VERSION ""

NS_ :

BS_:

BU_: VMCU TECU OBDScanT2 IC3 EMS ECUspare2 ECUspare1 DACU CIOM BBM

BO_ 2147484474 VMCU_BB2_20P: 8 VMCU
 SG_ StartupProhibitStatus_ISig_4 : 8|2@1+ (1,0) [0|0] ""  BBM,IC3
 SG_ RampLevelStatus_ISig_4 : 32|4@1+ (1,0) [0|0] ""  IC3,CIOM
 SG_ KneelingInformation_ISig_4 : 42|4@1+ (1,0) [0|0] ""  BBM,IC3,CIOM
 SG_ FrontAxleInBumperRange_ISig_4 : 40|2@1+ (1,0) [0|0] ""  TECU
 SG_ FerryFunctionStatus_ISig_4 : 2|3@1+ (1,0) [0|0] ""  IC3,CIOM
 SG_ EngPtoConsumesTorque : 10|2@1+ (1,0) [0|0] ""  TECU
 SG_ LiftingControlModeRearAxle_ISig_ : 36|2@1+ (1,0) [0|0] ""  BBM
 SG_ KneelingStatusHMI_ISig_4 : 53|2@1+ (1,0) [0|0] ""  BBM,CIOM
 SG_ SWEngineStop_rqst_ISig_4 : 12|3@1+ (1,0) [0|0] ""  BBM
 SG_ FrontEndPositionStatus_ISig_4 : 18|3@1+ (1,0) [0|0] ""  CIOM
 SG_ LiftingControlModeFrontAxle_ISig : 30|2@1+ (1,0) [0|0] ""  BBM
 SG_ FrontAxleInBumperRange_UB_ISig_4 : 46|1@1+ (1,0) [0|0] ""  TECU,IC3
 SG_ UnevenLoadWarning_ISig_4 : 16|2@1+ (1,0) [0|0] ""  IC3
 SG_ RampHeightOutsideTargetRange_ISi : 27|3@1+ (1,0) [0|0] ""  IC3,CIOM
 SG_ DriveLevelPosUserInteraction_ISi : 48|3@1+ (1,0) [0|0] ""  IC3
 SG_ RearEndPositionStatus_ISig_4 : 24|3@1+ (1,0) [0|0] ""  TECU,CIOM
 SG_ ProhibitControlStatus_ISig_4 : 6|2@1+ (1,0) [0|0] ""  IC3,BBM
 SG_ ChangeKneelACK_ISig_4 : 51|2@1+ (1,0) [0|0] ""  CIOM
 SG_ ParkBrakeApplicationMode2 : 60|4@1+ (1,0) [0|0] ""  IC3
 SG_ RollEndPositionStatus_ISig_4 : 21|3@1+ (1,0) [0|0] ""  CIOM
 SG_ RearAxleInBumperRange_UB_ISig_4 : 47|1@1+ (1,0) [0|0] ""  TECU,IC3
 SG_ ParkBrakeReleaseMode2_ISig_4 : 56|4@1+ (1,0) [0|0] ""  IC3
 SG_ ECSStandbyAllowed_ISig_4 : 0|2@1+ (1,0) [0|0] ""  CIOM
 SG_ RearAxleInBumperRange_ISig_4 : 38|2@1+ (1,0) [0|0] ""  TECU

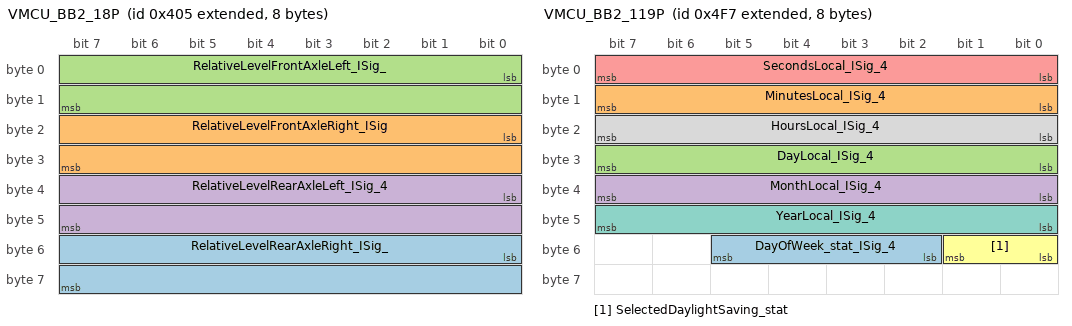
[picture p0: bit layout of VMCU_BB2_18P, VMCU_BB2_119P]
BO_ 2147484677 VMCU_BB2_18P: 8 VMCU
 SG_ RelativeLevelRearAxleRight_ISig_ : 48|16@1+ (0.1,-3200) [-3200|3353.5] "mm"  BBM
 SG_ RelativeLevelFrontAxleRight_ISig : 16|16@1+ (0.1,-3200) [-3200|3353.5] "mm"  BBM
 SG_ RelativeLevelFrontAxleLeft_ISig_ : 0|16@1+ (0.1,-3200) [-3200|3353.5] "mm"  BBM
 SG_ RelativeLevelRearAxleLeft_ISig_4 : 32|16@1+ (0.1,-3200) [-3200|3353.5] "mm"  BBM

BO_ 2147485245 VMCU_BB2_140P_FCM: 8 IC3
 SG_ VMCU_BB2_140P_FCS : 0|64@1+ (1,0) [0|0] ""  VMCU

BO_ 2147485244 VMCU_BB2_140P: 21 VMCU
 SG_ SavedUnit20_TrailerName : 0|160@1+ (1,0) [0|0] ""  IC3
 SG_ SavedUnit20_TrailerPosition : 160|3@1+ (1,0) [0|0] ""  IC3

BO_ 2147485243 VMCU_BB2_139P_FCM: 8 IC3
 SG_ VMCU_BB2_139P_FCS : 0|64@1+ (1,0) [0|0] ""  VMCU

BO_ 2147485242 VMCU_BB2_139P: 21 VMCU
 SG_ SavedUnit19_TrailerName : 0|160@1+ (1,0) [0|0] ""  IC3
 SG_ SavedUnit19_TrailerPosition : 160|3@1+ (1,0) [0|0] ""  IC3

BO_ 2147485241 VMCU_BB2_138P_FCM: 8 IC3
 SG_ VMCU_BB2_138P_FCS : 0|64@1+ (1,0) [0|0] ""  VMCU

BO_ 2147485240 VMCU_BB2_138P: 21 VMCU
 SG_ SavedUnit18_TrailerPosition : 160|3@1+ (1,0) [0|0] ""  IC3
 SG_ SavedUnit18_TrailerName : 0|160@1+ (1,0) [0|0] ""  IC3

BO_ 2147485239 VMCU_BB2_137P_FCM: 8 IC3
 SG_ VMCU_BB2_137P_FCS : 0|64@1+ (1,0) [0|0] ""  VMCU

BO_ 2147485238 VMCU_BB2_137P: 21 VMCU
 SG_ SavedUnit17_TrailerPosition : 160|3@1+ (1,0) [0|0] ""  IC3
 SG_ SavedUnit17_TrailerName : 0|160@1+ (1,0) [0|0] ""  IC3

BO_ 2147485237 VMCU_BB2_136P_FCM: 8 IC3
 SG_ VMCU_BB2_136P_FCS : 0|64@1+ (1,0) [0|0] ""  VMCU

BO_ 2147485236 VMCU_BB2_136P: 21 VMCU
 SG_ SavedUnit16_TrailerName : 0|160@1+ (1,0) [0|0] ""  IC3
 SG_ SavedUnit16_TrailerPosition : 160|3@1+ (1,0) [0|0] ""  IC3

BO_ 2147485235 VMCU_BB2_135P_FCM: 8 IC3
 SG_ VMCU_BB2_135P_FCS : 0|64@1+ (1,0) [0|0] ""  VMCU

BO_ 2147485234 VMCU_BB2_135P: 21 VMCU
 SG_ SavedUnit15_TrailerName : 0|160@1+ (1,0) [0|0] ""  IC3
 SG_ SavedUnit15_TrailerPosition : 160|3@1+ (1,0) [0|0] ""  IC3

BO_ 2147485233 VMCU_BB2_134P_FCM: 8 IC3
 SG_ VMCU_BB2_134P_FCS : 0|64@1+ (1,0) [0|0] ""  VMCU

BO_ 2147485232 VMCU_BB2_134P: 21 VMCU
 SG_ SavedUnit14_TrailerPosition : 160|3@1+ (1,0) [0|0] ""  IC3
 SG_ SavedUnit14_TrailerName : 0|160@1+ (1,0) [0|0] ""  IC3

BO_ 2147485225 VMCU_BB2_133P_FCM: 8 IC3
 SG_ VMCU_BB2_133P_FCS : 0|64@1+ (1,0) [0|0] ""  VMCU

BO_ 2147485224 VMCU_BB2_133P: 21 VMCU
 SG_ SavedUnit13_TrailerPosition : 160|3@1+ (1,0) [0|0] ""  IC3
 SG_ SavedUnit13_TrailerName : 0|160@1+ (1,0) [0|0] ""  IC3

BO_ 2147485223 VMCU_BB2_132P_FCM: 8 IC3
 SG_ VMCU_BB2_132P_FCS : 0|64@1+ (1,0) [0|0] ""  VMCU

BO_ 2147485222 VMCU_BB2_132P: 21 VMCU
 SG_ SavedUnit12_TrailerName : 0|160@1+ (1,0) [0|0] ""  IC3
 SG_ SavedUnit12_TrailerPosition : 160|3@1+ (1,0) [0|0] ""  IC3

BO_ 2147485221 VMCU_BB2_131P_FCM: 8 IC3
 SG_ VMCU_BB2_131P_FCS : 0|64@1+ (1,0) [0|0] ""  VMCU

BO_ 2147485220 VMCU_BB2_131P: 21 VMCU
 SG_ SavedUnit11_TrailerPosition : 160|3@1+ (1,0) [0|0] ""  IC3
 SG_ SavedUnit11_TrailerName : 0|160@1+ (1,0) [0|0] ""  IC3

BO_ 2147485219 VMCU_BB2_130P_FCM: 8 IC3
 SG_ VMCU_BB2_130P_FCS : 0|64@1+ (1,0) [0|0] ""  VMCU

BO_ 2147485218 VMCU_BB2_130P: 21 VMCU
 SG_ SavedUnit10_TrailerName : 0|160@1+ (1,0) [0|0] ""  IC3
 SG_ SavedUnit10_TrailerPosition : 160|3@1+ (1,0) [0|0] ""  IC3

BO_ 2147485217 VMCU_BB2_129P_FCM: 8 IC3
 SG_ VMCU_BB2_129P_FCS : 0|64@1+ (1,0) [0|0] ""  VMCU

BO_ 2147485216 VMCU_BB2_129P: 21 VMCU
 SG_ SavedUnit9_TrailerName : 0|160@1+ (1,0) [0|0] ""  IC3
 SG_ SavedUnit9_TrailerPosition : 160|3@1+ (1,0) [0|0] ""  IC3

BO_ 2147485215 VMCU_BB2_128P_FCM: 8 IC3
 SG_ VMCU_BB2_128P_FCS : 0|64@1+ (1,0) [0|0] ""  VMCU

BO_ 2147485214 VMCU_BB2_128P: 21 VMCU
 SG_ SavedUnit8_TrailerName : 0|160@1+ (1,0) [0|0] ""  IC3
 SG_ SavedUnit8_TrailerPosition : 160|3@1+ (1,0) [0|0] ""  IC3

BO_ 2147485213 VMCU_BB2_127P_FCM: 8 IC3
 SG_ VMCU_BB2_127P_FCS : 0|64@1+ (1,0) [0|0] ""  VMCU

BO_ 2147485212 VMCU_BB2_127P: 21 VMCU
 SG_ SavedUnit7_TrailerPosition : 160|3@1+ (1,0) [0|0] ""  IC3
 SG_ SavedUnit7_TrailerName : 0|160@1+ (1,0) [0|0] ""  IC3

BO_ 2147485211 VMCU_BB2_126P_FCM: 8 IC3
 SG_ VMCU_BB2_126P_FCS : 0|64@1+ (1,0) [0|0] ""  VMCU

BO_ 2147485210 VMCU_BB2_126P: 21 VMCU
 SG_ SavedUnit6_TrailerPosition : 160|3@1+ (1,0) [0|0] ""  IC3
 SG_ SavedUnit6_TrailerName : 0|160@1+ (1,0) [0|0] ""  IC3

BO_ 2147485209 VMCU_BB2_125P_FCM: 8 IC3
 SG_ VMCU_BB2_125P_FCS : 0|64@1+ (1,0) [0|0] ""  VMCU

BO_ 2147485208 VMCU_BB2_125P: 21 VMCU
 SG_ SavedUnit5_TrailerName : 0|160@1+ (1,0) [0|0] ""  IC3
 SG_ SavedUnit5_TrailerPosition : 160|3@1+ (1,0) [0|0] ""  IC3

BO_ 2147485207 VMCU_BB2_124P_FCM: 8 IC3
 SG_ VMCU_BB2_124P_FCS : 0|64@1+ (1,0) [0|0] ""  VMCU

BO_ 2147485206 VMCU_BB2_124P: 21 VMCU
 SG_ SavedUnit4_TrailerPosition : 160|3@1+ (1,0) [0|0] ""  IC3
 SG_ SavedUnit4_TrailerName : 0|160@1+ (1,0) [0|0] ""  IC3

BO_ 2147485205 VMCU_BB2_123P_FCM: 8 IC3
 SG_ VMCU_BB2_123P_FCS : 0|64@1+ (1,0) [0|0] ""  VMCU

BO_ 2147485204 VMCU_BB2_123P: 21 VMCU
 SG_ SavedUnit3_TrailerPosition : 160|3@1+ (1,0) [0|0] ""  IC3
 SG_ SavedUnit3_TrailerName : 0|160@1+ (1,0) [0|0] ""  IC3

BO_ 2147485203 VMCU_BB2_122P_FCM: 8 IC3
 SG_ VMCU_BB2_122P_FCS : 0|64@1+ (1,0) [0|0] ""  VMCU

BO_ 2147485202 VMCU_BB2_122P: 21 VMCU
 SG_ SavedUnit2_TrailerName : 0|160@1+ (1,0) [0|0] ""  IC3
 SG_ SavedUnit2_TrailerPosition : 160|3@1+ (1,0) [0|0] ""  IC3

BO_ 2147485201 VMCU_BB2_121P_FCM: 8 IC3
 SG_ VMCU_BB2_121P_FCS : 0|64@1+ (1,0) [0|0] ""  VMCU

BO_ 2147485200 VMCU_BB2_121P: 21 VMCU
 SG_ SavedUnit1_TrailerPosition : 160|3@1+ (1,0) [0|0] ""  IC3
 SG_ SavedUnit1_TrailerName : 0|160@1+ (1,0) [0|0] ""  IC3

BO_ 2147485090 VMCU_BB2_120S_FCM: 8 IC3
 SG_ VMCU_BB2_120S_FCS : 0|64@1+ (1,0) [0|0] ""  VMCU

BO_ 2147485089 VMCU_BB2_120S: 18 VMCU
 SG_ RenameTrailerAutoRqst_TrailerVIN : 0|136@1+ (1,0) [0|0] ""  IC3
 SG_ RenameTrailerAutoRqst_Request : 139|2@1+ (1,0) [0|0] ""  IC3
 SG_ RenameTrailerAutoRqst_sg_UB : 141|1@1+ (1,0) [0|0] ""  IC3
 SG_ RenameTrailerAutoRqst_Position : 136|3@1+ (1,0) [0|0] ""  IC3

BO_ 2147484941 VMCU_BB2_11P: 8 VMCU
 SG_ RSLAssistStatus : 24|3@1+ (1,0) [0|0] ""  TECU

BO_ 2147484919 VMCU_BB2_119P: 8 VMCU
 SG_ DayOfWeek_stat_ISig_4 : 50|4@1+ (1,0) [0|0] ""  IC3,CIOM
 SG_ MinutesLocal_ISig_4 : 8|8@1+ (1,0) [0|255] "min"  IC3,CIOM
 SG_ DayLocal_ISig_4 : 24|8@1+ (0.25,0) [0|63.75] "Days"  IC3,CIOM
 SG_ MonthLocal_ISig_4 : 32|8@1+ (1,0) [0|255] "Months"  IC3,CIOM
 SG_ SecondsLocal_ISig_4 : 0|8@1+ (0.25,0) [0|63.75] "s"  IC3,CIOM
 SG_ SelectedDaylightSaving_stat : 48|2@1+ (1,0) [0|0] ""  IC3
 SG_ YearLocal_ISig_4 : 40|8@1+ (1,1985) [1985|2240] "Years"  CIOM,IC3
 SG_ HoursLocal_ISig_4 : 16|8@1+ (1,0) [0|255] "h"  IC3,CIOM

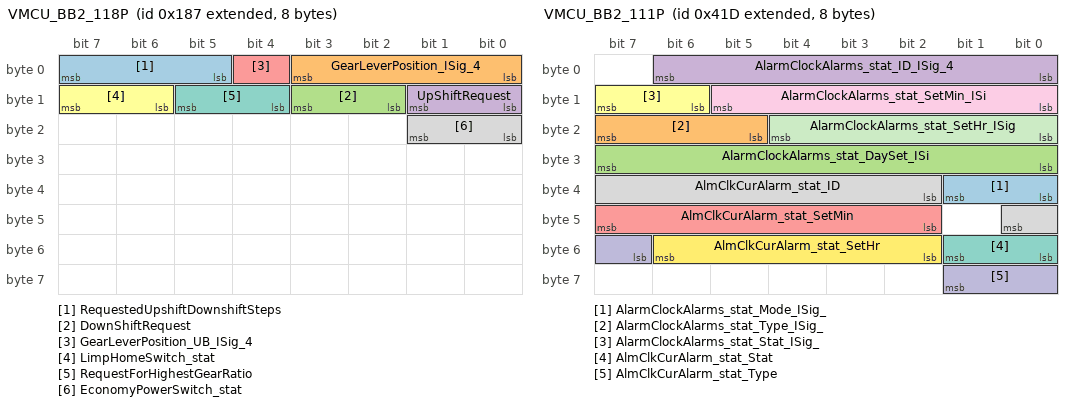
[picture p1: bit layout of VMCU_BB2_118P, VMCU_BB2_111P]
BO_ 2147484039 VMCU_BB2_118P: 8 VMCU
 SG_ RequestedUpshiftDownshiftSteps : 5|3@1+ (1,0) [0|0] ""  TECU
 SG_ GearLeverPosition_ISig_4 : 0|4@1+ (1,0) [0|0] ""  TECU,BBM,IC3
 SG_ DownShiftRequest : 10|2@1+ (1,0) [0|0] ""  TECU
 SG_ UpShiftRequest : 8|2@1+ (1,0) [0|0] ""  TECU
 SG_ GearLeverPosition_UB_ISig_4 : 4|1@1+ (1,0) [0|0] ""  BBM,IC3,TECU
 SG_ LimpHomeSwitch_stat : 14|2@1+ (1,0) [0|0] ""  TECU
 SG_ RequestForHighestGearRatio : 12|2@1+ (1,0) [0|0] ""  TECU
 SG_ EconomyPowerSwitch_stat : 16|2@1+ (1,0) [0|0] ""  TECU

BO_ 2147484975 VMCU_BB2_117P: 8 VMCU
 SG_ FuelLostInWrongGear : 0|32@1+ (0.01,0) [0|42949672.95] "l"  IC3
 SG_ FuelSavedInCoasting : 32|32@1+ (0.01,0) [0|42949672.95] "l"  IC3

BO_ 2147484974 VMCU_BB2_116S_FCM: 8 IC3
 SG_ VMCU_BB2_116S_FCS : 0|64@1+ (1,0) [0|0] ""  VMCU

BO_ 2147484969 VMCU_BB2_116S: 12 VMCU
 SG_ CalDataLoadP5_ScaleLoad : 63|16@1+ (0.5,0) [0|32767.5] "kg"  IC3
 SG_ CalDataLoadP5_UncalLoad : 47|16@1+ (0.5,0) [0|32767.5] "kg"  IC3
 SG_ CalDataLoadP5_sg_UB : 95|1@1+ (1,0) [0|0] ""  IC3
 SG_ CalDataLoadP5_YearUTC : 23|8@1+ (1,1985) [1985|2240] "Years"  IC3
 SG_ CalDataLoadP5_VehicleID : 4|3@1+ (1,0) [0|0] ""  IC3
 SG_ CalDataLoadP5_AxleID : 0|4@1+ (1,0) [0|0] ""  IC3
 SG_ CalDataLoadP5_DayUTC : 15|8@1+ (0.25,0) [0|63.75] "Days"  IC3
 SG_ CalDataLoadP5_HoursUTC : 31|8@1+ (1,0) [0|255] "h"  IC3
 SG_ CalDataLoadP5_MinutesUTC : 39|8@1+ (1,0) [0|255] "min"  IC3
 SG_ CalDataLoadP5_QF : 79|16@1+ (1,0) [0|0] ""  IC3
 SG_ CalDataLoadP5_MonthUTC : 7|8@1+ (1,0) [0|255] "Months"  IC3

BO_ 2147484973 VMCU_BB2_115S_FCM: 8 IC3
 SG_ VMCU_BB2_115S_FCS : 0|64@1+ (1,0) [0|0] ""  VMCU

BO_ 2147484968 VMCU_BB2_115S: 12 VMCU
 SG_ CalDataLoadP4_DayUTC : 7|8@1+ (0.25,0) [0|63.75] "Days"  IC3
 SG_ CalDataLoadP4_ScaleLoad : 47|16@1+ (0.5,0) [0|32767.5] "kg"  IC3
 SG_ CalDataLoadP4_sg_UB : 95|1@1+ (1,0) [0|0] ""  IC3
 SG_ CalDataLoadP4_YearUTC : 23|8@1+ (1,1985) [1985|2240] "Years"  IC3
 SG_ CalDataLoadP4_AxleID : 0|4@1+ (1,0) [0|0] ""  IC3
 SG_ CalDataLoadP4_UncalLoad : 63|16@1+ (0.5,0) [0|32767.5] "kg"  IC3
 SG_ CalDataLoadP4_VehicleID : 4|3@1+ (1,0) [0|0] ""  IC3
 SG_ CalDataLoadP4_MinutesUTC : 39|8@1+ (1,0) [0|255] "min"  IC3
 SG_ CalDataLoadP4_HoursUTC : 15|8@1+ (1,0) [0|255] "h"  IC3
 SG_ CalDataLoadP4_MonthUTC : 31|8@1+ (1,0) [0|255] "Months"  IC3
 SG_ CalDataLoadP4_QF : 79|16@1+ (1,0) [0|0] ""  IC3

BO_ 2147484972 VMCU_BB2_114S_FCM: 8 IC3
 SG_ VMCU_BB2_114S_FCS : 0|64@1+ (1,0) [0|0] ""  VMCU

BO_ 2147484967 VMCU_BB2_114S: 12 VMCU
 SG_ CalDataLoadP3_HoursUTC : 15|8@1+ (1,0) [0|255] "h"  IC3
 SG_ CalDataLoadP3_YearUTC : 7|8@1+ (1,1985) [1985|2240] "Years"  IC3
 SG_ CalDataLoadP3_MonthUTC : 39|8@1+ (1,0) [0|255] "Months"  IC3
 SG_ CalDataLoadP3_DayUTC : 23|8@1+ (0.25,0) [0|63.75] "Days"  IC3
 SG_ CalDataLoadP3_sg_UB : 95|1@1+ (1,0) [0|0] ""  IC3
 SG_ CalDataLoadP3_MinutesUTC : 31|8@1+ (1,0) [0|255] "min"  IC3
 SG_ CalDataLoadP3_QF : 79|16@1+ (1,0) [0|0] ""  IC3
 SG_ CalDataLoadP3_VehicleID : 4|3@1+ (1,0) [0|0] ""  IC3
 SG_ CalDataLoadP3_UncalLoad : 63|16@1+ (0.5,0) [0|32767.5] "kg"  IC3
 SG_ CalDataLoadP3_AxleID : 0|4@1+ (1,0) [0|0] ""  IC3
 SG_ CalDataLoadP3_ScaleLoad : 47|16@1+ (0.5,0) [0|32767.5] "kg"  IC3

BO_ 2147484971 VMCU_BB2_113S_FCM: 8 IC3
 SG_ VMCU_BB2_113S_FCS : 0|64@1+ (1,0) [0|0] ""  VMCU

BO_ 2147484966 VMCU_BB2_113S: 12 VMCU
 SG_ CalDataLoadP2_MinutesUTC : 39|8@1+ (1,0) [0|255] "min"  IC3
 SG_ CalDataLoadP2_AxleID : 0|4@1+ (1,0) [0|0] ""  IC3
 SG_ CalDataLoadP2_YearUTC : 15|8@1+ (1,1985) [1985|2240] "Years"  IC3
 SG_ CalDataLoadP2_UncalLoad : 63|16@1+ (0.5,0) [0|32767.5] "kg"  IC3
 SG_ CalDataLoadP2_DayUTC : 23|8@1+ (0.25,0) [0|63.75] "Days"  IC3
 SG_ CalDataLoadP2_MonthUTC : 7|8@1+ (1,0) [0|255] "Months"  IC3
 SG_ CalDataLoadP2_VehicleID : 4|3@1+ (1,0) [0|0] ""  IC3
 SG_ CalDataLoadP2_QF : 79|16@1+ (1,0) [0|0] ""  IC3
 SG_ CalDataLoadP2_HoursUTC : 31|8@1+ (1,0) [0|255] "h"  IC3
 SG_ CalDataLoadP2_sg_UB : 95|1@1+ (1,0) [0|0] ""  IC3
 SG_ CalDataLoadP2_ScaleLoad : 47|16@1+ (0.5,0) [0|32767.5] "kg"  IC3

BO_ 2147484970 VMCU_BB2_112S_FCM: 8 IC3
 SG_ VMCU_BB2_112S_FCS : 0|64@1+ (1,0) [0|0] ""  VMCU

BO_ 2147484965 VMCU_BB2_112S: 12 VMCU
 SG_ CalDataLoadP1_ScaleLoad : 47|16@1+ (0.5,0) [0|32767.5] "kg"  IC3
 SG_ CalDataLoadP1_YearUTC : 31|8@1+ (1,1985) [1985|2240] "Years"  IC3
 SG_ CalDataLoadP1_AxleID : 0|4@1+ (1,0) [0|0] ""  IC3
 SG_ CalDataLoadP1_MonthUTC : 39|8@1+ (1,0) [0|255] "Months"  IC3
 SG_ CalDataLoadP1_HoursUTC : 7|8@1+ (1,0) [0|255] "h"  IC3
 SG_ CalDataLoadP1_VehicleID : 4|3@1+ (1,0) [0|0] ""  IC3
 SG_ CalDataLoadP1_UncalLoad : 63|16@1+ (0.5,0) [0|32767.5] "kg"  IC3
 SG_ CalDataLoadP1_QF : 79|16@1+ (1,0) [0|0] ""  IC3
 SG_ CalDataLoadP1_DayUTC : 23|8@1+ (0.25,0) [0|63.75] "Days"  IC3
 SG_ CalDataLoadP1_sg_UB : 95|1@1+ (1,0) [0|0] ""  IC3
 SG_ CalDataLoadP1_MinutesUTC : 15|8@1+ (1,0) [0|255] "min"  IC3

BO_ 2147484701 VMCU_BB2_111P: 8 VMCU
 SG_ AlarmClockAlarms_stat_Mode_ISig_ : 32|2@1+ (1,0) [0|0] ""  CIOM,IC3
 SG_ AlarmClockAlarms_stat_Type_ISig_ : 21|3@1+ (1,0) [0|0] ""  IC3,CIOM
 SG_ AlarmClockAlarms_stat_DaySet_ISi : 24|8@1+ (1,0) [0|255] ""  IC3,CIOM
 SG_ AlarmClockAlarms_stat_ID_ISig_4 : 0|7@1+ (1,0) [0|0] ""  IC3,CIOM
 SG_ AlmClkCurAlarm_stat_SetMin : 42|6@1+ (1,0) [0|63] "min"  IC3,CIOM
 SG_ AlarmClockAlarms_stat_Stat_ISig_ : 14|2@1+ (1,0) [0|0] ""  IC3,CIOM
 SG_ AlmClkCurAlarm_stat_Stat : 48|2@1+ (1,0) [0|0] ""  CIOM,IC3
 SG_ AlmClkCurAlarm_stat_ID : 34|7@1+ (1,0) [0|0] ""  IC3,CIOM
 SG_ AlarmClockAlarms_stat_SetMin_ISi : 8|6@1+ (1,0) [0|63] "min"  IC3,CIOM
 SG_ AlmClkCurAlarm_stat_Type : 55|3@1+ (1,0) [0|0] ""  IC3,CIOM
 SG_ AlarmClockAlarms_stat_SetHr_ISig : 16|5@1+ (1,0) [0|31] "h"  CIOM,IC3
 SG_ AlmClkCurAlarm_stat_SetHr : 50|5@1+ (1,0) [0|31] "h"  IC3,CIOM

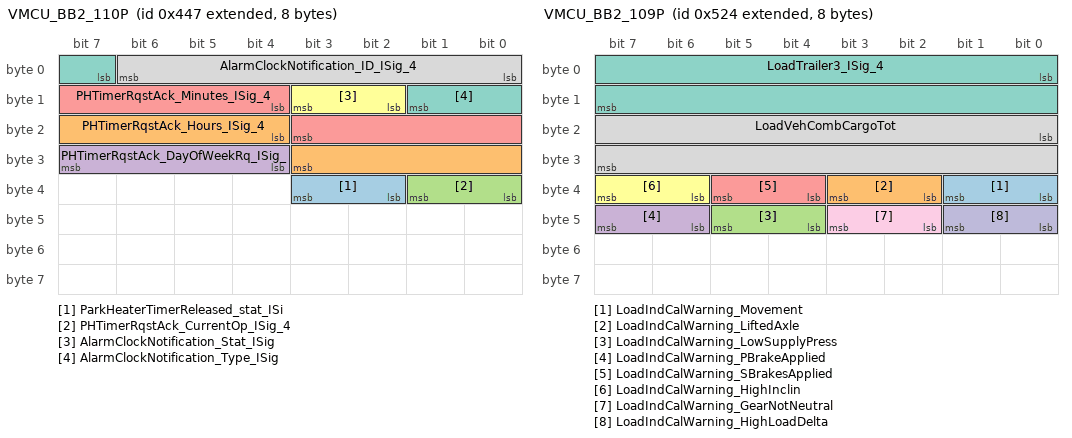
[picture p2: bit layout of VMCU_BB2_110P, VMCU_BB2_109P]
BO_ 2147484743 VMCU_BB2_110P: 8 VMCU
 SG_ ParkHeaterTimerReleased_stat_ISi : 34|2@1+ (1,0) [0|0] ""  CIOM
 SG_ PHTimerRqstAck_Hours_ISig_4 : 20|8@1+ (1,0) [0|255] "h"  CIOM
 SG_ PHTimerRqstAck_CurrentOp_ISig_4 : 32|2@1+ (1,0) [0|0] ""  CIOM
 SG_ PHTimerRqstAck_DayOfWeekRq_ISig_ : 28|4@1+ (1,0) [0|0] ""  CIOM
 SG_ PHTimerRqstAck_Minutes_ISig_4 : 12|8@1+ (1,0) [0|255] "min"  CIOM
 SG_ AlarmClockNotification_Stat_ISig : 10|2@1+ (1,0) [0|0] ""  CIOM,IC3
 SG_ AlarmClockNotification_Type_ISig : 7|3@1+ (1,0) [0|0] ""  IC3,CIOM
 SG_ AlarmClockNotification_ID_ISig_4 : 0|7@1+ (1,0) [0|0] ""  IC3,CIOM

BO_ 2147484921 VMCU_BB2_10P: 8 VMCU
 SG_ HighResolutionTripDistance2 : 32|32@1+ (5,0) [0|21474836475] "m"  IC3
 SG_ HighResolutionTripDistance1_ISig : 0|32@1+ (5,0) [0|21474836475] "m"  BBM,IC3

BO_ 2147484964 VMCU_BB2_109P: 8 VMCU
 SG_ LoadIndCalWarning_Movement : 32|2@1+ (1,0) [0|0] ""  IC3
 SG_ LoadIndCalWarning_LiftedAxle : 34|2@1+ (1,0) [0|0] ""  IC3
 SG_ LoadIndCalWarning_LowSupplyPress : 44|2@1+ (1,0) [0|0] ""  IC3
 SG_ LoadIndCalWarning_PBrakeApplied : 46|2@1+ (1,0) [0|0] ""  IC3
 SG_ LoadIndCalWarning_SBrakesApplied : 36|2@1+ (1,0) [0|0] ""  IC3
 SG_ LoadIndCalWarning_HighInclin : 38|2@1+ (1,0) [0|0] ""  IC3
 SG_ LoadTrailer3_ISig_4 : 0|16@1+ (2,0) [0|131070] "kg"  IC3,BBM,CIOM
 SG_ LoadVehCombCargoTot : 16|16@1+ (10,-40155) [-40155|615195] "kg"  BBM
 SG_ LoadIndCalWarning_GearNotNeutral : 42|2@1+ (1,0) [0|0] ""  IC3
 SG_ LoadIndCalWarning_HighLoadDelta : 40|2@1+ (1,0) [0|0] ""  IC3

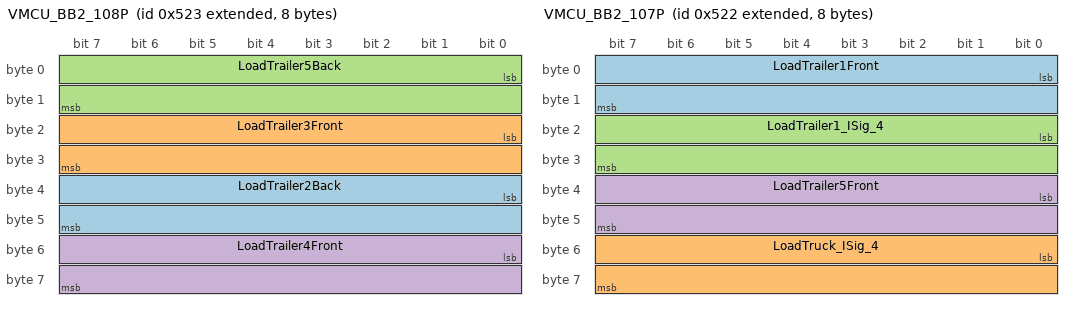
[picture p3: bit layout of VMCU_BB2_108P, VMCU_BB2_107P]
BO_ 2147484963 VMCU_BB2_108P: 8 VMCU
 SG_ LoadTrailer2Back : 32|16@1+ (2,0) [0|131070] "kg"  IC3
 SG_ LoadTrailer3Front : 16|16@1+ (2,0) [0|131070] "kg"  IC3
 SG_ LoadTrailer5Back : 0|16@1+ (2,0) [0|131070] "kg"  IC3
 SG_ LoadTrailer4Front : 48|16@1+ (2,0) [0|131070] "kg"  IC3

BO_ 2147484962 VMCU_BB2_107P: 8 VMCU
 SG_ LoadTrailer1Front : 0|16@1+ (2,0) [0|131070] "kg"  IC3
 SG_ LoadTruck_ISig_4 : 48|16@1+ (2,0) [0|131070] "kg"  IC3,CIOM,DACU,BBM
 SG_ LoadTrailer1_ISig_4 : 16|16@1+ (2,0) [0|131070] "kg"  BBM,IC3,CIOM
 SG_ LoadTrailer5Front : 32|16@1+ (2,0) [0|131070] "kg"  IC3

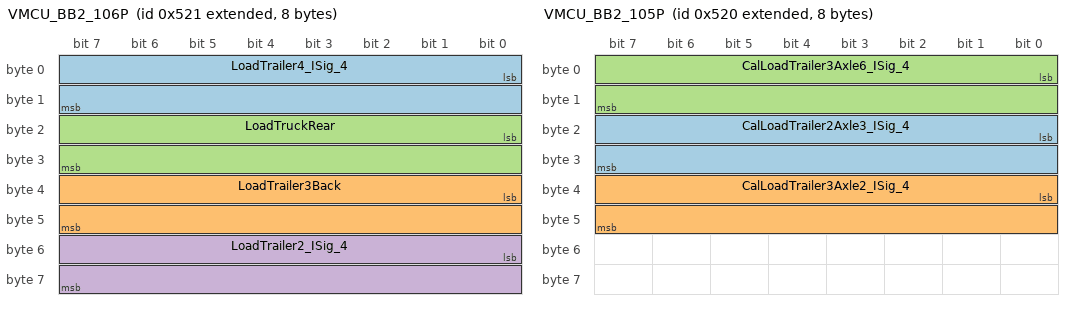
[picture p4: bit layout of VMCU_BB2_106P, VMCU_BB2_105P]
BO_ 2147484961 VMCU_BB2_106P: 8 VMCU
 SG_ LoadTrailer4_ISig_4 : 0|16@1+ (2,0) [0|131070] "kg"  IC3,BBM,CIOM
 SG_ LoadTrailer3Back : 32|16@1+ (2,0) [0|131070] "kg"  IC3
 SG_ LoadTruckRear : 16|16@1+ (2,0) [0|131070] "kg"  IC3
 SG_ LoadTrailer2_ISig_4 : 48|16@1+ (2,0) [0|131070] "kg"  BBM,CIOM,IC3

BO_ 2147484960 VMCU_BB2_105P: 8 VMCU
 SG_ CalLoadTrailer2Axle3_ISig_4 : 16|16@1+ (0.5,0) [0|32767.5] "kg"  IC3,CIOM,BBM
 SG_ CalLoadTrailer3Axle2_ISig_4 : 32|16@1+ (0.5,0) [0|32767.5] "kg"  IC3,CIOM
 SG_ CalLoadTrailer3Axle6_ISig_4 : 0|16@1+ (0.5,0) [0|32767.5] "kg"  IC3,CIOM

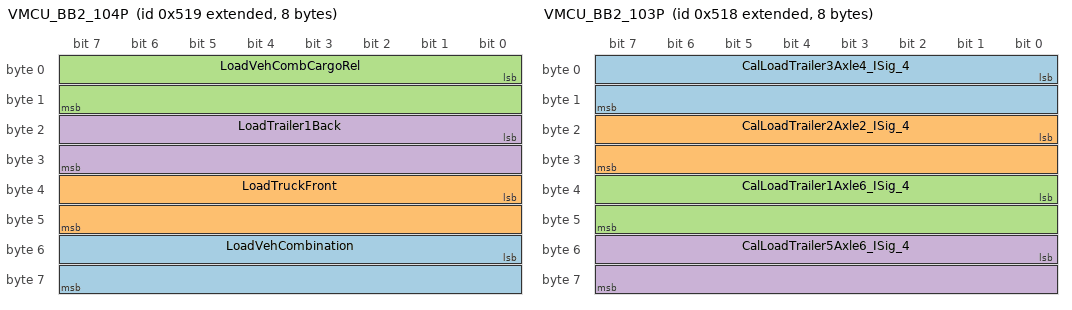
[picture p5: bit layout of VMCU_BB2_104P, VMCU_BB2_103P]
BO_ 2147484953 VMCU_BB2_104P: 8 VMCU
 SG_ LoadVehCombination : 48|16@1+ (10,0) [0|655350] "kg"  BBM,IC3
 SG_ LoadTruckFront : 32|16@1+ (2,0) [0|131070] "kg"  IC3
 SG_ LoadVehCombCargoRel : 0|16@1+ (10,-321270) [-321270|334080] "kg"  IC3
 SG_ LoadTrailer1Back : 16|16@1+ (2,0) [0|131070] "kg"  IC3

BO_ 2147484952 VMCU_BB2_103P: 8 VMCU
 SG_ CalLoadTrailer3Axle4_ISig_4 : 0|16@1+ (0.5,0) [0|32767.5] "kg"  CIOM,IC3
 SG_ CalLoadTrailer2Axle2_ISig_4 : 16|16@1+ (0.5,0) [0|32767.5] "kg"  CIOM,IC3,BBM
 SG_ CalLoadTrailer1Axle6_ISig_4 : 32|16@1+ (0.5,0) [0|32767.5] "kg"  CIOM,IC3
 SG_ CalLoadTrailer5Axle6_ISig_4 : 48|16@1+ (0.5,0) [0|32767.5] "kg"  CIOM,IC3

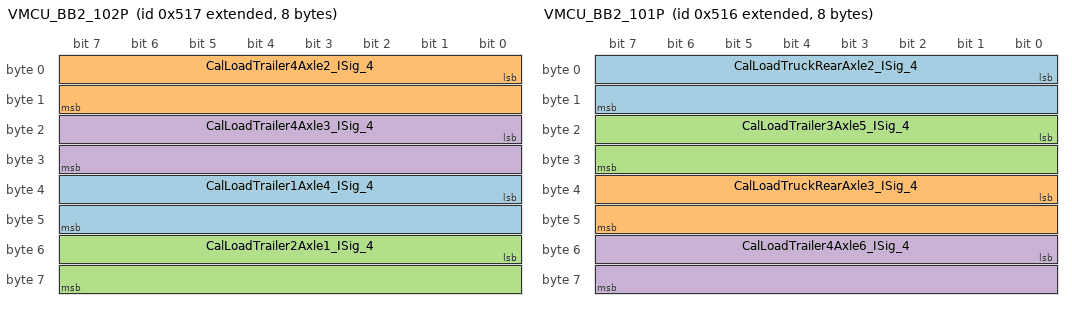
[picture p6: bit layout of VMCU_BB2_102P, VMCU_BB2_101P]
BO_ 2147484951 VMCU_BB2_102P: 8 VMCU
 SG_ CalLoadTrailer1Axle4_ISig_4 : 32|16@1+ (0.5,0) [0|32767.5] "kg"  IC3,CIOM,BBM
 SG_ CalLoadTrailer4Axle2_ISig_4 : 0|16@1+ (0.5,0) [0|32767.5] "kg"  CIOM,IC3
 SG_ CalLoadTrailer2Axle1_ISig_4 : 48|16@1+ (0.5,0) [0|32767.5] "kg"  CIOM,BBM,IC3
 SG_ CalLoadTrailer4Axle3_ISig_4 : 16|16@1+ (0.5,0) [0|32767.5] "kg"  CIOM,IC3

BO_ 2147484950 VMCU_BB2_101P: 8 VMCU
 SG_ CalLoadTruckRearAxle2_ISig_4 : 0|16@1+ (0.5,0) [0|32767.5] "kg"  BBM,IC3,CIOM
 SG_ CalLoadTruckRearAxle3_ISig_4 : 32|16@1+ (0.5,0) [0|32767.5] "kg"  BBM,CIOM,IC3
 SG_ CalLoadTrailer3Axle5_ISig_4 : 16|16@1+ (0.5,0) [0|32767.5] "kg"  IC3,CIOM
 SG_ CalLoadTrailer4Axle6_ISig_4 : 48|16@1+ (0.5,0) [0|32767.5] "kg"  IC3,CIOM

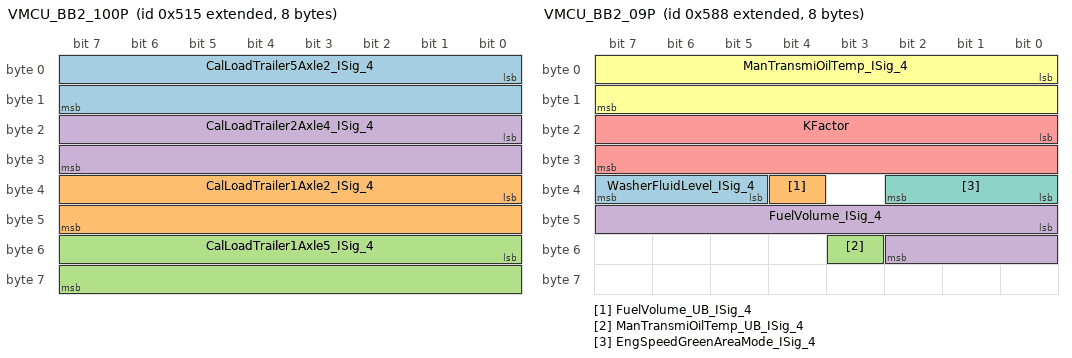
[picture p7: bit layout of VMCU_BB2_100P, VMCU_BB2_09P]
BO_ 2147484949 VMCU_BB2_100P: 8 VMCU
 SG_ CalLoadTrailer5Axle2_ISig_4 : 0|16@1+ (0.5,0) [0|32767.5] "kg"  CIOM,IC3
 SG_ CalLoadTrailer1Axle2_ISig_4 : 32|16@1+ (0.5,0) [0|32767.5] "kg"  IC3,CIOM,BBM
 SG_ CalLoadTrailer1Axle5_ISig_4 : 48|16@1+ (0.5,0) [0|32767.5] "kg"  IC3,CIOM
 SG_ CalLoadTrailer2Axle4_ISig_4 : 16|16@1+ (0.5,0) [0|32767.5] "kg"  CIOM,BBM,IC3

BO_ 2147485064 VMCU_BB2_09P: 8 VMCU
 SG_ WasherFluidLevel_ISig_4 : 37|3@1+ (1,0) [0|0] ""  IC3
 SG_ FuelVolume_UB_ISig_4 : 36|1@1+ (1,0) [0|0] ""  IC3
 SG_ ManTransmiOilTemp_UB_ISig_4 : 51|1@1+ (1,0) [0|0] ""  IC3
 SG_ FuelVolume_ISig_4 : 40|11@1+ (1,0) [0|2047] "l"  IC3
 SG_ KFactor : 16|16@1+ (1,0) [0|65535] "NotApplicable"  EMS,TECU,BBM,DACU
 SG_ ManTransmiOilTemp_ISig_4 : 0|16@1+ (0.03125,-273) [-273|1774.96875] "DegreeC"  IC3
 SG_ EngSpeedGreenAreaMode_ISig_4 : 32|3@1+ (1,0) [0|0] ""  IC3

BO_ 2147484698 VMCU_BB2_08P: 8 VMCU
 SG_ CabRoofSignLightFeedback_stat : 52|2@1+ (1,0) [0|0] ""  CIOM
 SG_ TemporaryRSLStatus : 54|2@1+ (1,0) [0|0] ""  CIOM
 SG_ CabExtraSideWrknLightFdbk_stat_I : 4|2@1+ (1,0) [0|0] ""  CIOM,BBM
 SG_ CabWrknLightChassisFdbk_stat_ISi : 10|2@1+ (1,0) [0|0] ""  BBM,CIOM
 SG_ CabTrailerBodyLgthnFdbk_stat : 8|2@1+ (1,0) [0|0] ""  CIOM
 SG_ DiffLockInterWhlStatusSplitBox_I : 56|2@1+ (1,0) [0|0] ""  BBM
 SG_ BodyOrCabWorkingLightFdbk_stat_I : 0|2@1+ (1,0) [0|0] ""  CIOM,BBM
 SG_ WheelBasedVehicleSpeedLowRes_ISi : 32|8@1+ (1,0) [0|255] "Km_per_h"  CIOM
 SG_ AirDryerCoolingFanSpeed_rqst : 16|16@1+ (1,0) [0|65535] "rpm"  EMS
 SG_ CabFrontSpotFeedback_Status : 6|2@1+ (1,0) [0|0] ""  CIOM
 SG_ CabTiltEnableStatus : 2|2@1+ (1,0) [0|0] ""  CIOM
 SG_ TransmReverseDirectionSw_stat_IS : 58|2@1+ (1,0) [0|0] ""  BBM
 SG_ CabRoofSpotFeedback_Status : 12|2@1+ (1,0) [0|0] ""  CIOM
 SG_ CabBeaconLightFeedback_Status_IS : 50|2@1+ (1,0) [0|0] ""  CIOM,BBM
 SG_ ExtraAxleSteeringFunctionStat_IS : 60|3@1+ (1,0) [0|0] ""  CIOM
 SG_ AirDryerCoolingFanSpeed_rqst_UB : 48|1@1+ (1,0) [0|0] ""  EMS
 SG_ CabTiltLockStatus_ISig_4 : 14|2@1+ (1,0) [0|0] ""  BBM,IC3
 SG_ PositionLightRearLamp_stat_ISig_ : 45|3@1+ (1,0) [0|0] ""  IC3

CM_ SG_ 2147484677 RelativeLevelRearAxleRight_ISig_ "65024 - 65279 Error ; 65280 - 65535 Not available";
CM_ SG_ 2147484677 RelativeLevelFrontAxleRight_ISig "65024 - 65279 Error ; 65280 - 65535 Not available";
CM_ SG_ 2147484677 RelativeLevelFrontAxleLeft_ISig_ "65024 - 65279 Error ; 65280 - 65535 Not available";
CM_ SG_ 2147484677 RelativeLevelRearAxleLeft_ISig_4 "65024 - 65279 Error ; 65280 - 65535 Not available";
CM_ SG_ 2147484919 MinutesLocal_ISig_4 "254 Error ; 255 Not available";
CM_ SG_ 2147484919 DayLocal_ISig_4 "254 Error ; 255 Not available";
CM_ SG_ 2147484919 MonthLocal_ISig_4 "254 Error ; 255 Not available";
CM_ SG_ 2147484919 SecondsLocal_ISig_4 "254 Error ; 255 Not available";
CM_ SG_ 2147484919 YearLocal_ISig_4 "254 Error ; 255 Not available";
CM_ SG_ 2147484919 HoursLocal_ISig_4 "254 Error ; 255 Not available";
CM_ SG_ 2147484701 AlmClkCurAlarm_stat_SetMin "62 Error ; 63 Not Available";
CM_ SG_ 2147484701 AlarmClockAlarms_stat_SetMin_ISi "62 Error ; 63 Not Available";
CM_ SG_ 2147484701 AlarmClockAlarms_stat_SetHr_ISig "30 Error ; 31 Not Available";
CM_ SG_ 2147484701 AlmClkCurAlarm_stat_SetHr "30 Error ; 31 Not Available";
CM_ SG_ 2147484921 HighResolutionTripDistance2 "4261412864 - 4278190079 Error ; 4278190080 - 4294967295 Not available";
CM_ SG_ 2147484921 HighResolutionTripDistance1_ISig "4261412864 - 4278190079 Error ; 4278190080 - 4294967295 Not available";
CM_ SG_ 2147485064 KFactor "65024 - 65279 Error ; 65280 - 65535 Not available";
CM_ SG_ 2147485064 ManTransmiOilTemp_ISig_4 "65024 - 65279 Error ; 65280 - 65535 Not available";
CM_ SG_ 2147484698 WheelBasedVehicleSpeedLowRes_ISi "254 Error ; 255 Not available";
CM_ SG_ 2147484698 AirDryerCoolingFanSpeed_rqst "65024 - 65279 Error ; 65280 - 65535 Not available";
BA_DEF_ BO_  "GenMsgStartDelayTime" INT 0 0;
BA_DEF_ BO_  "GenMsgDelayTime" INT 0 0;
BA_DEF_ BO_  "GenMsgCycleTime" INT 0 0;
BA_DEF_ BO_  "GenMsgSendType" ENUM  "Cyclic","NotUsed","NotUsed","NotUsed","NotUsed","NotUsed","NotUsed","IfActive","NoMsgSendType","NotUsed";
BA_DEF_ SG_  "GenSigStartValue" INT 0 0;
BA_DEF_ SG_  "GenSigCycleTimeActive" INT 0 0;
BA_DEF_ SG_  "GenSigCycleTime" INT 0 0;
BA_DEF_ SG_  "GenSigSendType" ENUM  "Cyclic","OnWrite","OnWriteWithRepetition","OnChange","OnChangeWithRepetition","IfActive","IfActiveWithRepetition","NoSigSendType","NotUsed","NotUsed","NotUsed","NotUsed","NotUsed";
BA_DEF_ BO_  "VFrameFormat" ENUM  "StandardCAN","ExtendedCAN","reserved","J1939PG";
BA_DEF_ SG_  "SigType" ENUM  "Default","Range","RangeSigned","ASCII","Discrete","Control","ReferencePGN","DTC","StringDelimiter","StringLength","StringLengthControl";
BA_DEF_ SG_  "SeToolVersion_SIGNAL" STRING ;
BA_DEF_ SG_  "SeToolUniqueID_SIGNAL" STRING ;
BA_DEF_ SG_  "SeToolOwnerSigGroup_SIGNAL" STRING ;
BA_DEF_ SG_  "SeToolOwnerSigGroupID_SIGNAL" STRING ;
BA_DEF_ SG_  "SeToolName_SIGNAL" STRING ;
BA_DEF_ SG_  "SeToolItemID_SIGNAL" STRING ;
BA_DEF_ SG_  "SeToolAncestorID_SIGNAL" STRING ;
BA_DEF_ SG_  "Platform_VMCU1_Sig" ENUM  "No","Yes";
BA_DEF_ BO_  "NmAsrMessage" ENUM  "No","Yes";
BA_DEF_ SG_  "NeedsUpdateBit" ENUM  "No","Yes";
BA_DEF_ SG_  "MmAnSignal" ENUM  "No","Yes";
BA_DEF_ SG_  "GenSigMaxLatency" INT 0 65535;
BA_DEF_ SG_  "GenSigILSupport" ENUM  "Yes","No";
BA_DEF_ BO_  "GenMsgRequestable" INT 0 1;
BA_DEF_ BO_  "GenMsgILSupport" ENUM  "No","Yes";
BA_DEF_ BO_  "DiagUUDTResponse" ENUM  "No","Yes";
BA_DEF_ BO_  "DiagState" ENUM  "No","Yes";
BA_DEF_ BO_  "DiagResponse" ENUM  "No","Yes";
BA_DEF_ BO_  "DiagRequest" ENUM  "No","Yes";
BA_DEF_ BO_  "DiagConnection" HEX 0 65535;
BA_DEF_ BO_  "CanTpSTmin" INT 0 255;
BA_DEF_ BO_  "CanTpFcFrameId" HEX 0 2147483647;
BA_DEF_ BO_  "CanTpBs" INT 0 255;
BA_DEF_ SG_  "SystemSignalLongSymbol" STRING ;
BA_DEF_REL_ BU_SG_REL_  "GenSigTimeoutTime" INT 0 65535;
BA_DEF_REL_ BU_SG_REL_  "GenSigFirstTimeoutTime" INT 0 65535;
BA_DEF_DEF_  "GenMsgStartDelayTime" 0;
BA_DEF_DEF_  "GenMsgDelayTime" 0;
BA_DEF_DEF_  "GenMsgCycleTime" 0;
BA_DEF_DEF_  "GenMsgSendType" "Cyclic";
BA_DEF_DEF_  "GenSigStartValue" 0;
BA_DEF_DEF_  "GenSigCycleTimeActive" 0;
BA_DEF_DEF_  "GenSigCycleTime" 0;
BA_DEF_DEF_  "GenSigSendType" "Cyclic";
BA_DEF_DEF_  "VFrameFormat" "ExtendedCAN";
BA_DEF_DEF_  "SigType" "Default";
BA_DEF_DEF_  "SeToolVersion_SIGNAL" "";
BA_DEF_DEF_  "SeToolUniqueID_SIGNAL" "";
BA_DEF_DEF_  "SeToolOwnerSigGroup_SIGNAL" "";
BA_DEF_DEF_  "SeToolOwnerSigGroupID_SIGNAL" "";
BA_DEF_DEF_  "SeToolName_SIGNAL" "";
BA_DEF_DEF_  "SeToolItemID_SIGNAL" "";
BA_DEF_DEF_  "SeToolAncestorID_SIGNAL" "";
BA_DEF_DEF_  "Platform_VMCU1_Sig" "No";
BA_DEF_DEF_  "NmAsrMessage" "No";
BA_DEF_DEF_  "NeedsUpdateBit" "No";
BA_DEF_DEF_  "MmAnSignal" "No";
BA_DEF_DEF_  "GenSigMaxLatency" 0;
BA_DEF_DEF_  "GenSigILSupport" "Yes";
BA_DEF_DEF_  "GenMsgRequestable" 1;
BA_DEF_DEF_  "GenMsgILSupport" "Yes";
BA_DEF_DEF_  "DiagUUDTResponse" "No";
BA_DEF_DEF_  "DiagState" "No";
BA_DEF_DEF_  "DiagResponse" "No";
BA_DEF_DEF_  "DiagRequest" "No";
BA_DEF_DEF_  "DiagConnection" 0;
BA_DEF_DEF_  "CanTpSTmin" 0;
BA_DEF_DEF_  "CanTpFcFrameId" 2147483647;
BA_DEF_DEF_  "CanTpBs" 255;
BA_DEF_DEF_REL_ "GenSigTimeoutTime" 0;
BA_DEF_DEF_REL_ "GenSigFirstTimeoutTime" 0;
BA_DEF_DEF_  "SystemSignalLongSymbol" "";
BA_ "GenMsgCycleTime" BO_ 2147484474 50;
BA_ "GenMsgStartDelayTime" BO_ 2147484474 20;
BA_ "GenMsgCycleTime" BO_ 2147484677 100;
BA_ "GenMsgStartDelayTime" BO_ 2147484677 15;
BA_ "GenMsgILSupport" BO_ 2147485245 0;
BA_ "GenMsgSendType" BO_ 2147485245 8;
BA_ "CanTpFcFrameId" BO_ 2147485244 1597;
BA_ "GenMsgCycleTime" BO_ 2147485244 10000;
BA_ "GenMsgStartDelayTime" BO_ 2147485244 2250;
BA_ "GenMsgILSupport" BO_ 2147485243 0;
BA_ "GenMsgSendType" BO_ 2147485243 8;
BA_ "CanTpFcFrameId" BO_ 2147485242 1595;
BA_ "GenMsgCycleTime" BO_ 2147485242 10000;
BA_ "GenMsgStartDelayTime" BO_ 2147485242 2155;
BA_ "GenMsgILSupport" BO_ 2147485241 0;
BA_ "GenMsgSendType" BO_ 2147485241 8;
BA_ "CanTpFcFrameId" BO_ 2147485240 1593;
BA_ "GenMsgCycleTime" BO_ 2147485240 10000;
BA_ "GenMsgStartDelayTime" BO_ 2147485240 2050;
BA_ "GenMsgILSupport" BO_ 2147485239 0;
BA_ "GenMsgSendType" BO_ 2147485239 8;
BA_ "CanTpFcFrameId" BO_ 2147485238 1591;
BA_ "GenMsgCycleTime" BO_ 2147485238 10000;
BA_ "GenMsgStartDelayTime" BO_ 2147485238 1955;
BA_ "GenMsgILSupport" BO_ 2147485237 0;
BA_ "GenMsgSendType" BO_ 2147485237 8;
BA_ "CanTpFcFrameId" BO_ 2147485236 1589;
BA_ "GenMsgCycleTime" BO_ 2147485236 10000;
BA_ "GenMsgStartDelayTime" BO_ 2147485236 1850;
BA_ "GenMsgILSupport" BO_ 2147485235 0;
BA_ "GenMsgSendType" BO_ 2147485235 8;
BA_ "CanTpFcFrameId" BO_ 2147485234 1587;
BA_ "GenMsgCycleTime" BO_ 2147485234 10000;
BA_ "GenMsgStartDelayTime" BO_ 2147485234 1700;
BA_ "GenMsgILSupport" BO_ 2147485233 0;
BA_ "GenMsgSendType" BO_ 2147485233 8;
BA_ "CanTpFcFrameId" BO_ 2147485232 1585;
BA_ "GenMsgCycleTime" BO_ 2147485232 10000;
BA_ "GenMsgStartDelayTime" BO_ 2147485232 1605;
BA_ "GenMsgILSupport" BO_ 2147485225 0;
BA_ "GenMsgSendType" BO_ 2147485225 8;
BA_ "CanTpFcFrameId" BO_ 2147485224 1577;
BA_ "GenMsgCycleTime" BO_ 2147485224 10000;
BA_ "GenMsgStartDelayTime" BO_ 2147485224 1500;
BA_ "GenMsgILSupport" BO_ 2147485223 0;
BA_ "GenMsgSendType" BO_ 2147485223 8;
BA_ "CanTpFcFrameId" BO_ 2147485222 1575;
BA_ "GenMsgCycleTime" BO_ 2147485222 10000;
BA_ "GenMsgStartDelayTime" BO_ 2147485222 1350;
BA_ "GenMsgILSupport" BO_ 2147485221 0;
BA_ "GenMsgSendType" BO_ 2147485221 8;
BA_ "CanTpFcFrameId" BO_ 2147485220 1573;
BA_ "GenMsgCycleTime" BO_ 2147485220 10000;
BA_ "GenMsgStartDelayTime" BO_ 2147485220 1255;
BA_ "GenMsgILSupport" BO_ 2147485219 0;
BA_ "GenMsgSendType" BO_ 2147485219 8;
BA_ "CanTpFcFrameId" BO_ 2147485218 1571;
BA_ "GenMsgCycleTime" BO_ 2147485218 10000;
BA_ "GenMsgStartDelayTime" BO_ 2147485218 1150;
BA_ "GenMsgILSupport" BO_ 2147485217 0;
BA_ "GenMsgSendType" BO_ 2147485217 8;
BA_ "CanTpFcFrameId" BO_ 2147485216 1569;
BA_ "GenMsgCycleTime" BO_ 2147485216 10000;
BA_ "GenMsgStartDelayTime" BO_ 2147485216 1000;
BA_ "GenMsgILSupport" BO_ 2147485215 0;
BA_ "GenMsgSendType" BO_ 2147485215 8;
BA_ "CanTpFcFrameId" BO_ 2147485214 1567;
BA_ "GenMsgCycleTime" BO_ 2147485214 10000;
BA_ "GenMsgStartDelayTime" BO_ 2147485214 905;
BA_ "GenMsgILSupport" BO_ 2147485213 0;
BA_ "GenMsgSendType" BO_ 2147485213 8;
BA_ "CanTpFcFrameId" BO_ 2147485212 1565;
BA_ "GenMsgCycleTime" BO_ 2147485212 10000;
BA_ "GenMsgStartDelayTime" BO_ 2147485212 800;
BA_ "GenMsgILSupport" BO_ 2147485211 0;
BA_ "GenMsgSendType" BO_ 2147485211 8;
BA_ "CanTpFcFrameId" BO_ 2147485210 1563;
BA_ "GenMsgCycleTime" BO_ 2147485210 10000;
BA_ "GenMsgStartDelayTime" BO_ 2147485210 650;
BA_ "GenMsgILSupport" BO_ 2147485209 0;
BA_ "GenMsgSendType" BO_ 2147485209 8;
BA_ "CanTpFcFrameId" BO_ 2147485208 1561;
BA_ "GenMsgCycleTime" BO_ 2147485208 10000;
BA_ "GenMsgStartDelayTime" BO_ 2147485208 555;
BA_ "GenMsgILSupport" BO_ 2147485207 0;
BA_ "GenMsgSendType" BO_ 2147485207 8;
BA_ "CanTpFcFrameId" BO_ 2147485206 1559;
BA_ "GenMsgCycleTime" BO_ 2147485206 10000;
BA_ "GenMsgStartDelayTime" BO_ 2147485206 400;
BA_ "GenMsgILSupport" BO_ 2147485205 0;
BA_ "GenMsgSendType" BO_ 2147485205 8;
BA_ "CanTpFcFrameId" BO_ 2147485204 1557;
BA_ "GenMsgCycleTime" BO_ 2147485204 10000;
BA_ "GenMsgStartDelayTime" BO_ 2147485204 305;
BA_ "GenMsgILSupport" BO_ 2147485203 0;
BA_ "GenMsgSendType" BO_ 2147485203 8;
BA_ "CanTpFcFrameId" BO_ 2147485202 1555;
BA_ "GenMsgCycleTime" BO_ 2147485202 10000;
BA_ "GenMsgStartDelayTime" BO_ 2147485202 200;
BA_ "GenMsgILSupport" BO_ 2147485201 0;
BA_ "GenMsgSendType" BO_ 2147485201 8;
BA_ "CanTpFcFrameId" BO_ 2147485200 1553;
BA_ "GenMsgCycleTime" BO_ 2147485200 10000;
BA_ "GenMsgStartDelayTime" BO_ 2147485200 100;
BA_ "GenMsgILSupport" BO_ 2147485090 0;
BA_ "GenMsgSendType" BO_ 2147485090 8;
BA_ "CanTpFcFrameId" BO_ 2147485089 1442;
BA_ "GenMsgSendType" BO_ 2147485089 8;
BA_ "GenMsgDelayTime" BO_ 2147485089 200;
BA_ "GenMsgCycleTime" BO_ 2147484941 250;
BA_ "GenMsgStartDelayTime" BO_ 2147484941 50;
BA_ "GenMsgCycleTime" BO_ 2147484919 200;
BA_ "GenMsgStartDelayTime" BO_ 2147484919 5;
BA_ "GenMsgCycleTime" BO_ 2147484039 20;
BA_ "GenMsgStartDelayTime" BO_ 2147484039 5;
BA_ "GenMsgCycleTime" BO_ 2147484975 1000;
BA_ "GenMsgILSupport" BO_ 2147484974 0;
BA_ "GenMsgSendType" BO_ 2147484974 8;
BA_ "CanTpFcFrameId" BO_ 2147484969 1326;
BA_ "GenMsgSendType" BO_ 2147484969 8;
BA_ "GenMsgDelayTime" BO_ 2147484969 100;
BA_ "GenMsgILSupport" BO_ 2147484973 0;
BA_ "GenMsgSendType" BO_ 2147484973 8;
BA_ "CanTpFcFrameId" BO_ 2147484968 1325;
BA_ "GenMsgSendType" BO_ 2147484968 8;
BA_ "GenMsgDelayTime" BO_ 2147484968 100;
BA_ "GenMsgILSupport" BO_ 2147484972 0;
BA_ "GenMsgSendType" BO_ 2147484972 8;
BA_ "CanTpFcFrameId" BO_ 2147484967 1324;
BA_ "GenMsgSendType" BO_ 2147484967 8;
BA_ "GenMsgDelayTime" BO_ 2147484967 100;
BA_ "GenMsgILSupport" BO_ 2147484971 0;
BA_ "GenMsgSendType" BO_ 2147484971 8;
BA_ "CanTpFcFrameId" BO_ 2147484966 1323;
BA_ "GenMsgSendType" BO_ 2147484966 8;
BA_ "GenMsgDelayTime" BO_ 2147484966 100;
BA_ "GenMsgILSupport" BO_ 2147484970 0;
BA_ "GenMsgSendType" BO_ 2147484970 8;
BA_ "CanTpFcFrameId" BO_ 2147484965 1322;
BA_ "GenMsgSendType" BO_ 2147484965 8;
BA_ "GenMsgDelayTime" BO_ 2147484965 100;
BA_ "GenMsgCycleTime" BO_ 2147484701 150;
BA_ "GenMsgStartDelayTime" BO_ 2147484701 45;
BA_ "GenMsgCycleTime" BO_ 2147484743 100;
BA_ "GenMsgStartDelayTime" BO_ 2147484743 35;
BA_ "GenMsgCycleTime" BO_ 2147484921 250;
BA_ "GenMsgStartDelayTime" BO_ 2147484921 190;
BA_ "GenMsgCycleTime" BO_ 2147484964 1000;
BA_ "GenMsgStartDelayTime" BO_ 2147484964 210;
BA_ "GenMsgCycleTime" BO_ 2147484963 1000;
BA_ "GenMsgStartDelayTime" BO_ 2147484963 205;
BA_ "GenMsgCycleTime" BO_ 2147484962 1000;
BA_ "GenMsgStartDelayTime" BO_ 2147484962 190;
BA_ "GenMsgCycleTime" BO_ 2147484961 1000;
BA_ "GenMsgStartDelayTime" BO_ 2147484961 180;
BA_ "GenMsgCycleTime" BO_ 2147484960 1000;
BA_ "GenMsgStartDelayTime" BO_ 2147484960 165;
BA_ "GenMsgCycleTime" BO_ 2147484953 1000;
BA_ "GenMsgStartDelayTime" BO_ 2147484953 145;
BA_ "GenMsgCycleTime" BO_ 2147484952 1000;
BA_ "GenMsgStartDelayTime" BO_ 2147484952 130;
BA_ "GenMsgCycleTime" BO_ 2147484951 1000;
BA_ "GenMsgStartDelayTime" BO_ 2147484951 120;
BA_ "GenMsgCycleTime" BO_ 2147484950 1000;
BA_ "GenMsgStartDelayTime" BO_ 2147484950 115;
BA_ "GenMsgCycleTime" BO_ 2147484949 1000;
BA_ "GenMsgStartDelayTime" BO_ 2147484949 105;
BA_ "GenMsgCycleTime" BO_ 2147485064 500;
BA_ "GenMsgStartDelayTime" BO_ 2147485064 125;
BA_ "GenMsgCycleTime" BO_ 2147484698 100;
BA_ "GenMsgStartDelayTime" BO_ 2147484698 65;
BA_ "GenSigCycleTime" SG_ 2147484474 StartupProhibitStatus_ISig_4 100;
BA_ "GenSigCycleTimeActive" SG_ 2147484474 StartupProhibitStatus_ISig_4 100;
BA_ "GenSigStartValue" SG_ 2147484474 StartupProhibitStatus_ISig_4 3;
BA_ "GenSigMaxLatency" SG_ 2147484474 StartupProhibitStatus_ISig_4 117;
BA_ "Platform_VMCU1_Sig" SG_ 2147484474 StartupProhibitStatus_ISig_4 1;
BA_ "GenSigCycleTime" SG_ 2147484474 RampLevelStatus_ISig_4 100;
BA_ "GenSigCycleTimeActive" SG_ 2147484474 RampLevelStatus_ISig_4 100;
BA_ "GenSigStartValue" SG_ 2147484474 RampLevelStatus_ISig_4 15;
BA_ "GenSigMaxLatency" SG_ 2147484474 RampLevelStatus_ISig_4 117;
BA_ "Platform_VMCU1_Sig" SG_ 2147484474 RampLevelStatus_ISig_4 1;
BA_ "GenSigCycleTime" SG_ 2147484474 KneelingInformation_ISig_4 100;
BA_ "GenSigCycleTimeActive" SG_ 2147484474 KneelingInformation_ISig_4 100;
BA_ "GenSigStartValue" SG_ 2147484474 KneelingInformation_ISig_4 15;
BA_ "Platform_VMCU1_Sig" SG_ 2147484474 KneelingInformation_ISig_4 1;
BA_ "GenSigCycleTime" SG_ 2147484474 FrontAxleInBumperRange_ISig_4 100;
BA_ "GenSigCycleTimeActive" SG_ 2147484474 FrontAxleInBumperRange_ISig_4 100;
BA_ "GenSigStartValue" SG_ 2147484474 FrontAxleInBumperRange_ISig_4 3;
BA_ "NeedsUpdateBit" SG_ 2147484474 FrontAxleInBumperRange_ISig_4 1;
BA_ "Platform_VMCU1_Sig" SG_ 2147484474 FrontAxleInBumperRange_ISig_4 1;
BA_ "SeToolAncestorID_SIGNAL" SG_ 2147484474 FrontAxleInBumperRange_ISig_4 "x0000001D04149915";
BA_ "SeToolItemID_SIGNAL" SG_ 2147484474 FrontAxleInBumperRange_ISig_4 "x0000001D04149915";
BA_ "SeToolName_SIGNAL" SG_ 2147484474 FrontAxleInBumperRange_ISig_4 "FrontAxleInBumperRange";
BA_ "SeToolVersion_SIGNAL" SG_ 2147484474 FrontAxleInBumperRange_ISig_4 "1";
BA_ "GenSigCycleTime" SG_ 2147484474 FerryFunctionStatus_ISig_4 100;
BA_ "GenSigCycleTimeActive" SG_ 2147484474 FerryFunctionStatus_ISig_4 100;
BA_ "GenSigStartValue" SG_ 2147484474 FerryFunctionStatus_ISig_4 7;
BA_ "GenSigMaxLatency" SG_ 2147484474 FerryFunctionStatus_ISig_4 117;
BA_ "Platform_VMCU1_Sig" SG_ 2147484474 FerryFunctionStatus_ISig_4 1;
BA_ "GenSigCycleTime" SG_ 2147484474 EngPtoConsumesTorque 100;
BA_ "GenSigCycleTimeActive" SG_ 2147484474 EngPtoConsumesTorque 100;
BA_ "GenSigStartValue" SG_ 2147484474 EngPtoConsumesTorque 3;
BA_ "Platform_VMCU1_Sig" SG_ 2147484474 EngPtoConsumesTorque 1;
BA_ "GenSigCycleTime" SG_ 2147484474 LiftingControlModeRearAxle_ISig_ 100;
BA_ "GenSigCycleTimeActive" SG_ 2147484474 LiftingControlModeRearAxle_ISig_ 100;
BA_ "GenSigStartValue" SG_ 2147484474 LiftingControlModeRearAxle_ISig_ 3;
BA_ "Platform_VMCU1_Sig" SG_ 2147484474 LiftingControlModeRearAxle_ISig_ 1;
BA_ "SeToolAncestorID_SIGNAL" SG_ 2147484474 LiftingControlModeRearAxle_ISig_ "x0000001D04149A4E";
BA_ "SeToolItemID_SIGNAL" SG_ 2147484474 LiftingControlModeRearAxle_ISig_ "x0000001D04149A4E";
BA_ "SeToolName_SIGNAL" SG_ 2147484474 LiftingControlModeRearAxle_ISig_ "LiftingControlModeRearAxle";
BA_ "SeToolVersion_SIGNAL" SG_ 2147484474 LiftingControlModeRearAxle_ISig_ "1";
BA_ "SystemSignalLongSymbol" SG_ 2147484474 LiftingControlModeRearAxle_ISig_ "LiftingControlModeRearAxle_ISig_4";
BA_ "GenSigCycleTime" SG_ 2147484474 KneelingStatusHMI_ISig_4 100;
BA_ "GenSigCycleTimeActive" SG_ 2147484474 KneelingStatusHMI_ISig_4 100;
BA_ "GenSigStartValue" SG_ 2147484474 KneelingStatusHMI_ISig_4 3;
BA_ "Platform_VMCU1_Sig" SG_ 2147484474 KneelingStatusHMI_ISig_4 1;
BA_ "GenSigCycleTime" SG_ 2147484474 SWEngineStop_rqst_ISig_4 100;
BA_ "GenSigCycleTimeActive" SG_ 2147484474 SWEngineStop_rqst_ISig_4 100;
BA_ "GenSigStartValue" SG_ 2147484474 SWEngineStop_rqst_ISig_4 7;
BA_ "Platform_VMCU1_Sig" SG_ 2147484474 SWEngineStop_rqst_ISig_4 1;
BA_ "GenSigCycleTime" SG_ 2147484474 FrontEndPositionStatus_ISig_4 100;
BA_ "GenSigCycleTimeActive" SG_ 2147484474 FrontEndPositionStatus_ISig_4 100;
BA_ "GenSigStartValue" SG_ 2147484474 FrontEndPositionStatus_ISig_4 7;
BA_ "GenSigMaxLatency" SG_ 2147484474 FrontEndPositionStatus_ISig_4 117;
BA_ "Platform_VMCU1_Sig" SG_ 2147484474 FrontEndPositionStatus_ISig_4 1;
BA_ "GenSigCycleTime" SG_ 2147484474 LiftingControlModeFrontAxle_ISig 100;
BA_ "GenSigCycleTimeActive" SG_ 2147484474 LiftingControlModeFrontAxle_ISig 100;
BA_ "GenSigStartValue" SG_ 2147484474 LiftingControlModeFrontAxle_ISig 3;
BA_ "Platform_VMCU1_Sig" SG_ 2147484474 LiftingControlModeFrontAxle_ISig 1;
BA_ "SeToolAncestorID_SIGNAL" SG_ 2147484474 LiftingControlModeFrontAxle_ISig "x0000001D04149903";
BA_ "SeToolItemID_SIGNAL" SG_ 2147484474 LiftingControlModeFrontAxle_ISig "x0000001D04149903";
BA_ "SeToolName_SIGNAL" SG_ 2147484474 LiftingControlModeFrontAxle_ISig "LiftingControlModeFrontAxle";
BA_ "SeToolVersion_SIGNAL" SG_ 2147484474 LiftingControlModeFrontAxle_ISig "1";
BA_ "SystemSignalLongSymbol" SG_ 2147484474 LiftingControlModeFrontAxle_ISig "LiftingControlModeFrontAxle_ISig_4";
BA_ "GenSigSendType" SG_ 2147484474 FrontAxleInBumperRange_UB_ISig_4 7;
BA_ "Platform_VMCU1_Sig" SG_ 2147484474 FrontAxleInBumperRange_UB_ISig_4 1;
BA_ "GenSigCycleTime" SG_ 2147484474 UnevenLoadWarning_ISig_4 100;
BA_ "GenSigCycleTimeActive" SG_ 2147484474 UnevenLoadWarning_ISig_4 100;
BA_ "GenSigStartValue" SG_ 2147484474 UnevenLoadWarning_ISig_4 3;
BA_ "GenSigMaxLatency" SG_ 2147484474 UnevenLoadWarning_ISig_4 117;
BA_ "Platform_VMCU1_Sig" SG_ 2147484474 UnevenLoadWarning_ISig_4 1;
BA_ "GenSigCycleTime" SG_ 2147484474 RampHeightOutsideTargetRange_ISi 100;
BA_ "GenSigCycleTimeActive" SG_ 2147484474 RampHeightOutsideTargetRange_ISi 100;
BA_ "GenSigStartValue" SG_ 2147484474 RampHeightOutsideTargetRange_ISi 7;
BA_ "GenSigMaxLatency" SG_ 2147484474 RampHeightOutsideTargetRange_ISi 117;
BA_ "Platform_VMCU1_Sig" SG_ 2147484474 RampHeightOutsideTargetRange_ISi 1;
BA_ "SystemSignalLongSymbol" SG_ 2147484474 RampHeightOutsideTargetRange_ISi "RampHeightOutsideTargetRange_ISig_4";
BA_ "GenSigCycleTime" SG_ 2147484474 DriveLevelPosUserInteraction_ISi 100;
BA_ "GenSigCycleTimeActive" SG_ 2147484474 DriveLevelPosUserInteraction_ISi 100;
BA_ "GenSigStartValue" SG_ 2147484474 DriveLevelPosUserInteraction_ISi 7;
BA_ "Platform_VMCU1_Sig" SG_ 2147484474 DriveLevelPosUserInteraction_ISi 1;
BA_ "SystemSignalLongSymbol" SG_ 2147484474 DriveLevelPosUserInteraction_ISi "DriveLevelPosUserInteraction_ISig_4";
BA_ "GenSigCycleTime" SG_ 2147484474 RearEndPositionStatus_ISig_4 100;
BA_ "GenSigCycleTimeActive" SG_ 2147484474 RearEndPositionStatus_ISig_4 100;
BA_ "GenSigStartValue" SG_ 2147484474 RearEndPositionStatus_ISig_4 7;
BA_ "GenSigMaxLatency" SG_ 2147484474 RearEndPositionStatus_ISig_4 117;
BA_ "Platform_VMCU1_Sig" SG_ 2147484474 RearEndPositionStatus_ISig_4 1;
BA_ "GenSigCycleTime" SG_ 2147484474 ProhibitControlStatus_ISig_4 100;
BA_ "GenSigCycleTimeActive" SG_ 2147484474 ProhibitControlStatus_ISig_4 100;
BA_ "GenSigStartValue" SG_ 2147484474 ProhibitControlStatus_ISig_4 3;
BA_ "GenSigMaxLatency" SG_ 2147484474 ProhibitControlStatus_ISig_4 117;
BA_ "Platform_VMCU1_Sig" SG_ 2147484474 ProhibitControlStatus_ISig_4 1;
BA_ "GenSigCycleTime" SG_ 2147484474 ChangeKneelACK_ISig_4 100;
BA_ "GenSigCycleTimeActive" SG_ 2147484474 ChangeKneelACK_ISig_4 100;
BA_ "GenSigStartValue" SG_ 2147484474 ChangeKneelACK_ISig_4 3;
BA_ "Platform_VMCU1_Sig" SG_ 2147484474 ChangeKneelACK_ISig_4 1;
BA_ "GenSigCycleTime" SG_ 2147484474 ParkBrakeApplicationMode2 100;
BA_ "GenSigCycleTimeActive" SG_ 2147484474 ParkBrakeApplicationMode2 100;
BA_ "GenSigStartValue" SG_ 2147484474 ParkBrakeApplicationMode2 15;
BA_ "GenSigCycleTime" SG_ 2147484474 RollEndPositionStatus_ISig_4 100;
BA_ "GenSigCycleTimeActive" SG_ 2147484474 RollEndPositionStatus_ISig_4 100;
BA_ "GenSigStartValue" SG_ 2147484474 RollEndPositionStatus_ISig_4 7;
BA_ "GenSigMaxLatency" SG_ 2147484474 RollEndPositionStatus_ISig_4 117;
BA_ "Platform_VMCU1_Sig" SG_ 2147484474 RollEndPositionStatus_ISig_4 1;
BA_ "GenSigSendType" SG_ 2147484474 RearAxleInBumperRange_UB_ISig_4 7;
BA_ "Platform_VMCU1_Sig" SG_ 2147484474 RearAxleInBumperRange_UB_ISig_4 1;
BA_ "GenSigCycleTime" SG_ 2147484474 ParkBrakeReleaseMode2_ISig_4 100;
BA_ "GenSigCycleTimeActive" SG_ 2147484474 ParkBrakeReleaseMode2_ISig_4 100;
BA_ "GenSigStartValue" SG_ 2147484474 ParkBrakeReleaseMode2_ISig_4 15;
BA_ "GenSigCycleTime" SG_ 2147484474 ECSStandbyAllowed_ISig_4 100;
BA_ "GenSigCycleTimeActive" SG_ 2147484474 ECSStandbyAllowed_ISig_4 100;
BA_ "GenSigStartValue" SG_ 2147484474 ECSStandbyAllowed_ISig_4 3;
BA_ "Platform_VMCU1_Sig" SG_ 2147484474 ECSStandbyAllowed_ISig_4 1;
BA_ "GenSigCycleTime" SG_ 2147484474 RearAxleInBumperRange_ISig_4 100;
BA_ "GenSigCycleTimeActive" SG_ 2147484474 RearAxleInBumperRange_ISig_4 100;
BA_ "GenSigStartValue" SG_ 2147484474 RearAxleInBumperRange_ISig_4 3;
BA_ "NeedsUpdateBit" SG_ 2147484474 RearAxleInBumperRange_ISig_4 1;
BA_ "Platform_VMCU1_Sig" SG_ 2147484474 RearAxleInBumperRange_ISig_4 1;
BA_ "SeToolAncestorID_SIGNAL" SG_ 2147484474 RearAxleInBumperRange_ISig_4 "x0000001D04149986";
BA_ "SeToolItemID_SIGNAL" SG_ 2147484474 RearAxleInBumperRange_ISig_4 "x0000001D04149986";
BA_ "SeToolName_SIGNAL" SG_ 2147484474 RearAxleInBumperRange_ISig_4 "RearAxleInBumperRange";
BA_ "SeToolVersion_SIGNAL" SG_ 2147484474 RearAxleInBumperRange_ISig_4 "1";
BA_ "GenSigCycleTime" SG_ 2147484677 RelativeLevelRearAxleRight_ISig_ 100;
BA_ "GenSigCycleTimeActive" SG_ 2147484677 RelativeLevelRearAxleRight_ISig_ 100;
BA_ "GenSigStartValue" SG_ 2147484677 RelativeLevelRearAxleRight_ISig_ 65535;
BA_ "Platform_VMCU1_Sig" SG_ 2147484677 RelativeLevelRearAxleRight_ISig_ 1;
BA_ "SeToolAncestorID_SIGNAL" SG_ 2147484677 RelativeLevelRearAxleRight_ISig_ "x0000001D0412EE40";
BA_ "SeToolItemID_SIGNAL" SG_ 2147484677 RelativeLevelRearAxleRight_ISig_ "x0000001D04384E50";
BA_ "SeToolName_SIGNAL" SG_ 2147484677 RelativeLevelRearAxleRight_ISig_ "RelativeLevelRearAxleRight";
BA_ "SeToolVersion_SIGNAL" SG_ 2147484677 RelativeLevelRearAxleRight_ISig_ "2";
BA_ "SystemSignalLongSymbol" SG_ 2147484677 RelativeLevelRearAxleRight_ISig_ "RelativeLevelRearAxleRight_ISig_4";
BA_ "GenSigCycleTime" SG_ 2147484677 RelativeLevelFrontAxleRight_ISig 100;
BA_ "GenSigCycleTimeActive" SG_ 2147484677 RelativeLevelFrontAxleRight_ISig 100;
BA_ "GenSigStartValue" SG_ 2147484677 RelativeLevelFrontAxleRight_ISig 65535;
BA_ "Platform_VMCU1_Sig" SG_ 2147484677 RelativeLevelFrontAxleRight_ISig 1;
BA_ "SeToolAncestorID_SIGNAL" SG_ 2147484677 RelativeLevelFrontAxleRight_ISig "x0000001D0412EE3C";
BA_ "SeToolItemID_SIGNAL" SG_ 2147484677 RelativeLevelFrontAxleRight_ISig "x0000001D04384E33";
BA_ "SeToolName_SIGNAL" SG_ 2147484677 RelativeLevelFrontAxleRight_ISig "RelativeLevelFrontAxleRight";
BA_ "SeToolVersion_SIGNAL" SG_ 2147484677 RelativeLevelFrontAxleRight_ISig "2";
BA_ "SystemSignalLongSymbol" SG_ 2147484677 RelativeLevelFrontAxleRight_ISig "RelativeLevelFrontAxleRight_ISig_4";
BA_ "GenSigCycleTime" SG_ 2147484677 RelativeLevelFrontAxleLeft_ISig_ 100;
BA_ "GenSigCycleTimeActive" SG_ 2147484677 RelativeLevelFrontAxleLeft_ISig_ 100;
BA_ "GenSigStartValue" SG_ 2147484677 RelativeLevelFrontAxleLeft_ISig_ 65535;
BA_ "Platform_VMCU1_Sig" SG_ 2147484677 RelativeLevelFrontAxleLeft_ISig_ 1;
BA_ "SeToolAncestorID_SIGNAL" SG_ 2147484677 RelativeLevelFrontAxleLeft_ISig_ "x0000001D0412EE39";
BA_ "SeToolItemID_SIGNAL" SG_ 2147484677 RelativeLevelFrontAxleLeft_ISig_ "x0000001D04384DFD";
BA_ "SeToolName_SIGNAL" SG_ 2147484677 RelativeLevelFrontAxleLeft_ISig_ "RelativeLevelFrontAxleLeft";
BA_ "SeToolVersion_SIGNAL" SG_ 2147484677 RelativeLevelFrontAxleLeft_ISig_ "2";
BA_ "SystemSignalLongSymbol" SG_ 2147484677 RelativeLevelFrontAxleLeft_ISig_ "RelativeLevelFrontAxleLeft_ISig_4";
BA_ "GenSigCycleTime" SG_ 2147484677 RelativeLevelRearAxleLeft_ISig_4 100;
BA_ "GenSigCycleTimeActive" SG_ 2147484677 RelativeLevelRearAxleLeft_ISig_4 100;
BA_ "GenSigStartValue" SG_ 2147484677 RelativeLevelRearAxleLeft_ISig_4 65535;
BA_ "Platform_VMCU1_Sig" SG_ 2147484677 RelativeLevelRearAxleLeft_ISig_4 1;
BA_ "SeToolAncestorID_SIGNAL" SG_ 2147484677 RelativeLevelRearAxleLeft_ISig_4 "x0000001D0412EE3E";
BA_ "SeToolItemID_SIGNAL" SG_ 2147484677 RelativeLevelRearAxleLeft_ISig_4 "x0000001D04384E3D";
BA_ "SeToolName_SIGNAL" SG_ 2147484677 RelativeLevelRearAxleLeft_ISig_4 "RelativeLevelRearAxleLeft";
BA_ "SeToolVersion_SIGNAL" SG_ 2147484677 RelativeLevelRearAxleLeft_ISig_4 "2";
BA_ "GenSigSendType" SG_ 2147485245 VMCU_BB2_140P_FCS 7;
BA_ "GenSigCycleTime" SG_ 2147485244 SavedUnit20_TrailerName 100;
BA_ "GenSigCycleTimeActive" SG_ 2147485244 SavedUnit20_TrailerName 100;
BA_ "GenSigMaxLatency" SG_ 2147485244 SavedUnit20_TrailerName 10000;
BA_ "GenSigCycleTime" SG_ 2147485244 SavedUnit20_TrailerPosition 100;
BA_ "GenSigCycleTimeActive" SG_ 2147485244 SavedUnit20_TrailerPosition 100;
BA_ "GenSigStartValue" SG_ 2147485244 SavedUnit20_TrailerPosition 7;
BA_ "GenSigMaxLatency" SG_ 2147485244 SavedUnit20_TrailerPosition 10000;
BA_ "GenSigSendType" SG_ 2147485243 VMCU_BB2_139P_FCS 7;
BA_ "GenSigCycleTime" SG_ 2147485242 SavedUnit19_TrailerName 100;
BA_ "GenSigCycleTimeActive" SG_ 2147485242 SavedUnit19_TrailerName 100;
BA_ "GenSigMaxLatency" SG_ 2147485242 SavedUnit19_TrailerName 10000;
BA_ "GenSigCycleTime" SG_ 2147485242 SavedUnit19_TrailerPosition 100;
BA_ "GenSigCycleTimeActive" SG_ 2147485242 SavedUnit19_TrailerPosition 100;
BA_ "GenSigStartValue" SG_ 2147485242 SavedUnit19_TrailerPosition 7;
BA_ "GenSigMaxLatency" SG_ 2147485242 SavedUnit19_TrailerPosition 10000;
BA_ "GenSigSendType" SG_ 2147485241 VMCU_BB2_138P_FCS 7;
BA_ "GenSigCycleTime" SG_ 2147485240 SavedUnit18_TrailerPosition 100;
BA_ "GenSigCycleTimeActive" SG_ 2147485240 SavedUnit18_TrailerPosition 100;
BA_ "GenSigStartValue" SG_ 2147485240 SavedUnit18_TrailerPosition 7;
BA_ "GenSigMaxLatency" SG_ 2147485240 SavedUnit18_TrailerPosition 10000;
BA_ "GenSigCycleTime" SG_ 2147485240 SavedUnit18_TrailerName 100;
BA_ "GenSigCycleTimeActive" SG_ 2147485240 SavedUnit18_TrailerName 100;
BA_ "GenSigMaxLatency" SG_ 2147485240 SavedUnit18_TrailerName 10000;
BA_ "GenSigSendType" SG_ 2147485239 VMCU_BB2_137P_FCS 7;
BA_ "GenSigCycleTime" SG_ 2147485238 SavedUnit17_TrailerPosition 100;
BA_ "GenSigCycleTimeActive" SG_ 2147485238 SavedUnit17_TrailerPosition 100;
BA_ "GenSigStartValue" SG_ 2147485238 SavedUnit17_TrailerPosition 7;
BA_ "GenSigMaxLatency" SG_ 2147485238 SavedUnit17_TrailerPosition 10000;
BA_ "GenSigCycleTime" SG_ 2147485238 SavedUnit17_TrailerName 100;
BA_ "GenSigCycleTimeActive" SG_ 2147485238 SavedUnit17_TrailerName 100;
BA_ "GenSigMaxLatency" SG_ 2147485238 SavedUnit17_TrailerName 10000;
BA_ "GenSigSendType" SG_ 2147485237 VMCU_BB2_136P_FCS 7;
BA_ "GenSigCycleTime" SG_ 2147485236 SavedUnit16_TrailerName 100;
BA_ "GenSigCycleTimeActive" SG_ 2147485236 SavedUnit16_TrailerName 100;
BA_ "GenSigMaxLatency" SG_ 2147485236 SavedUnit16_TrailerName 10000;
BA_ "GenSigCycleTime" SG_ 2147485236 SavedUnit16_TrailerPosition 100;
BA_ "GenSigCycleTimeActive" SG_ 2147485236 SavedUnit16_TrailerPosition 100;
BA_ "GenSigStartValue" SG_ 2147485236 SavedUnit16_TrailerPosition 7;
BA_ "GenSigMaxLatency" SG_ 2147485236 SavedUnit16_TrailerPosition 10000;
BA_ "GenSigSendType" SG_ 2147485235 VMCU_BB2_135P_FCS 7;
BA_ "GenSigCycleTime" SG_ 2147485234 SavedUnit15_TrailerName 100;
BA_ "GenSigCycleTimeActive" SG_ 2147485234 SavedUnit15_TrailerName 100;
BA_ "GenSigMaxLatency" SG_ 2147485234 SavedUnit15_TrailerName 10000;
BA_ "GenSigCycleTime" SG_ 2147485234 SavedUnit15_TrailerPosition 100;
BA_ "GenSigCycleTimeActive" SG_ 2147485234 SavedUnit15_TrailerPosition 100;
BA_ "GenSigStartValue" SG_ 2147485234 SavedUnit15_TrailerPosition 7;
BA_ "GenSigMaxLatency" SG_ 2147485234 SavedUnit15_TrailerPosition 10000;
BA_ "GenSigSendType" SG_ 2147485233 VMCU_BB2_134P_FCS 7;
BA_ "GenSigCycleTime" SG_ 2147485232 SavedUnit14_TrailerPosition 100;
BA_ "GenSigCycleTimeActive" SG_ 2147485232 SavedUnit14_TrailerPosition 100;
BA_ "GenSigStartValue" SG_ 2147485232 SavedUnit14_TrailerPosition 7;
BA_ "GenSigMaxLatency" SG_ 2147485232 SavedUnit14_TrailerPosition 10000;
BA_ "GenSigCycleTime" SG_ 2147485232 SavedUnit14_TrailerName 100;
BA_ "GenSigCycleTimeActive" SG_ 2147485232 SavedUnit14_TrailerName 100;
BA_ "GenSigMaxLatency" SG_ 2147485232 SavedUnit14_TrailerName 10000;
BA_ "GenSigSendType" SG_ 2147485225 VMCU_BB2_133P_FCS 7;
BA_ "GenSigCycleTime" SG_ 2147485224 SavedUnit13_TrailerPosition 100;
BA_ "GenSigCycleTimeActive" SG_ 2147485224 SavedUnit13_TrailerPosition 100;
BA_ "GenSigStartValue" SG_ 2147485224 SavedUnit13_TrailerPosition 7;
BA_ "GenSigMaxLatency" SG_ 2147485224 SavedUnit13_TrailerPosition 10000;
BA_ "GenSigCycleTime" SG_ 2147485224 SavedUnit13_TrailerName 100;
BA_ "GenSigCycleTimeActive" SG_ 2147485224 SavedUnit13_TrailerName 100;
BA_ "GenSigMaxLatency" SG_ 2147485224 SavedUnit13_TrailerName 10000;
BA_ "GenSigSendType" SG_ 2147485223 VMCU_BB2_132P_FCS 7;
BA_ "GenSigCycleTime" SG_ 2147485222 SavedUnit12_TrailerName 100;
BA_ "GenSigCycleTimeActive" SG_ 2147485222 SavedUnit12_TrailerName 100;
BA_ "GenSigMaxLatency" SG_ 2147485222 SavedUnit12_TrailerName 10000;
BA_ "GenSigCycleTime" SG_ 2147485222 SavedUnit12_TrailerPosition 100;
BA_ "GenSigCycleTimeActive" SG_ 2147485222 SavedUnit12_TrailerPosition 100;
BA_ "GenSigStartValue" SG_ 2147485222 SavedUnit12_TrailerPosition 7;
BA_ "GenSigMaxLatency" SG_ 2147485222 SavedUnit12_TrailerPosition 10000;
BA_ "GenSigSendType" SG_ 2147485221 VMCU_BB2_131P_FCS 7;
BA_ "GenSigCycleTime" SG_ 2147485220 SavedUnit11_TrailerPosition 100;
BA_ "GenSigCycleTimeActive" SG_ 2147485220 SavedUnit11_TrailerPosition 100;
BA_ "GenSigStartValue" SG_ 2147485220 SavedUnit11_TrailerPosition 7;
BA_ "GenSigMaxLatency" SG_ 2147485220 SavedUnit11_TrailerPosition 10000;
BA_ "GenSigCycleTime" SG_ 2147485220 SavedUnit11_TrailerName 100;
BA_ "GenSigCycleTimeActive" SG_ 2147485220 SavedUnit11_TrailerName 100;
BA_ "GenSigMaxLatency" SG_ 2147485220 SavedUnit11_TrailerName 10000;
BA_ "GenSigSendType" SG_ 2147485219 VMCU_BB2_130P_FCS 7;
BA_ "GenSigCycleTime" SG_ 2147485218 SavedUnit10_TrailerName 100;
BA_ "GenSigCycleTimeActive" SG_ 2147485218 SavedUnit10_TrailerName 100;
BA_ "GenSigMaxLatency" SG_ 2147485218 SavedUnit10_TrailerName 10000;
BA_ "GenSigCycleTime" SG_ 2147485218 SavedUnit10_TrailerPosition 100;
BA_ "GenSigCycleTimeActive" SG_ 2147485218 SavedUnit10_TrailerPosition 100;
BA_ "GenSigStartValue" SG_ 2147485218 SavedUnit10_TrailerPosition 7;
BA_ "GenSigMaxLatency" SG_ 2147485218 SavedUnit10_TrailerPosition 10000;
BA_ "GenSigSendType" SG_ 2147485217 VMCU_BB2_129P_FCS 7;
BA_ "GenSigCycleTime" SG_ 2147485216 SavedUnit9_TrailerName 100;
BA_ "GenSigCycleTimeActive" SG_ 2147485216 SavedUnit9_TrailerName 100;
BA_ "GenSigMaxLatency" SG_ 2147485216 SavedUnit9_TrailerName 10000;
BA_ "GenSigCycleTime" SG_ 2147485216 SavedUnit9_TrailerPosition 100;
BA_ "GenSigCycleTimeActive" SG_ 2147485216 SavedUnit9_TrailerPosition 100;
BA_ "GenSigStartValue" SG_ 2147485216 SavedUnit9_TrailerPosition 7;
BA_ "GenSigMaxLatency" SG_ 2147485216 SavedUnit9_TrailerPosition 10000;
BA_ "GenSigSendType" SG_ 2147485215 VMCU_BB2_128P_FCS 7;
BA_ "GenSigCycleTime" SG_ 2147485214 SavedUnit8_TrailerName 100;
BA_ "GenSigCycleTimeActive" SG_ 2147485214 SavedUnit8_TrailerName 100;
BA_ "GenSigMaxLatency" SG_ 2147485214 SavedUnit8_TrailerName 10000;
BA_ "GenSigCycleTime" SG_ 2147485214 SavedUnit8_TrailerPosition 100;
BA_ "GenSigCycleTimeActive" SG_ 2147485214 SavedUnit8_TrailerPosition 100;
BA_ "GenSigStartValue" SG_ 2147485214 SavedUnit8_TrailerPosition 7;
BA_ "GenSigMaxLatency" SG_ 2147485214 SavedUnit8_TrailerPosition 10000;
BA_ "GenSigSendType" SG_ 2147485213 VMCU_BB2_127P_FCS 7;
BA_ "GenSigCycleTime" SG_ 2147485212 SavedUnit7_TrailerPosition 100;
BA_ "GenSigCycleTimeActive" SG_ 2147485212 SavedUnit7_TrailerPosition 100;
BA_ "GenSigStartValue" SG_ 2147485212 SavedUnit7_TrailerPosition 7;
BA_ "GenSigMaxLatency" SG_ 2147485212 SavedUnit7_TrailerPosition 10000;
BA_ "GenSigCycleTime" SG_ 2147485212 SavedUnit7_TrailerName 100;
BA_ "GenSigCycleTimeActive" SG_ 2147485212 SavedUnit7_TrailerName 100;
BA_ "GenSigMaxLatency" SG_ 2147485212 SavedUnit7_TrailerName 10000;
BA_ "GenSigSendType" SG_ 2147485211 VMCU_BB2_126P_FCS 7;
BA_ "GenSigCycleTime" SG_ 2147485210 SavedUnit6_TrailerPosition 100;
BA_ "GenSigCycleTimeActive" SG_ 2147485210 SavedUnit6_TrailerPosition 100;
BA_ "GenSigStartValue" SG_ 2147485210 SavedUnit6_TrailerPosition 7;
BA_ "GenSigMaxLatency" SG_ 2147485210 SavedUnit6_TrailerPosition 10000;
BA_ "GenSigCycleTime" SG_ 2147485210 SavedUnit6_TrailerName 100;
BA_ "GenSigCycleTimeActive" SG_ 2147485210 SavedUnit6_TrailerName 100;
BA_ "GenSigMaxLatency" SG_ 2147485210 SavedUnit6_TrailerName 10000;
BA_ "GenSigSendType" SG_ 2147485209 VMCU_BB2_125P_FCS 7;
BA_ "GenSigCycleTime" SG_ 2147485208 SavedUnit5_TrailerName 100;
BA_ "GenSigCycleTimeActive" SG_ 2147485208 SavedUnit5_TrailerName 100;
BA_ "GenSigMaxLatency" SG_ 2147485208 SavedUnit5_TrailerName 10000;
BA_ "GenSigCycleTime" SG_ 2147485208 SavedUnit5_TrailerPosition 100;
BA_ "GenSigCycleTimeActive" SG_ 2147485208 SavedUnit5_TrailerPosition 100;
BA_ "GenSigStartValue" SG_ 2147485208 SavedUnit5_TrailerPosition 7;
BA_ "GenSigMaxLatency" SG_ 2147485208 SavedUnit5_TrailerPosition 10000;
BA_ "GenSigSendType" SG_ 2147485207 VMCU_BB2_124P_FCS 7;
BA_ "GenSigCycleTime" SG_ 2147485206 SavedUnit4_TrailerPosition 100;
BA_ "GenSigCycleTimeActive" SG_ 2147485206 SavedUnit4_TrailerPosition 100;
BA_ "GenSigStartValue" SG_ 2147485206 SavedUnit4_TrailerPosition 7;
BA_ "GenSigMaxLatency" SG_ 2147485206 SavedUnit4_TrailerPosition 10000;
BA_ "GenSigCycleTime" SG_ 2147485206 SavedUnit4_TrailerName 100;
BA_ "GenSigCycleTimeActive" SG_ 2147485206 SavedUnit4_TrailerName 100;
BA_ "GenSigMaxLatency" SG_ 2147485206 SavedUnit4_TrailerName 10000;
BA_ "GenSigSendType" SG_ 2147485205 VMCU_BB2_123P_FCS 7;
BA_ "GenSigCycleTime" SG_ 2147485204 SavedUnit3_TrailerPosition 100;
BA_ "GenSigCycleTimeActive" SG_ 2147485204 SavedUnit3_TrailerPosition 100;
BA_ "GenSigStartValue" SG_ 2147485204 SavedUnit3_TrailerPosition 7;
BA_ "GenSigMaxLatency" SG_ 2147485204 SavedUnit3_TrailerPosition 10000;
BA_ "GenSigCycleTime" SG_ 2147485204 SavedUnit3_TrailerName 100;
BA_ "GenSigCycleTimeActive" SG_ 2147485204 SavedUnit3_TrailerName 100;
BA_ "GenSigMaxLatency" SG_ 2147485204 SavedUnit3_TrailerName 10000;
BA_ "GenSigSendType" SG_ 2147485203 VMCU_BB2_122P_FCS 7;
BA_ "GenSigCycleTime" SG_ 2147485202 SavedUnit2_TrailerName 100;
BA_ "GenSigCycleTimeActive" SG_ 2147485202 SavedUnit2_TrailerName 100;
BA_ "GenSigMaxLatency" SG_ 2147485202 SavedUnit2_TrailerName 10000;
BA_ "GenSigCycleTime" SG_ 2147485202 SavedUnit2_TrailerPosition 100;
BA_ "GenSigCycleTimeActive" SG_ 2147485202 SavedUnit2_TrailerPosition 100;
BA_ "GenSigStartValue" SG_ 2147485202 SavedUnit2_TrailerPosition 7;
BA_ "GenSigMaxLatency" SG_ 2147485202 SavedUnit2_TrailerPosition 10000;
BA_ "GenSigSendType" SG_ 2147485201 VMCU_BB2_121P_FCS 7;
BA_ "GenSigCycleTime" SG_ 2147485200 SavedUnit1_TrailerPosition 100;
BA_ "GenSigCycleTimeActive" SG_ 2147485200 SavedUnit1_TrailerPosition 100;
BA_ "GenSigStartValue" SG_ 2147485200 SavedUnit1_TrailerPosition 7;
BA_ "GenSigMaxLatency" SG_ 2147485200 SavedUnit1_TrailerPosition 10000;
BA_ "GenSigCycleTime" SG_ 2147485200 SavedUnit1_TrailerName 100;
BA_ "GenSigCycleTimeActive" SG_ 2147485200 SavedUnit1_TrailerName 100;
BA_ "GenSigMaxLatency" SG_ 2147485200 SavedUnit1_TrailerName 10000;
BA_ "GenSigSendType" SG_ 2147485090 VMCU_BB2_120S_FCS 7;
BA_ "GenSigSendType" SG_ 2147485089 RenameTrailerAutoRqst_TrailerVIN 1;
BA_ "GenSigMaxLatency" SG_ 2147485089 RenameTrailerAutoRqst_TrailerVIN 1000;
BA_ "NeedsUpdateBit" SG_ 2147485089 RenameTrailerAutoRqst_TrailerVIN 1;
BA_ "GenSigSendType" SG_ 2147485089 RenameTrailerAutoRqst_Request 1;
BA_ "GenSigStartValue" SG_ 2147485089 RenameTrailerAutoRqst_Request 3;
BA_ "GenSigMaxLatency" SG_ 2147485089 RenameTrailerAutoRqst_Request 1000;
BA_ "NeedsUpdateBit" SG_ 2147485089 RenameTrailerAutoRqst_Request 1;
BA_ "GenSigSendType" SG_ 2147485089 RenameTrailerAutoRqst_sg_UB 7;
BA_ "GenSigSendType" SG_ 2147485089 RenameTrailerAutoRqst_Position 1;
BA_ "GenSigStartValue" SG_ 2147485089 RenameTrailerAutoRqst_Position 7;
BA_ "GenSigMaxLatency" SG_ 2147485089 RenameTrailerAutoRqst_Position 1000;
BA_ "NeedsUpdateBit" SG_ 2147485089 RenameTrailerAutoRqst_Position 1;
BA_ "GenSigCycleTime" SG_ 2147484941 RSLAssistStatus 100;
BA_ "GenSigCycleTimeActive" SG_ 2147484941 RSLAssistStatus 100;
BA_ "GenSigStartValue" SG_ 2147484941 RSLAssistStatus 7;
BA_ "GenSigCycleTime" SG_ 2147484919 DayOfWeek_stat_ISig_4 100;
BA_ "GenSigCycleTimeActive" SG_ 2147484919 DayOfWeek_stat_ISig_4 100;
BA_ "GenSigStartValue" SG_ 2147484919 DayOfWeek_stat_ISig_4 15;
BA_ "GenSigMaxLatency" SG_ 2147484919 DayOfWeek_stat_ISig_4 71;
BA_ "Platform_VMCU1_Sig" SG_ 2147484919 DayOfWeek_stat_ISig_4 1;
BA_ "GenSigCycleTime" SG_ 2147484919 MinutesLocal_ISig_4 100;
BA_ "GenSigCycleTimeActive" SG_ 2147484919 MinutesLocal_ISig_4 100;
BA_ "GenSigStartValue" SG_ 2147484919 MinutesLocal_ISig_4 255;
BA_ "GenSigMaxLatency" SG_ 2147484919 MinutesLocal_ISig_4 121;
BA_ "Platform_VMCU1_Sig" SG_ 2147484919 MinutesLocal_ISig_4 1;
BA_ "GenSigCycleTime" SG_ 2147484919 DayLocal_ISig_4 100;
BA_ "GenSigCycleTimeActive" SG_ 2147484919 DayLocal_ISig_4 100;
BA_ "GenSigStartValue" SG_ 2147484919 DayLocal_ISig_4 255;
BA_ "GenSigMaxLatency" SG_ 2147484919 DayLocal_ISig_4 121;
BA_ "Platform_VMCU1_Sig" SG_ 2147484919 DayLocal_ISig_4 1;
BA_ "GenSigCycleTime" SG_ 2147484919 MonthLocal_ISig_4 100;
BA_ "GenSigCycleTimeActive" SG_ 2147484919 MonthLocal_ISig_4 100;
BA_ "GenSigStartValue" SG_ 2147484919 MonthLocal_ISig_4 255;
BA_ "GenSigMaxLatency" SG_ 2147484919 MonthLocal_ISig_4 121;
BA_ "Platform_VMCU1_Sig" SG_ 2147484919 MonthLocal_ISig_4 1;
BA_ "GenSigCycleTime" SG_ 2147484919 SecondsLocal_ISig_4 100;
BA_ "GenSigCycleTimeActive" SG_ 2147484919 SecondsLocal_ISig_4 100;
BA_ "GenSigStartValue" SG_ 2147484919 SecondsLocal_ISig_4 255;
BA_ "GenSigMaxLatency" SG_ 2147484919 SecondsLocal_ISig_4 121;
BA_ "Platform_VMCU1_Sig" SG_ 2147484919 SecondsLocal_ISig_4 1;
BA_ "GenSigCycleTime" SG_ 2147484919 SelectedDaylightSaving_stat 100;
BA_ "GenSigCycleTimeActive" SG_ 2147484919 SelectedDaylightSaving_stat 100;
BA_ "GenSigStartValue" SG_ 2147484919 SelectedDaylightSaving_stat 3;
BA_ "GenSigCycleTime" SG_ 2147484919 YearLocal_ISig_4 100;
BA_ "GenSigCycleTimeActive" SG_ 2147484919 YearLocal_ISig_4 100;
BA_ "GenSigStartValue" SG_ 2147484919 YearLocal_ISig_4 255;
BA_ "GenSigMaxLatency" SG_ 2147484919 YearLocal_ISig_4 121;
BA_ "Platform_VMCU1_Sig" SG_ 2147484919 YearLocal_ISig_4 1;
BA_ "GenSigCycleTime" SG_ 2147484919 HoursLocal_ISig_4 100;
BA_ "GenSigCycleTimeActive" SG_ 2147484919 HoursLocal_ISig_4 100;
BA_ "GenSigStartValue" SG_ 2147484919 HoursLocal_ISig_4 255;
BA_ "GenSigMaxLatency" SG_ 2147484919 HoursLocal_ISig_4 121;
BA_ "Platform_VMCU1_Sig" SG_ 2147484919 HoursLocal_ISig_4 1;
BA_ "GenSigCycleTime" SG_ 2147484039 RequestedUpshiftDownshiftSteps 100;
BA_ "GenSigCycleTimeActive" SG_ 2147484039 RequestedUpshiftDownshiftSteps 100;
BA_ "GenSigStartValue" SG_ 2147484039 RequestedUpshiftDownshiftSteps 7;
BA_ "GenSigMaxLatency" SG_ 2147484039 RequestedUpshiftDownshiftSteps 26;
BA_ "Platform_VMCU1_Sig" SG_ 2147484039 RequestedUpshiftDownshiftSteps 1;
BA_ "SeToolAncestorID_SIGNAL" SG_ 2147484039 RequestedUpshiftDownshiftSteps "x0000001D041B21AC";
BA_ "SeToolItemID_SIGNAL" SG_ 2147484039 RequestedUpshiftDownshiftSteps "x0000001D041B21AC";
BA_ "SeToolName_SIGNAL" SG_ 2147484039 RequestedUpshiftDownshiftSteps "RequestedUpshiftDownshiftSteps";
BA_ "SeToolVersion_SIGNAL" SG_ 2147484039 RequestedUpshiftDownshiftSteps "1";
BA_ "GenSigCycleTime" SG_ 2147484039 GearLeverPosition_ISig_4 100;
BA_ "GenSigCycleTimeActive" SG_ 2147484039 GearLeverPosition_ISig_4 100;
BA_ "GenSigStartValue" SG_ 2147484039 GearLeverPosition_ISig_4 15;
BA_ "GenSigMaxLatency" SG_ 2147484039 GearLeverPosition_ISig_4 26;
BA_ "NeedsUpdateBit" SG_ 2147484039 GearLeverPosition_ISig_4 1;
BA_ "Platform_VMCU1_Sig" SG_ 2147484039 GearLeverPosition_ISig_4 1;
BA_ "SeToolAncestorID_SIGNAL" SG_ 2147484039 GearLeverPosition_ISig_4 "x0000001D0412B683";
BA_ "SeToolItemID_SIGNAL" SG_ 2147484039 GearLeverPosition_ISig_4 "x0000001D0412B683";
BA_ "SeToolName_SIGNAL" SG_ 2147484039 GearLeverPosition_ISig_4 "GearLeverPosition";
BA_ "SeToolVersion_SIGNAL" SG_ 2147484039 GearLeverPosition_ISig_4 "1";
BA_ "GenSigCycleTime" SG_ 2147484039 DownShiftRequest 100;
BA_ "GenSigCycleTimeActive" SG_ 2147484039 DownShiftRequest 100;
BA_ "GenSigStartValue" SG_ 2147484039 DownShiftRequest 3;
BA_ "GenSigMaxLatency" SG_ 2147484039 DownShiftRequest 26;
BA_ "Platform_VMCU1_Sig" SG_ 2147484039 DownShiftRequest 1;
BA_ "SeToolAncestorID_SIGNAL" SG_ 2147484039 DownShiftRequest "x0000001D0416F343";
BA_ "SeToolItemID_SIGNAL" SG_ 2147484039 DownShiftRequest "x0000001D0428EB01";
BA_ "SeToolName_SIGNAL" SG_ 2147484039 DownShiftRequest "DownShiftRequest";
BA_ "SeToolVersion_SIGNAL" SG_ 2147484039 DownShiftRequest "2";
BA_ "GenSigCycleTime" SG_ 2147484039 UpShiftRequest 100;
BA_ "GenSigCycleTimeActive" SG_ 2147484039 UpShiftRequest 100;
BA_ "GenSigStartValue" SG_ 2147484039 UpShiftRequest 3;
BA_ "GenSigMaxLatency" SG_ 2147484039 UpShiftRequest 26;
BA_ "Platform_VMCU1_Sig" SG_ 2147484039 UpShiftRequest 1;
BA_ "SeToolAncestorID_SIGNAL" SG_ 2147484039 UpShiftRequest "x0000001D0416F32D";
BA_ "SeToolItemID_SIGNAL" SG_ 2147484039 UpShiftRequest "x0000001D0416F32D";
BA_ "SeToolName_SIGNAL" SG_ 2147484039 UpShiftRequest "UpShiftRequest";
BA_ "SeToolVersion_SIGNAL" SG_ 2147484039 UpShiftRequest "1";
BA_ "GenSigSendType" SG_ 2147484039 GearLeverPosition_UB_ISig_4 7;
BA_ "Platform_VMCU1_Sig" SG_ 2147484039 GearLeverPosition_UB_ISig_4 1;
BA_ "GenSigCycleTime" SG_ 2147484039 LimpHomeSwitch_stat 100;
BA_ "GenSigCycleTimeActive" SG_ 2147484039 LimpHomeSwitch_stat 100;
BA_ "GenSigStartValue" SG_ 2147484039 LimpHomeSwitch_stat 3;
BA_ "GenSigMaxLatency" SG_ 2147484039 LimpHomeSwitch_stat 26;
BA_ "Platform_VMCU1_Sig" SG_ 2147484039 LimpHomeSwitch_stat 1;
BA_ "SeToolAncestorID_SIGNAL" SG_ 2147484039 LimpHomeSwitch_stat "x0000001D0423C430";
BA_ "SeToolItemID_SIGNAL" SG_ 2147484039 LimpHomeSwitch_stat "x0000001D0423C430";
BA_ "SeToolName_SIGNAL" SG_ 2147484039 LimpHomeSwitch_stat "LimpHomeSwitch_stat";
BA_ "SeToolVersion_SIGNAL" SG_ 2147484039 LimpHomeSwitch_stat "1";
BA_ "GenSigCycleTime" SG_ 2147484039 RequestForHighestGearRatio 100;
BA_ "GenSigCycleTimeActive" SG_ 2147484039 RequestForHighestGearRatio 100;
BA_ "GenSigStartValue" SG_ 2147484039 RequestForHighestGearRatio 3;
BA_ "GenSigMaxLatency" SG_ 2147484039 RequestForHighestGearRatio 26;
BA_ "Platform_VMCU1_Sig" SG_ 2147484039 RequestForHighestGearRatio 1;
BA_ "SeToolAncestorID_SIGNAL" SG_ 2147484039 RequestForHighestGearRatio "x0000001D0416F366";
BA_ "SeToolItemID_SIGNAL" SG_ 2147484039 RequestForHighestGearRatio "x0000001D0416F366";
BA_ "SeToolName_SIGNAL" SG_ 2147484039 RequestForHighestGearRatio "RequestForHighestGearRatio";
BA_ "SeToolVersion_SIGNAL" SG_ 2147484039 RequestForHighestGearRatio "1";
BA_ "GenSigCycleTime" SG_ 2147484039 EconomyPowerSwitch_stat 100;
BA_ "GenSigCycleTimeActive" SG_ 2147484039 EconomyPowerSwitch_stat 100;
BA_ "GenSigStartValue" SG_ 2147484039 EconomyPowerSwitch_stat 3;
BA_ "GenSigMaxLatency" SG_ 2147484039 EconomyPowerSwitch_stat 26;
BA_ "Platform_VMCU1_Sig" SG_ 2147484039 EconomyPowerSwitch_stat 1;
BA_ "SeToolAncestorID_SIGNAL" SG_ 2147484039 EconomyPowerSwitch_stat "x0000001D0423C42E";
BA_ "SeToolItemID_SIGNAL" SG_ 2147484039 EconomyPowerSwitch_stat "x0000001D0423C42E";
BA_ "SeToolName_SIGNAL" SG_ 2147484039 EconomyPowerSwitch_stat "EconomyPowerSwitch_stat";
BA_ "SeToolVersion_SIGNAL" SG_ 2147484039 EconomyPowerSwitch_stat "1";
BA_ "GenSigCycleTime" SG_ 2147484975 FuelLostInWrongGear 100;
BA_ "GenSigCycleTimeActive" SG_ 2147484975 FuelLostInWrongGear 100;
BA_ "GenSigStartValue" SG_ 2147484975 FuelLostInWrongGear 4294967295;
BA_ "GenSigMaxLatency" SG_ 2147484975 FuelLostInWrongGear 996;
BA_ "GenSigCycleTime" SG_ 2147484975 FuelSavedInCoasting 100;
BA_ "GenSigCycleTimeActive" SG_ 2147484975 FuelSavedInCoasting 100;
BA_ "GenSigStartValue" SG_ 2147484975 FuelSavedInCoasting 4294967295;
BA_ "GenSigMaxLatency" SG_ 2147484975 FuelSavedInCoasting 996;
BA_ "GenSigSendType" SG_ 2147484974 VMCU_BB2_116S_FCS 7;
BA_ "GenSigSendType" SG_ 2147484969 CalDataLoadP5_ScaleLoad 1;
BA_ "GenSigCycleTime" SG_ 2147484969 CalDataLoadP5_ScaleLoad 100;
BA_ "GenSigCycleTimeActive" SG_ 2147484969 CalDataLoadP5_ScaleLoad 100;
BA_ "GenSigStartValue" SG_ 2147484969 CalDataLoadP5_ScaleLoad 65535;
BA_ "GenSigMaxLatency" SG_ 2147484969 CalDataLoadP5_ScaleLoad 1000;
BA_ "NeedsUpdateBit" SG_ 2147484969 CalDataLoadP5_ScaleLoad 1;
BA_ "GenSigSendType" SG_ 2147484969 CalDataLoadP5_UncalLoad 1;
BA_ "GenSigCycleTime" SG_ 2147484969 CalDataLoadP5_UncalLoad 100;
BA_ "GenSigCycleTimeActive" SG_ 2147484969 CalDataLoadP5_UncalLoad 100;
BA_ "GenSigStartValue" SG_ 2147484969 CalDataLoadP5_UncalLoad 65535;
BA_ "GenSigMaxLatency" SG_ 2147484969 CalDataLoadP5_UncalLoad 1000;
BA_ "NeedsUpdateBit" SG_ 2147484969 CalDataLoadP5_UncalLoad 1;
BA_ "GenSigSendType" SG_ 2147484969 CalDataLoadP5_sg_UB 7;
BA_ "GenSigSendType" SG_ 2147484969 CalDataLoadP5_YearUTC 1;
BA_ "GenSigCycleTime" SG_ 2147484969 CalDataLoadP5_YearUTC 100;
BA_ "GenSigCycleTimeActive" SG_ 2147484969 CalDataLoadP5_YearUTC 100;
BA_ "GenSigStartValue" SG_ 2147484969 CalDataLoadP5_YearUTC 255;
BA_ "GenSigMaxLatency" SG_ 2147484969 CalDataLoadP5_YearUTC 1000;
BA_ "NeedsUpdateBit" SG_ 2147484969 CalDataLoadP5_YearUTC 1;
BA_ "GenSigSendType" SG_ 2147484969 CalDataLoadP5_VehicleID 1;
BA_ "GenSigCycleTime" SG_ 2147484969 CalDataLoadP5_VehicleID 100;
BA_ "GenSigCycleTimeActive" SG_ 2147484969 CalDataLoadP5_VehicleID 100;
BA_ "GenSigStartValue" SG_ 2147484969 CalDataLoadP5_VehicleID 7;
BA_ "GenSigMaxLatency" SG_ 2147484969 CalDataLoadP5_VehicleID 1000;
BA_ "NeedsUpdateBit" SG_ 2147484969 CalDataLoadP5_VehicleID 1;
BA_ "GenSigSendType" SG_ 2147484969 CalDataLoadP5_AxleID 1;
BA_ "GenSigCycleTime" SG_ 2147484969 CalDataLoadP5_AxleID 100;
BA_ "GenSigCycleTimeActive" SG_ 2147484969 CalDataLoadP5_AxleID 100;
BA_ "GenSigStartValue" SG_ 2147484969 CalDataLoadP5_AxleID 15;
BA_ "GenSigMaxLatency" SG_ 2147484969 CalDataLoadP5_AxleID 1000;
BA_ "NeedsUpdateBit" SG_ 2147484969 CalDataLoadP5_AxleID 1;
BA_ "GenSigSendType" SG_ 2147484969 CalDataLoadP5_DayUTC 1;
BA_ "GenSigCycleTime" SG_ 2147484969 CalDataLoadP5_DayUTC 100;
BA_ "GenSigCycleTimeActive" SG_ 2147484969 CalDataLoadP5_DayUTC 100;
BA_ "GenSigStartValue" SG_ 2147484969 CalDataLoadP5_DayUTC 255;
BA_ "GenSigMaxLatency" SG_ 2147484969 CalDataLoadP5_DayUTC 1000;
BA_ "NeedsUpdateBit" SG_ 2147484969 CalDataLoadP5_DayUTC 1;
BA_ "GenSigSendType" SG_ 2147484969 CalDataLoadP5_HoursUTC 1;
BA_ "GenSigCycleTime" SG_ 2147484969 CalDataLoadP5_HoursUTC 100;
BA_ "GenSigCycleTimeActive" SG_ 2147484969 CalDataLoadP5_HoursUTC 100;
BA_ "GenSigStartValue" SG_ 2147484969 CalDataLoadP5_HoursUTC 255;
BA_ "GenSigMaxLatency" SG_ 2147484969 CalDataLoadP5_HoursUTC 1000;
BA_ "NeedsUpdateBit" SG_ 2147484969 CalDataLoadP5_HoursUTC 1;
BA_ "GenSigSendType" SG_ 2147484969 CalDataLoadP5_MinutesUTC 1;
BA_ "GenSigCycleTime" SG_ 2147484969 CalDataLoadP5_MinutesUTC 100;
BA_ "GenSigCycleTimeActive" SG_ 2147484969 CalDataLoadP5_MinutesUTC 100;
BA_ "GenSigStartValue" SG_ 2147484969 CalDataLoadP5_MinutesUTC 255;
BA_ "GenSigMaxLatency" SG_ 2147484969 CalDataLoadP5_MinutesUTC 1000;
BA_ "NeedsUpdateBit" SG_ 2147484969 CalDataLoadP5_MinutesUTC 1;
BA_ "GenSigSendType" SG_ 2147484969 CalDataLoadP5_QF 1;
BA_ "GenSigCycleTime" SG_ 2147484969 CalDataLoadP5_QF 100;
BA_ "GenSigCycleTimeActive" SG_ 2147484969 CalDataLoadP5_QF 100;
BA_ "GenSigStartValue" SG_ 2147484969 CalDataLoadP5_QF 65535;
BA_ "GenSigMaxLatency" SG_ 2147484969 CalDataLoadP5_QF 1000;
BA_ "GenSigSendType" SG_ 2147484969 CalDataLoadP5_MonthUTC 1;
BA_ "GenSigCycleTime" SG_ 2147484969 CalDataLoadP5_MonthUTC 100;
BA_ "GenSigCycleTimeActive" SG_ 2147484969 CalDataLoadP5_MonthUTC 100;
BA_ "GenSigStartValue" SG_ 2147484969 CalDataLoadP5_MonthUTC 255;
BA_ "GenSigMaxLatency" SG_ 2147484969 CalDataLoadP5_MonthUTC 1000;
BA_ "NeedsUpdateBit" SG_ 2147484969 CalDataLoadP5_MonthUTC 1;
BA_ "GenSigSendType" SG_ 2147484973 VMCU_BB2_115S_FCS 7;
BA_ "GenSigSendType" SG_ 2147484968 CalDataLoadP4_DayUTC 1;
BA_ "GenSigCycleTime" SG_ 2147484968 CalDataLoadP4_DayUTC 100;
BA_ "GenSigCycleTimeActive" SG_ 2147484968 CalDataLoadP4_DayUTC 100;
BA_ "GenSigStartValue" SG_ 2147484968 CalDataLoadP4_DayUTC 255;
BA_ "GenSigMaxLatency" SG_ 2147484968 CalDataLoadP4_DayUTC 1000;
BA_ "NeedsUpdateBit" SG_ 2147484968 CalDataLoadP4_DayUTC 1;
BA_ "GenSigSendType" SG_ 2147484968 CalDataLoadP4_ScaleLoad 1;
BA_ "GenSigCycleTime" SG_ 2147484968 CalDataLoadP4_ScaleLoad 100;
BA_ "GenSigCycleTimeActive" SG_ 2147484968 CalDataLoadP4_ScaleLoad 100;
BA_ "GenSigStartValue" SG_ 2147484968 CalDataLoadP4_ScaleLoad 65535;
BA_ "GenSigMaxLatency" SG_ 2147484968 CalDataLoadP4_ScaleLoad 1000;
BA_ "NeedsUpdateBit" SG_ 2147484968 CalDataLoadP4_ScaleLoad 1;
BA_ "GenSigSendType" SG_ 2147484968 CalDataLoadP4_sg_UB 7;
BA_ "GenSigSendType" SG_ 2147484968 CalDataLoadP4_YearUTC 1;
BA_ "GenSigCycleTime" SG_ 2147484968 CalDataLoadP4_YearUTC 100;
BA_ "GenSigCycleTimeActive" SG_ 2147484968 CalDataLoadP4_YearUTC 100;
BA_ "GenSigStartValue" SG_ 2147484968 CalDataLoadP4_YearUTC 255;
BA_ "GenSigMaxLatency" SG_ 2147484968 CalDataLoadP4_YearUTC 1000;
BA_ "NeedsUpdateBit" SG_ 2147484968 CalDataLoadP4_YearUTC 1;
BA_ "GenSigSendType" SG_ 2147484968 CalDataLoadP4_AxleID 1;
BA_ "GenSigCycleTime" SG_ 2147484968 CalDataLoadP4_AxleID 100;
BA_ "GenSigCycleTimeActive" SG_ 2147484968 CalDataLoadP4_AxleID 100;
BA_ "GenSigStartValue" SG_ 2147484968 CalDataLoadP4_AxleID 15;
BA_ "GenSigMaxLatency" SG_ 2147484968 CalDataLoadP4_AxleID 1000;
BA_ "NeedsUpdateBit" SG_ 2147484968 CalDataLoadP4_AxleID 1;
BA_ "GenSigSendType" SG_ 2147484968 CalDataLoadP4_UncalLoad 1;
BA_ "GenSigCycleTime" SG_ 2147484968 CalDataLoadP4_UncalLoad 100;
BA_ "GenSigCycleTimeActive" SG_ 2147484968 CalDataLoadP4_UncalLoad 100;
BA_ "GenSigStartValue" SG_ 2147484968 CalDataLoadP4_UncalLoad 65535;
BA_ "GenSigMaxLatency" SG_ 2147484968 CalDataLoadP4_UncalLoad 1000;
BA_ "NeedsUpdateBit" SG_ 2147484968 CalDataLoadP4_UncalLoad 1;
BA_ "GenSigSendType" SG_ 2147484968 CalDataLoadP4_VehicleID 1;
BA_ "GenSigCycleTime" SG_ 2147484968 CalDataLoadP4_VehicleID 100;
BA_ "GenSigCycleTimeActive" SG_ 2147484968 CalDataLoadP4_VehicleID 100;
BA_ "GenSigStartValue" SG_ 2147484968 CalDataLoadP4_VehicleID 7;
BA_ "GenSigMaxLatency" SG_ 2147484968 CalDataLoadP4_VehicleID 1000;
BA_ "NeedsUpdateBit" SG_ 2147484968 CalDataLoadP4_VehicleID 1;
BA_ "GenSigSendType" SG_ 2147484968 CalDataLoadP4_MinutesUTC 1;
BA_ "GenSigCycleTime" SG_ 2147484968 CalDataLoadP4_MinutesUTC 100;
BA_ "GenSigCycleTimeActive" SG_ 2147484968 CalDataLoadP4_MinutesUTC 100;
BA_ "GenSigStartValue" SG_ 2147484968 CalDataLoadP4_MinutesUTC 255;
BA_ "GenSigMaxLatency" SG_ 2147484968 CalDataLoadP4_MinutesUTC 1000;
BA_ "NeedsUpdateBit" SG_ 2147484968 CalDataLoadP4_MinutesUTC 1;
BA_ "GenSigSendType" SG_ 2147484968 CalDataLoadP4_HoursUTC 1;
BA_ "GenSigCycleTime" SG_ 2147484968 CalDataLoadP4_HoursUTC 100;
BA_ "GenSigCycleTimeActive" SG_ 2147484968 CalDataLoadP4_HoursUTC 100;
BA_ "GenSigStartValue" SG_ 2147484968 CalDataLoadP4_HoursUTC 255;
BA_ "GenSigMaxLatency" SG_ 2147484968 CalDataLoadP4_HoursUTC 1000;
BA_ "NeedsUpdateBit" SG_ 2147484968 CalDataLoadP4_HoursUTC 1;
BA_ "GenSigSendType" SG_ 2147484968 CalDataLoadP4_MonthUTC 1;
BA_ "GenSigCycleTime" SG_ 2147484968 CalDataLoadP4_MonthUTC 100;
BA_ "GenSigCycleTimeActive" SG_ 2147484968 CalDataLoadP4_MonthUTC 100;
BA_ "GenSigStartValue" SG_ 2147484968 CalDataLoadP4_MonthUTC 255;
BA_ "GenSigMaxLatency" SG_ 2147484968 CalDataLoadP4_MonthUTC 1000;
BA_ "NeedsUpdateBit" SG_ 2147484968 CalDataLoadP4_MonthUTC 1;
BA_ "GenSigSendType" SG_ 2147484968 CalDataLoadP4_QF 1;
BA_ "GenSigCycleTime" SG_ 2147484968 CalDataLoadP4_QF 100;
BA_ "GenSigCycleTimeActive" SG_ 2147484968 CalDataLoadP4_QF 100;
BA_ "GenSigStartValue" SG_ 2147484968 CalDataLoadP4_QF 65535;
BA_ "GenSigMaxLatency" SG_ 2147484968 CalDataLoadP4_QF 1000;
BA_ "GenSigSendType" SG_ 2147484972 VMCU_BB2_114S_FCS 7;
BA_ "GenSigSendType" SG_ 2147484967 CalDataLoadP3_HoursUTC 1;
BA_ "GenSigCycleTime" SG_ 2147484967 CalDataLoadP3_HoursUTC 100;
BA_ "GenSigCycleTimeActive" SG_ 2147484967 CalDataLoadP3_HoursUTC 100;
BA_ "GenSigStartValue" SG_ 2147484967 CalDataLoadP3_HoursUTC 255;
BA_ "GenSigMaxLatency" SG_ 2147484967 CalDataLoadP3_HoursUTC 1000;
BA_ "NeedsUpdateBit" SG_ 2147484967 CalDataLoadP3_HoursUTC 1;
BA_ "GenSigSendType" SG_ 2147484967 CalDataLoadP3_YearUTC 1;
BA_ "GenSigCycleTime" SG_ 2147484967 CalDataLoadP3_YearUTC 100;
BA_ "GenSigCycleTimeActive" SG_ 2147484967 CalDataLoadP3_YearUTC 100;
BA_ "GenSigStartValue" SG_ 2147484967 CalDataLoadP3_YearUTC 255;
BA_ "GenSigMaxLatency" SG_ 2147484967 CalDataLoadP3_YearUTC 1000;
BA_ "NeedsUpdateBit" SG_ 2147484967 CalDataLoadP3_YearUTC 1;
BA_ "GenSigSendType" SG_ 2147484967 CalDataLoadP3_MonthUTC 1;
BA_ "GenSigCycleTime" SG_ 2147484967 CalDataLoadP3_MonthUTC 100;
BA_ "GenSigCycleTimeActive" SG_ 2147484967 CalDataLoadP3_MonthUTC 100;
BA_ "GenSigStartValue" SG_ 2147484967 CalDataLoadP3_MonthUTC 255;
BA_ "GenSigMaxLatency" SG_ 2147484967 CalDataLoadP3_MonthUTC 1000;
BA_ "NeedsUpdateBit" SG_ 2147484967 CalDataLoadP3_MonthUTC 1;
BA_ "GenSigSendType" SG_ 2147484967 CalDataLoadP3_DayUTC 1;
BA_ "GenSigCycleTime" SG_ 2147484967 CalDataLoadP3_DayUTC 100;
BA_ "GenSigCycleTimeActive" SG_ 2147484967 CalDataLoadP3_DayUTC 100;
BA_ "GenSigStartValue" SG_ 2147484967 CalDataLoadP3_DayUTC 255;
BA_ "GenSigMaxLatency" SG_ 2147484967 CalDataLoadP3_DayUTC 1000;
BA_ "NeedsUpdateBit" SG_ 2147484967 CalDataLoadP3_DayUTC 1;
BA_ "GenSigSendType" SG_ 2147484967 CalDataLoadP3_sg_UB 7;
BA_ "GenSigSendType" SG_ 2147484967 CalDataLoadP3_MinutesUTC 1;
BA_ "GenSigCycleTime" SG_ 2147484967 CalDataLoadP3_MinutesUTC 100;
BA_ "GenSigCycleTimeActive" SG_ 2147484967 CalDataLoadP3_MinutesUTC 100;
BA_ "GenSigStartValue" SG_ 2147484967 CalDataLoadP3_MinutesUTC 255;
BA_ "GenSigMaxLatency" SG_ 2147484967 CalDataLoadP3_MinutesUTC 1000;
BA_ "NeedsUpdateBit" SG_ 2147484967 CalDataLoadP3_MinutesUTC 1;
BA_ "GenSigSendType" SG_ 2147484967 CalDataLoadP3_QF 1;
BA_ "GenSigCycleTime" SG_ 2147484967 CalDataLoadP3_QF 100;
BA_ "GenSigCycleTimeActive" SG_ 2147484967 CalDataLoadP3_QF 100;
BA_ "GenSigStartValue" SG_ 2147484967 CalDataLoadP3_QF 65535;
BA_ "GenSigMaxLatency" SG_ 2147484967 CalDataLoadP3_QF 1000;
BA_ "GenSigSendType" SG_ 2147484967 CalDataLoadP3_VehicleID 1;
BA_ "GenSigCycleTime" SG_ 2147484967 CalDataLoadP3_VehicleID 100;
BA_ "GenSigCycleTimeActive" SG_ 2147484967 CalDataLoadP3_VehicleID 100;
BA_ "GenSigStartValue" SG_ 2147484967 CalDataLoadP3_VehicleID 7;
BA_ "GenSigMaxLatency" SG_ 2147484967 CalDataLoadP3_VehicleID 1000;
BA_ "NeedsUpdateBit" SG_ 2147484967 CalDataLoadP3_VehicleID 1;
BA_ "GenSigSendType" SG_ 2147484967 CalDataLoadP3_UncalLoad 1;
BA_ "GenSigCycleTime" SG_ 2147484967 CalDataLoadP3_UncalLoad 100;
BA_ "GenSigCycleTimeActive" SG_ 2147484967 CalDataLoadP3_UncalLoad 100;
BA_ "GenSigStartValue" SG_ 2147484967 CalDataLoadP3_UncalLoad 65535;
BA_ "GenSigMaxLatency" SG_ 2147484967 CalDataLoadP3_UncalLoad 1000;
BA_ "NeedsUpdateBit" SG_ 2147484967 CalDataLoadP3_UncalLoad 1;
BA_ "GenSigSendType" SG_ 2147484967 CalDataLoadP3_AxleID 1;
BA_ "GenSigCycleTime" SG_ 2147484967 CalDataLoadP3_AxleID 100;
BA_ "GenSigCycleTimeActive" SG_ 2147484967 CalDataLoadP3_AxleID 100;
BA_ "GenSigStartValue" SG_ 2147484967 CalDataLoadP3_AxleID 15;
BA_ "GenSigMaxLatency" SG_ 2147484967 CalDataLoadP3_AxleID 1000;
BA_ "NeedsUpdateBit" SG_ 2147484967 CalDataLoadP3_AxleID 1;
BA_ "GenSigSendType" SG_ 2147484967 CalDataLoadP3_ScaleLoad 1;
BA_ "GenSigCycleTime" SG_ 2147484967 CalDataLoadP3_ScaleLoad 100;
BA_ "GenSigCycleTimeActive" SG_ 2147484967 CalDataLoadP3_ScaleLoad 100;
BA_ "GenSigStartValue" SG_ 2147484967 CalDataLoadP3_ScaleLoad 65535;
BA_ "GenSigMaxLatency" SG_ 2147484967 CalDataLoadP3_ScaleLoad 1000;
BA_ "NeedsUpdateBit" SG_ 2147484967 CalDataLoadP3_ScaleLoad 1;
BA_ "GenSigSendType" SG_ 2147484971 VMCU_BB2_113S_FCS 7;
BA_ "GenSigSendType" SG_ 2147484966 CalDataLoadP2_MinutesUTC 1;
BA_ "GenSigCycleTime" SG_ 2147484966 CalDataLoadP2_MinutesUTC 100;
BA_ "GenSigCycleTimeActive" SG_ 2147484966 CalDataLoadP2_MinutesUTC 100;
BA_ "GenSigStartValue" SG_ 2147484966 CalDataLoadP2_MinutesUTC 255;
BA_ "GenSigMaxLatency" SG_ 2147484966 CalDataLoadP2_MinutesUTC 1000;
BA_ "NeedsUpdateBit" SG_ 2147484966 CalDataLoadP2_MinutesUTC 1;
BA_ "GenSigSendType" SG_ 2147484966 CalDataLoadP2_AxleID 1;
BA_ "GenSigCycleTime" SG_ 2147484966 CalDataLoadP2_AxleID 100;
BA_ "GenSigCycleTimeActive" SG_ 2147484966 CalDataLoadP2_AxleID 100;
BA_ "GenSigStartValue" SG_ 2147484966 CalDataLoadP2_AxleID 15;
BA_ "GenSigMaxLatency" SG_ 2147484966 CalDataLoadP2_AxleID 1000;
BA_ "NeedsUpdateBit" SG_ 2147484966 CalDataLoadP2_AxleID 1;
BA_ "GenSigSendType" SG_ 2147484966 CalDataLoadP2_YearUTC 1;
BA_ "GenSigCycleTime" SG_ 2147484966 CalDataLoadP2_YearUTC 100;
BA_ "GenSigCycleTimeActive" SG_ 2147484966 CalDataLoadP2_YearUTC 100;
BA_ "GenSigStartValue" SG_ 2147484966 CalDataLoadP2_YearUTC 255;
BA_ "GenSigMaxLatency" SG_ 2147484966 CalDataLoadP2_YearUTC 1000;
BA_ "NeedsUpdateBit" SG_ 2147484966 CalDataLoadP2_YearUTC 1;
BA_ "GenSigSendType" SG_ 2147484966 CalDataLoadP2_UncalLoad 1;
BA_ "GenSigCycleTime" SG_ 2147484966 CalDataLoadP2_UncalLoad 100;
BA_ "GenSigCycleTimeActive" SG_ 2147484966 CalDataLoadP2_UncalLoad 100;
BA_ "GenSigStartValue" SG_ 2147484966 CalDataLoadP2_UncalLoad 65535;
BA_ "GenSigMaxLatency" SG_ 2147484966 CalDataLoadP2_UncalLoad 1000;
BA_ "NeedsUpdateBit" SG_ 2147484966 CalDataLoadP2_UncalLoad 1;
BA_ "GenSigSendType" SG_ 2147484966 CalDataLoadP2_DayUTC 1;
BA_ "GenSigCycleTime" SG_ 2147484966 CalDataLoadP2_DayUTC 100;
BA_ "GenSigCycleTimeActive" SG_ 2147484966 CalDataLoadP2_DayUTC 100;
BA_ "GenSigStartValue" SG_ 2147484966 CalDataLoadP2_DayUTC 255;
BA_ "GenSigMaxLatency" SG_ 2147484966 CalDataLoadP2_DayUTC 1000;
BA_ "NeedsUpdateBit" SG_ 2147484966 CalDataLoadP2_DayUTC 1;
BA_ "GenSigSendType" SG_ 2147484966 CalDataLoadP2_MonthUTC 1;
BA_ "GenSigCycleTime" SG_ 2147484966 CalDataLoadP2_MonthUTC 100;
BA_ "GenSigCycleTimeActive" SG_ 2147484966 CalDataLoadP2_MonthUTC 100;
BA_ "GenSigStartValue" SG_ 2147484966 CalDataLoadP2_MonthUTC 255;
BA_ "GenSigMaxLatency" SG_ 2147484966 CalDataLoadP2_MonthUTC 1000;
BA_ "NeedsUpdateBit" SG_ 2147484966 CalDataLoadP2_MonthUTC 1;
BA_ "GenSigSendType" SG_ 2147484966 CalDataLoadP2_VehicleID 1;
BA_ "GenSigCycleTime" SG_ 2147484966 CalDataLoadP2_VehicleID 100;
BA_ "GenSigCycleTimeActive" SG_ 2147484966 CalDataLoadP2_VehicleID 100;
BA_ "GenSigStartValue" SG_ 2147484966 CalDataLoadP2_VehicleID 7;
BA_ "GenSigMaxLatency" SG_ 2147484966 CalDataLoadP2_VehicleID 1000;
BA_ "NeedsUpdateBit" SG_ 2147484966 CalDataLoadP2_VehicleID 1;
BA_ "GenSigSendType" SG_ 2147484966 CalDataLoadP2_QF 1;
BA_ "GenSigCycleTime" SG_ 2147484966 CalDataLoadP2_QF 100;
BA_ "GenSigCycleTimeActive" SG_ 2147484966 CalDataLoadP2_QF 100;
BA_ "GenSigStartValue" SG_ 2147484966 CalDataLoadP2_QF 65535;
BA_ "GenSigMaxLatency" SG_ 2147484966 CalDataLoadP2_QF 1000;
BA_ "GenSigSendType" SG_ 2147484966 CalDataLoadP2_HoursUTC 1;
BA_ "GenSigCycleTime" SG_ 2147484966 CalDataLoadP2_HoursUTC 100;
BA_ "GenSigCycleTimeActive" SG_ 2147484966 CalDataLoadP2_HoursUTC 100;
BA_ "GenSigStartValue" SG_ 2147484966 CalDataLoadP2_HoursUTC 255;
BA_ "GenSigMaxLatency" SG_ 2147484966 CalDataLoadP2_HoursUTC 1000;
BA_ "NeedsUpdateBit" SG_ 2147484966 CalDataLoadP2_HoursUTC 1;
BA_ "GenSigSendType" SG_ 2147484966 CalDataLoadP2_sg_UB 7;
BA_ "GenSigSendType" SG_ 2147484966 CalDataLoadP2_ScaleLoad 1;
BA_ "GenSigCycleTime" SG_ 2147484966 CalDataLoadP2_ScaleLoad 100;
BA_ "GenSigCycleTimeActive" SG_ 2147484966 CalDataLoadP2_ScaleLoad 100;
BA_ "GenSigStartValue" SG_ 2147484966 CalDataLoadP2_ScaleLoad 65535;
BA_ "GenSigMaxLatency" SG_ 2147484966 CalDataLoadP2_ScaleLoad 1000;
BA_ "NeedsUpdateBit" SG_ 2147484966 CalDataLoadP2_ScaleLoad 1;
BA_ "GenSigSendType" SG_ 2147484970 VMCU_BB2_112S_FCS 7;
BA_ "GenSigSendType" SG_ 2147484965 CalDataLoadP1_ScaleLoad 1;
BA_ "GenSigCycleTime" SG_ 2147484965 CalDataLoadP1_ScaleLoad 100;
BA_ "GenSigCycleTimeActive" SG_ 2147484965 CalDataLoadP1_ScaleLoad 100;
BA_ "GenSigStartValue" SG_ 2147484965 CalDataLoadP1_ScaleLoad 65535;
BA_ "GenSigMaxLatency" SG_ 2147484965 CalDataLoadP1_ScaleLoad 1000;
BA_ "NeedsUpdateBit" SG_ 2147484965 CalDataLoadP1_ScaleLoad 1;
BA_ "GenSigSendType" SG_ 2147484965 CalDataLoadP1_YearUTC 1;
BA_ "GenSigCycleTime" SG_ 2147484965 CalDataLoadP1_YearUTC 100;
BA_ "GenSigCycleTimeActive" SG_ 2147484965 CalDataLoadP1_YearUTC 100;
BA_ "GenSigStartValue" SG_ 2147484965 CalDataLoadP1_YearUTC 255;
BA_ "GenSigMaxLatency" SG_ 2147484965 CalDataLoadP1_YearUTC 1000;
BA_ "NeedsUpdateBit" SG_ 2147484965 CalDataLoadP1_YearUTC 1;
BA_ "GenSigSendType" SG_ 2147484965 CalDataLoadP1_AxleID 1;
BA_ "GenSigCycleTime" SG_ 2147484965 CalDataLoadP1_AxleID 100;
BA_ "GenSigCycleTimeActive" SG_ 2147484965 CalDataLoadP1_AxleID 100;
BA_ "GenSigStartValue" SG_ 2147484965 CalDataLoadP1_AxleID 15;
BA_ "GenSigMaxLatency" SG_ 2147484965 CalDataLoadP1_AxleID 1000;
BA_ "NeedsUpdateBit" SG_ 2147484965 CalDataLoadP1_AxleID 1;
BA_ "GenSigSendType" SG_ 2147484965 CalDataLoadP1_MonthUTC 1;
BA_ "GenSigCycleTime" SG_ 2147484965 CalDataLoadP1_MonthUTC 100;
BA_ "GenSigCycleTimeActive" SG_ 2147484965 CalDataLoadP1_MonthUTC 100;
BA_ "GenSigStartValue" SG_ 2147484965 CalDataLoadP1_MonthUTC 255;
BA_ "GenSigMaxLatency" SG_ 2147484965 CalDataLoadP1_MonthUTC 1000;
BA_ "NeedsUpdateBit" SG_ 2147484965 CalDataLoadP1_MonthUTC 1;
BA_ "GenSigSendType" SG_ 2147484965 CalDataLoadP1_HoursUTC 1;
BA_ "GenSigCycleTime" SG_ 2147484965 CalDataLoadP1_HoursUTC 100;
BA_ "GenSigCycleTimeActive" SG_ 2147484965 CalDataLoadP1_HoursUTC 100;
BA_ "GenSigStartValue" SG_ 2147484965 CalDataLoadP1_HoursUTC 255;
BA_ "GenSigMaxLatency" SG_ 2147484965 CalDataLoadP1_HoursUTC 1000;
BA_ "NeedsUpdateBit" SG_ 2147484965 CalDataLoadP1_HoursUTC 1;
BA_ "GenSigSendType" SG_ 2147484965 CalDataLoadP1_VehicleID 1;
BA_ "GenSigCycleTime" SG_ 2147484965 CalDataLoadP1_VehicleID 100;
BA_ "GenSigCycleTimeActive" SG_ 2147484965 CalDataLoadP1_VehicleID 100;
BA_ "GenSigStartValue" SG_ 2147484965 CalDataLoadP1_VehicleID 7;
BA_ "GenSigMaxLatency" SG_ 2147484965 CalDataLoadP1_VehicleID 1000;
BA_ "NeedsUpdateBit" SG_ 2147484965 CalDataLoadP1_VehicleID 1;
BA_ "GenSigSendType" SG_ 2147484965 CalDataLoadP1_UncalLoad 1;
BA_ "GenSigCycleTime" SG_ 2147484965 CalDataLoadP1_UncalLoad 100;
BA_ "GenSigCycleTimeActive" SG_ 2147484965 CalDataLoadP1_UncalLoad 100;
BA_ "GenSigStartValue" SG_ 2147484965 CalDataLoadP1_UncalLoad 65535;
BA_ "GenSigMaxLatency" SG_ 2147484965 CalDataLoadP1_UncalLoad 1000;
BA_ "NeedsUpdateBit" SG_ 2147484965 CalDataLoadP1_UncalLoad 1;
BA_ "GenSigSendType" SG_ 2147484965 CalDataLoadP1_QF 1;
BA_ "GenSigCycleTime" SG_ 2147484965 CalDataLoadP1_QF 100;
BA_ "GenSigCycleTimeActive" SG_ 2147484965 CalDataLoadP1_QF 100;
BA_ "GenSigStartValue" SG_ 2147484965 CalDataLoadP1_QF 65535;
BA_ "GenSigMaxLatency" SG_ 2147484965 CalDataLoadP1_QF 1000;
BA_ "GenSigSendType" SG_ 2147484965 CalDataLoadP1_DayUTC 1;
BA_ "GenSigCycleTime" SG_ 2147484965 CalDataLoadP1_DayUTC 100;
BA_ "GenSigCycleTimeActive" SG_ 2147484965 CalDataLoadP1_DayUTC 100;
BA_ "GenSigStartValue" SG_ 2147484965 CalDataLoadP1_DayUTC 255;
BA_ "GenSigMaxLatency" SG_ 2147484965 CalDataLoadP1_DayUTC 1000;
BA_ "NeedsUpdateBit" SG_ 2147484965 CalDataLoadP1_DayUTC 1;
BA_ "GenSigSendType" SG_ 2147484965 CalDataLoadP1_sg_UB 7;
BA_ "GenSigSendType" SG_ 2147484965 CalDataLoadP1_MinutesUTC 1;
BA_ "GenSigCycleTime" SG_ 2147484965 CalDataLoadP1_MinutesUTC 100;
BA_ "GenSigCycleTimeActive" SG_ 2147484965 CalDataLoadP1_MinutesUTC 100;
BA_ "GenSigStartValue" SG_ 2147484965 CalDataLoadP1_MinutesUTC 255;
BA_ "GenSigMaxLatency" SG_ 2147484965 CalDataLoadP1_MinutesUTC 1000;
BA_ "NeedsUpdateBit" SG_ 2147484965 CalDataLoadP1_MinutesUTC 1;
BA_ "GenSigCycleTime" SG_ 2147484701 AlarmClockAlarms_stat_Mode_ISig_ 100;
BA_ "GenSigCycleTimeActive" SG_ 2147484701 AlarmClockAlarms_stat_Mode_ISig_ 100;
BA_ "GenSigMaxLatency" SG_ 2147484701 AlarmClockAlarms_stat_Mode_ISig_ 169;
BA_ "Platform_VMCU1_Sig" SG_ 2147484701 AlarmClockAlarms_stat_Mode_ISig_ 1;
BA_ "SystemSignalLongSymbol" SG_ 2147484701 AlarmClockAlarms_stat_Mode_ISig_ "AlarmClockAlarms_stat_Mode_ISig_4";
BA_ "GenSigCycleTime" SG_ 2147484701 AlarmClockAlarms_stat_Type_ISig_ 100;
BA_ "GenSigCycleTimeActive" SG_ 2147484701 AlarmClockAlarms_stat_Type_ISig_ 100;
BA_ "GenSigStartValue" SG_ 2147484701 AlarmClockAlarms_stat_Type_ISig_ 7;
BA_ "GenSigMaxLatency" SG_ 2147484701 AlarmClockAlarms_stat_Type_ISig_ 169;
BA_ "Platform_VMCU1_Sig" SG_ 2147484701 AlarmClockAlarms_stat_Type_ISig_ 1;
BA_ "SystemSignalLongSymbol" SG_ 2147484701 AlarmClockAlarms_stat_Type_ISig_ "AlarmClockAlarms_stat_Type_ISig_4";
BA_ "GenSigCycleTime" SG_ 2147484701 AlarmClockAlarms_stat_DaySet_ISi 100;
BA_ "GenSigCycleTimeActive" SG_ 2147484701 AlarmClockAlarms_stat_DaySet_ISi 100;
BA_ "GenSigMaxLatency" SG_ 2147484701 AlarmClockAlarms_stat_DaySet_ISi 169;
BA_ "Platform_VMCU1_Sig" SG_ 2147484701 AlarmClockAlarms_stat_DaySet_ISi 1;
BA_ "SystemSignalLongSymbol" SG_ 2147484701 AlarmClockAlarms_stat_DaySet_ISi "AlarmClockAlarms_stat_DaySet_ISig_4";
BA_ "GenSigCycleTime" SG_ 2147484701 AlarmClockAlarms_stat_ID_ISig_4 100;
BA_ "GenSigCycleTimeActive" SG_ 2147484701 AlarmClockAlarms_stat_ID_ISig_4 100;
BA_ "GenSigStartValue" SG_ 2147484701 AlarmClockAlarms_stat_ID_ISig_4 127;
BA_ "GenSigMaxLatency" SG_ 2147484701 AlarmClockAlarms_stat_ID_ISig_4 169;
BA_ "Platform_VMCU1_Sig" SG_ 2147484701 AlarmClockAlarms_stat_ID_ISig_4 1;
BA_ "GenSigCycleTime" SG_ 2147484701 AlmClkCurAlarm_stat_SetMin 100;
BA_ "GenSigCycleTimeActive" SG_ 2147484701 AlmClkCurAlarm_stat_SetMin 100;
BA_ "GenSigStartValue" SG_ 2147484701 AlmClkCurAlarm_stat_SetMin 63;
BA_ "GenSigMaxLatency" SG_ 2147484701 AlmClkCurAlarm_stat_SetMin 169;
BA_ "Platform_VMCU1_Sig" SG_ 2147484701 AlmClkCurAlarm_stat_SetMin 1;
BA_ "GenSigCycleTime" SG_ 2147484701 AlarmClockAlarms_stat_Stat_ISig_ 100;
BA_ "GenSigCycleTimeActive" SG_ 2147484701 AlarmClockAlarms_stat_Stat_ISig_ 100;
BA_ "GenSigMaxLatency" SG_ 2147484701 AlarmClockAlarms_stat_Stat_ISig_ 169;
BA_ "Platform_VMCU1_Sig" SG_ 2147484701 AlarmClockAlarms_stat_Stat_ISig_ 1;
BA_ "SystemSignalLongSymbol" SG_ 2147484701 AlarmClockAlarms_stat_Stat_ISig_ "AlarmClockAlarms_stat_Stat_ISig_4";
BA_ "GenSigCycleTime" SG_ 2147484701 AlmClkCurAlarm_stat_Stat 100;
BA_ "GenSigCycleTimeActive" SG_ 2147484701 AlmClkCurAlarm_stat_Stat 100;
BA_ "GenSigMaxLatency" SG_ 2147484701 AlmClkCurAlarm_stat_Stat 169;
BA_ "Platform_VMCU1_Sig" SG_ 2147484701 AlmClkCurAlarm_stat_Stat 1;
BA_ "GenSigCycleTime" SG_ 2147484701 AlmClkCurAlarm_stat_ID 100;
BA_ "GenSigCycleTimeActive" SG_ 2147484701 AlmClkCurAlarm_stat_ID 100;
BA_ "GenSigStartValue" SG_ 2147484701 AlmClkCurAlarm_stat_ID 127;
BA_ "GenSigMaxLatency" SG_ 2147484701 AlmClkCurAlarm_stat_ID 169;
BA_ "Platform_VMCU1_Sig" SG_ 2147484701 AlmClkCurAlarm_stat_ID 1;
BA_ "GenSigCycleTime" SG_ 2147484701 AlarmClockAlarms_stat_SetMin_ISi 100;
BA_ "GenSigCycleTimeActive" SG_ 2147484701 AlarmClockAlarms_stat_SetMin_ISi 100;
BA_ "GenSigStartValue" SG_ 2147484701 AlarmClockAlarms_stat_SetMin_ISi 63;
BA_ "GenSigMaxLatency" SG_ 2147484701 AlarmClockAlarms_stat_SetMin_ISi 169;
BA_ "Platform_VMCU1_Sig" SG_ 2147484701 AlarmClockAlarms_stat_SetMin_ISi 1;
BA_ "SystemSignalLongSymbol" SG_ 2147484701 AlarmClockAlarms_stat_SetMin_ISi "AlarmClockAlarms_stat_SetMin_ISig_4";
BA_ "GenSigCycleTime" SG_ 2147484701 AlmClkCurAlarm_stat_Type 100;
BA_ "GenSigCycleTimeActive" SG_ 2147484701 AlmClkCurAlarm_stat_Type 100;
BA_ "GenSigStartValue" SG_ 2147484701 AlmClkCurAlarm_stat_Type 7;
BA_ "GenSigMaxLatency" SG_ 2147484701 AlmClkCurAlarm_stat_Type 169;
BA_ "Platform_VMCU1_Sig" SG_ 2147484701 AlmClkCurAlarm_stat_Type 1;
BA_ "GenSigCycleTime" SG_ 2147484701 AlarmClockAlarms_stat_SetHr_ISig 100;
BA_ "GenSigCycleTimeActive" SG_ 2147484701 AlarmClockAlarms_stat_SetHr_ISig 100;
BA_ "GenSigStartValue" SG_ 2147484701 AlarmClockAlarms_stat_SetHr_ISig 31;
BA_ "GenSigMaxLatency" SG_ 2147484701 AlarmClockAlarms_stat_SetHr_ISig 169;
BA_ "Platform_VMCU1_Sig" SG_ 2147484701 AlarmClockAlarms_stat_SetHr_ISig 1;
BA_ "SystemSignalLongSymbol" SG_ 2147484701 AlarmClockAlarms_stat_SetHr_ISig "AlarmClockAlarms_stat_SetHr_ISig_4";
BA_ "GenSigCycleTime" SG_ 2147484701 AlmClkCurAlarm_stat_SetHr 100;
BA_ "GenSigCycleTimeActive" SG_ 2147484701 AlmClkCurAlarm_stat_SetHr 100;
BA_ "GenSigStartValue" SG_ 2147484701 AlmClkCurAlarm_stat_SetHr 31;
BA_ "GenSigMaxLatency" SG_ 2147484701 AlmClkCurAlarm_stat_SetHr 169;
BA_ "Platform_VMCU1_Sig" SG_ 2147484701 AlmClkCurAlarm_stat_SetHr 1;
BA_ "GenSigCycleTime" SG_ 2147484743 ParkHeaterTimerReleased_stat_ISi 100;
BA_ "GenSigCycleTimeActive" SG_ 2147484743 ParkHeaterTimerReleased_stat_ISi 100;
BA_ "GenSigStartValue" SG_ 2147484743 ParkHeaterTimerReleased_stat_ISi 3;
BA_ "GenSigMaxLatency" SG_ 2147484743 ParkHeaterTimerReleased_stat_ISi 150;
BA_ "Platform_VMCU1_Sig" SG_ 2147484743 ParkHeaterTimerReleased_stat_ISi 1;
BA_ "SystemSignalLongSymbol" SG_ 2147484743 ParkHeaterTimerReleased_stat_ISi "ParkHeaterTimerReleased_stat_ISig_4";
BA_ "GenSigCycleTime" SG_ 2147484743 PHTimerRqstAck_Hours_ISig_4 100;
BA_ "GenSigCycleTimeActive" SG_ 2147484743 PHTimerRqstAck_Hours_ISig_4 100;
BA_ "GenSigStartValue" SG_ 2147484743 PHTimerRqstAck_Hours_ISig_4 255;
BA_ "GenSigMaxLatency" SG_ 2147484743 PHTimerRqstAck_Hours_ISig_4 150;
BA_ "Platform_VMCU1_Sig" SG_ 2147484743 PHTimerRqstAck_Hours_ISig_4 1;
BA_ "GenSigCycleTime" SG_ 2147484743 PHTimerRqstAck_CurrentOp_ISig_4 100;
BA_ "GenSigCycleTimeActive" SG_ 2147484743 PHTimerRqstAck_CurrentOp_ISig_4 100;
BA_ "GenSigStartValue" SG_ 2147484743 PHTimerRqstAck_CurrentOp_ISig_4 3;
BA_ "GenSigMaxLatency" SG_ 2147484743 PHTimerRqstAck_CurrentOp_ISig_4 150;
BA_ "Platform_VMCU1_Sig" SG_ 2147484743 PHTimerRqstAck_CurrentOp_ISig_4 1;
BA_ "GenSigCycleTime" SG_ 2147484743 PHTimerRqstAck_DayOfWeekRq_ISig_ 100;
BA_ "GenSigCycleTimeActive" SG_ 2147484743 PHTimerRqstAck_DayOfWeekRq_ISig_ 100;
BA_ "GenSigStartValue" SG_ 2147484743 PHTimerRqstAck_DayOfWeekRq_ISig_ 15;
BA_ "GenSigMaxLatency" SG_ 2147484743 PHTimerRqstAck_DayOfWeekRq_ISig_ 150;
BA_ "Platform_VMCU1_Sig" SG_ 2147484743 PHTimerRqstAck_DayOfWeekRq_ISig_ 1;
BA_ "SystemSignalLongSymbol" SG_ 2147484743 PHTimerRqstAck_DayOfWeekRq_ISig_ "PHTimerRqstAck_DayOfWeekRq_ISig_4";
BA_ "GenSigCycleTime" SG_ 2147484743 PHTimerRqstAck_Minutes_ISig_4 100;
BA_ "GenSigCycleTimeActive" SG_ 2147484743 PHTimerRqstAck_Minutes_ISig_4 100;
BA_ "GenSigStartValue" SG_ 2147484743 PHTimerRqstAck_Minutes_ISig_4 255;
BA_ "GenSigMaxLatency" SG_ 2147484743 PHTimerRqstAck_Minutes_ISig_4 150;
BA_ "Platform_VMCU1_Sig" SG_ 2147484743 PHTimerRqstAck_Minutes_ISig_4 1;
BA_ "GenSigCycleTime" SG_ 2147484743 AlarmClockNotification_Stat_ISig 100;
BA_ "GenSigCycleTimeActive" SG_ 2147484743 AlarmClockNotification_Stat_ISig 100;
BA_ "GenSigMaxLatency" SG_ 2147484743 AlarmClockNotification_Stat_ISig 150;
BA_ "Platform_VMCU1_Sig" SG_ 2147484743 AlarmClockNotification_Stat_ISig 1;
BA_ "SystemSignalLongSymbol" SG_ 2147484743 AlarmClockNotification_Stat_ISig "AlarmClockNotification_Stat_ISig_4";
BA_ "GenSigCycleTime" SG_ 2147484743 AlarmClockNotification_Type_ISig 100;
BA_ "GenSigCycleTimeActive" SG_ 2147484743 AlarmClockNotification_Type_ISig 100;
BA_ "GenSigStartValue" SG_ 2147484743 AlarmClockNotification_Type_ISig 7;
BA_ "GenSigMaxLatency" SG_ 2147484743 AlarmClockNotification_Type_ISig 150;
BA_ "Platform_VMCU1_Sig" SG_ 2147484743 AlarmClockNotification_Type_ISig 1;
BA_ "SystemSignalLongSymbol" SG_ 2147484743 AlarmClockNotification_Type_ISig "AlarmClockNotification_Type_ISig_4";
BA_ "GenSigCycleTime" SG_ 2147484743 AlarmClockNotification_ID_ISig_4 100;
BA_ "GenSigCycleTimeActive" SG_ 2147484743 AlarmClockNotification_ID_ISig_4 100;
BA_ "GenSigStartValue" SG_ 2147484743 AlarmClockNotification_ID_ISig_4 127;
BA_ "GenSigMaxLatency" SG_ 2147484743 AlarmClockNotification_ID_ISig_4 150;
BA_ "Platform_VMCU1_Sig" SG_ 2147484743 AlarmClockNotification_ID_ISig_4 1;
BA_ "GenSigCycleTime" SG_ 2147484921 HighResolutionTripDistance2 100;
BA_ "GenSigCycleTimeActive" SG_ 2147484921 HighResolutionTripDistance2 100;
BA_ "GenSigStartValue" SG_ 2147484921 HighResolutionTripDistance2 4294967295;
BA_ "GenSigMaxLatency" SG_ 2147484921 HighResolutionTripDistance2 251;
BA_ "Platform_VMCU1_Sig" SG_ 2147484921 HighResolutionTripDistance2 1;
BA_ "SeToolAncestorID_SIGNAL" SG_ 2147484921 HighResolutionTripDistance2 "x0000001D0417BFE5";
BA_ "SeToolItemID_SIGNAL" SG_ 2147484921 HighResolutionTripDistance2 "x0000001D0417BFE5";
BA_ "SeToolName_SIGNAL" SG_ 2147484921 HighResolutionTripDistance2 "HighResolutionTripDistance2";
BA_ "SeToolVersion_SIGNAL" SG_ 2147484921 HighResolutionTripDistance2 "1";
BA_ "GenSigCycleTime" SG_ 2147484921 HighResolutionTripDistance1_ISig 100;
BA_ "GenSigCycleTimeActive" SG_ 2147484921 HighResolutionTripDistance1_ISig 100;
BA_ "GenSigStartValue" SG_ 2147484921 HighResolutionTripDistance1_ISig 4294967295;
BA_ "GenSigMaxLatency" SG_ 2147484921 HighResolutionTripDistance1_ISig 251;
BA_ "Platform_VMCU1_Sig" SG_ 2147484921 HighResolutionTripDistance1_ISig 1;
BA_ "SeToolAncestorID_SIGNAL" SG_ 2147484921 HighResolutionTripDistance1_ISig "x0000001D0417BFE5";
BA_ "SeToolItemID_SIGNAL" SG_ 2147484921 HighResolutionTripDistance1_ISig "x0000001D0417BFE5";
BA_ "SeToolName_SIGNAL" SG_ 2147484921 HighResolutionTripDistance1_ISig "HighResolutionTripDistance1";
BA_ "SeToolVersion_SIGNAL" SG_ 2147484921 HighResolutionTripDistance1_ISig "1";
BA_ "SystemSignalLongSymbol" SG_ 2147484921 HighResolutionTripDistance1_ISig "HighResolutionTripDistance1_ISig_4";
BA_ "GenSigCycleTime" SG_ 2147484964 LoadIndCalWarning_Movement 100;
BA_ "GenSigCycleTimeActive" SG_ 2147484964 LoadIndCalWarning_Movement 100;
BA_ "GenSigCycleTime" SG_ 2147484964 LoadIndCalWarning_LiftedAxle 100;
BA_ "GenSigCycleTimeActive" SG_ 2147484964 LoadIndCalWarning_LiftedAxle 100;
BA_ "GenSigStartValue" SG_ 2147484964 LoadIndCalWarning_LiftedAxle 3;
BA_ "GenSigCycleTime" SG_ 2147484964 LoadIndCalWarning_LowSupplyPress 100;
BA_ "GenSigCycleTimeActive" SG_ 2147484964 LoadIndCalWarning_LowSupplyPress 100;
BA_ "GenSigStartValue" SG_ 2147484964 LoadIndCalWarning_LowSupplyPress 3;
BA_ "GenSigCycleTime" SG_ 2147484964 LoadIndCalWarning_PBrakeApplied 100;
BA_ "GenSigCycleTimeActive" SG_ 2147484964 LoadIndCalWarning_PBrakeApplied 100;
BA_ "GenSigStartValue" SG_ 2147484964 LoadIndCalWarning_PBrakeApplied 3;
BA_ "GenSigCycleTime" SG_ 2147484964 LoadIndCalWarning_SBrakesApplied 100;
BA_ "GenSigCycleTimeActive" SG_ 2147484964 LoadIndCalWarning_SBrakesApplied 100;
BA_ "GenSigStartValue" SG_ 2147484964 LoadIndCalWarning_SBrakesApplied 3;
BA_ "GenSigCycleTime" SG_ 2147484964 LoadIndCalWarning_HighInclin 100;
BA_ "GenSigCycleTimeActive" SG_ 2147484964 LoadIndCalWarning_HighInclin 100;
BA_ "GenSigStartValue" SG_ 2147484964 LoadIndCalWarning_HighInclin 3;
BA_ "GenSigCycleTime" SG_ 2147484964 LoadTrailer3_ISig_4 100;
BA_ "GenSigCycleTimeActive" SG_ 2147484964 LoadTrailer3_ISig_4 100;
BA_ "GenSigStartValue" SG_ 2147484964 LoadTrailer3_ISig_4 65535;
BA_ "GenSigCycleTime" SG_ 2147484964 LoadVehCombCargoTot 100;
BA_ "GenSigCycleTimeActive" SG_ 2147484964 LoadVehCombCargoTot 100;
BA_ "GenSigStartValue" SG_ 2147484964 LoadVehCombCargoTot 65535;
BA_ "GenSigCycleTime" SG_ 2147484964 LoadIndCalWarning_GearNotNeutral 100;
BA_ "GenSigCycleTimeActive" SG_ 2147484964 LoadIndCalWarning_GearNotNeutral 100;
BA_ "GenSigStartValue" SG_ 2147484964 LoadIndCalWarning_GearNotNeutral 3;
BA_ "GenSigCycleTime" SG_ 2147484964 LoadIndCalWarning_HighLoadDelta 100;
BA_ "GenSigCycleTimeActive" SG_ 2147484964 LoadIndCalWarning_HighLoadDelta 100;
BA_ "GenSigStartValue" SG_ 2147484964 LoadIndCalWarning_HighLoadDelta 3;
BA_ "GenSigCycleTime" SG_ 2147484963 LoadTrailer2Back 100;
BA_ "GenSigCycleTimeActive" SG_ 2147484963 LoadTrailer2Back 100;
BA_ "GenSigStartValue" SG_ 2147484963 LoadTrailer2Back 65535;
BA_ "GenSigCycleTime" SG_ 2147484963 LoadTrailer3Front 100;
BA_ "GenSigCycleTimeActive" SG_ 2147484963 LoadTrailer3Front 100;
BA_ "GenSigStartValue" SG_ 2147484963 LoadTrailer3Front 65535;
BA_ "GenSigCycleTime" SG_ 2147484963 LoadTrailer5Back 100;
BA_ "GenSigCycleTimeActive" SG_ 2147484963 LoadTrailer5Back 100;
BA_ "GenSigStartValue" SG_ 2147484963 LoadTrailer5Back 65535;
BA_ "GenSigCycleTime" SG_ 2147484963 LoadTrailer4Front 100;
BA_ "GenSigCycleTimeActive" SG_ 2147484963 LoadTrailer4Front 100;
BA_ "GenSigStartValue" SG_ 2147484963 LoadTrailer4Front 65535;
BA_ "GenSigCycleTime" SG_ 2147484962 LoadTrailer1Front 100;
BA_ "GenSigCycleTimeActive" SG_ 2147484962 LoadTrailer1Front 100;
BA_ "GenSigStartValue" SG_ 2147484962 LoadTrailer1Front 65535;
BA_ "GenSigCycleTime" SG_ 2147484962 LoadTruck_ISig_4 100;
BA_ "GenSigCycleTimeActive" SG_ 2147484962 LoadTruck_ISig_4 100;
BA_ "GenSigStartValue" SG_ 2147484962 LoadTruck_ISig_4 65535;
BA_ "GenSigCycleTime" SG_ 2147484962 LoadTrailer1_ISig_4 100;
BA_ "GenSigCycleTimeActive" SG_ 2147484962 LoadTrailer1_ISig_4 100;
BA_ "GenSigStartValue" SG_ 2147484962 LoadTrailer1_ISig_4 65535;
BA_ "GenSigCycleTime" SG_ 2147484962 LoadTrailer5Front 100;
BA_ "GenSigCycleTimeActive" SG_ 2147484962 LoadTrailer5Front 100;
BA_ "GenSigStartValue" SG_ 2147484962 LoadTrailer5Front 65535;
BA_ "GenSigCycleTime" SG_ 2147484961 LoadTrailer4_ISig_4 100;
BA_ "GenSigCycleTimeActive" SG_ 2147484961 LoadTrailer4_ISig_4 100;
BA_ "GenSigStartValue" SG_ 2147484961 LoadTrailer4_ISig_4 65535;
BA_ "GenSigCycleTime" SG_ 2147484961 LoadTrailer3Back 100;
BA_ "GenSigCycleTimeActive" SG_ 2147484961 LoadTrailer3Back 100;
BA_ "GenSigStartValue" SG_ 2147484961 LoadTrailer3Back 65535;
BA_ "GenSigCycleTime" SG_ 2147484961 LoadTruckRear 100;
BA_ "GenSigCycleTimeActive" SG_ 2147484961 LoadTruckRear 100;
BA_ "GenSigStartValue" SG_ 2147484961 LoadTruckRear 65535;
BA_ "GenSigCycleTime" SG_ 2147484961 LoadTrailer2_ISig_4 100;
BA_ "GenSigCycleTimeActive" SG_ 2147484961 LoadTrailer2_ISig_4 100;
BA_ "GenSigStartValue" SG_ 2147484961 LoadTrailer2_ISig_4 65535;
BA_ "GenSigCycleTime" SG_ 2147484960 CalLoadTrailer2Axle3_ISig_4 100;
BA_ "GenSigCycleTimeActive" SG_ 2147484960 CalLoadTrailer2Axle3_ISig_4 100;
BA_ "GenSigStartValue" SG_ 2147484960 CalLoadTrailer2Axle3_ISig_4 65535;
BA_ "GenSigCycleTime" SG_ 2147484960 CalLoadTrailer3Axle2_ISig_4 100;
BA_ "GenSigCycleTimeActive" SG_ 2147484960 CalLoadTrailer3Axle2_ISig_4 100;
BA_ "GenSigStartValue" SG_ 2147484960 CalLoadTrailer3Axle2_ISig_4 65535;
BA_ "GenSigCycleTime" SG_ 2147484960 CalLoadTrailer3Axle6_ISig_4 100;
BA_ "GenSigCycleTimeActive" SG_ 2147484960 CalLoadTrailer3Axle6_ISig_4 100;
BA_ "GenSigStartValue" SG_ 2147484960 CalLoadTrailer3Axle6_ISig_4 65535;
BA_ "GenSigCycleTime" SG_ 2147484953 LoadVehCombination 100;
BA_ "GenSigCycleTimeActive" SG_ 2147484953 LoadVehCombination 100;
BA_ "GenSigStartValue" SG_ 2147484953 LoadVehCombination 65535;
BA_ "GenSigCycleTime" SG_ 2147484953 LoadTruckFront 100;
BA_ "GenSigCycleTimeActive" SG_ 2147484953 LoadTruckFront 100;
BA_ "GenSigStartValue" SG_ 2147484953 LoadTruckFront 65535;
BA_ "GenSigCycleTime" SG_ 2147484953 LoadVehCombCargoRel 100;
BA_ "GenSigCycleTimeActive" SG_ 2147484953 LoadVehCombCargoRel 100;
BA_ "GenSigStartValue" SG_ 2147484953 LoadVehCombCargoRel 65535;
BA_ "GenSigCycleTime" SG_ 2147484953 LoadTrailer1Back 100;
BA_ "GenSigCycleTimeActive" SG_ 2147484953 LoadTrailer1Back 100;
BA_ "GenSigStartValue" SG_ 2147484953 LoadTrailer1Back 65535;
BA_ "GenSigCycleTime" SG_ 2147484952 CalLoadTrailer3Axle4_ISig_4 100;
BA_ "GenSigCycleTimeActive" SG_ 2147484952 CalLoadTrailer3Axle4_ISig_4 100;
BA_ "GenSigStartValue" SG_ 2147484952 CalLoadTrailer3Axle4_ISig_4 65535;
BA_ "GenSigCycleTime" SG_ 2147484952 CalLoadTrailer2Axle2_ISig_4 100;
BA_ "GenSigCycleTimeActive" SG_ 2147484952 CalLoadTrailer2Axle2_ISig_4 100;
BA_ "GenSigStartValue" SG_ 2147484952 CalLoadTrailer2Axle2_ISig_4 65535;
BA_ "GenSigCycleTime" SG_ 2147484952 CalLoadTrailer1Axle6_ISig_4 100;
BA_ "GenSigCycleTimeActive" SG_ 2147484952 CalLoadTrailer1Axle6_ISig_4 100;
BA_ "GenSigStartValue" SG_ 2147484952 CalLoadTrailer1Axle6_ISig_4 65535;
BA_ "GenSigCycleTime" SG_ 2147484952 CalLoadTrailer5Axle6_ISig_4 100;
BA_ "GenSigCycleTimeActive" SG_ 2147484952 CalLoadTrailer5Axle6_ISig_4 100;
BA_ "GenSigStartValue" SG_ 2147484952 CalLoadTrailer5Axle6_ISig_4 65535;
BA_ "GenSigCycleTime" SG_ 2147484951 CalLoadTrailer1Axle4_ISig_4 100;
BA_ "GenSigCycleTimeActive" SG_ 2147484951 CalLoadTrailer1Axle4_ISig_4 100;
BA_ "GenSigStartValue" SG_ 2147484951 CalLoadTrailer1Axle4_ISig_4 65535;
BA_ "GenSigCycleTime" SG_ 2147484951 CalLoadTrailer4Axle2_ISig_4 100;
BA_ "GenSigCycleTimeActive" SG_ 2147484951 CalLoadTrailer4Axle2_ISig_4 100;
BA_ "GenSigStartValue" SG_ 2147484951 CalLoadTrailer4Axle2_ISig_4 65535;
BA_ "GenSigCycleTime" SG_ 2147484951 CalLoadTrailer2Axle1_ISig_4 100;
BA_ "GenSigCycleTimeActive" SG_ 2147484951 CalLoadTrailer2Axle1_ISig_4 100;
BA_ "GenSigStartValue" SG_ 2147484951 CalLoadTrailer2Axle1_ISig_4 65535;
BA_ "GenSigCycleTime" SG_ 2147484951 CalLoadTrailer4Axle3_ISig_4 100;
BA_ "GenSigCycleTimeActive" SG_ 2147484951 CalLoadTrailer4Axle3_ISig_4 100;
BA_ "GenSigStartValue" SG_ 2147484951 CalLoadTrailer4Axle3_ISig_4 65535;
BA_ "GenSigCycleTime" SG_ 2147484950 CalLoadTruckRearAxle2_ISig_4 100;
BA_ "GenSigCycleTimeActive" SG_ 2147484950 CalLoadTruckRearAxle2_ISig_4 100;
BA_ "GenSigStartValue" SG_ 2147484950 CalLoadTruckRearAxle2_ISig_4 65535;
BA_ "GenSigCycleTime" SG_ 2147484950 CalLoadTruckRearAxle3_ISig_4 100;
BA_ "GenSigCycleTimeActive" SG_ 2147484950 CalLoadTruckRearAxle3_ISig_4 100;
BA_ "GenSigStartValue" SG_ 2147484950 CalLoadTruckRearAxle3_ISig_4 65535;
BA_ "GenSigCycleTime" SG_ 2147484950 CalLoadTrailer3Axle5_ISig_4 100;
BA_ "GenSigCycleTimeActive" SG_ 2147484950 CalLoadTrailer3Axle5_ISig_4 100;
BA_ "GenSigStartValue" SG_ 2147484950 CalLoadTrailer3Axle5_ISig_4 65535;
BA_ "GenSigCycleTime" SG_ 2147484950 CalLoadTrailer4Axle6_ISig_4 100;
BA_ "GenSigCycleTimeActive" SG_ 2147484950 CalLoadTrailer4Axle6_ISig_4 100;
BA_ "GenSigStartValue" SG_ 2147484950 CalLoadTrailer4Axle6_ISig_4 65535;
BA_ "GenSigCycleTime" SG_ 2147484949 CalLoadTrailer5Axle2_ISig_4 100;
BA_ "GenSigCycleTimeActive" SG_ 2147484949 CalLoadTrailer5Axle2_ISig_4 100;
BA_ "GenSigStartValue" SG_ 2147484949 CalLoadTrailer5Axle2_ISig_4 65535;
BA_ "GenSigCycleTime" SG_ 2147484949 CalLoadTrailer1Axle2_ISig_4 100;
BA_ "GenSigCycleTimeActive" SG_ 2147484949 CalLoadTrailer1Axle2_ISig_4 100;
BA_ "GenSigStartValue" SG_ 2147484949 CalLoadTrailer1Axle2_ISig_4 65535;
BA_ "GenSigCycleTime" SG_ 2147484949 CalLoadTrailer1Axle5_ISig_4 100;
BA_ "GenSigCycleTimeActive" SG_ 2147484949 CalLoadTrailer1Axle5_ISig_4 100;
BA_ "GenSigStartValue" SG_ 2147484949 CalLoadTrailer1Axle5_ISig_4 65535;
BA_ "GenSigCycleTime" SG_ 2147484949 CalLoadTrailer2Axle4_ISig_4 100;
BA_ "GenSigCycleTimeActive" SG_ 2147484949 CalLoadTrailer2Axle4_ISig_4 100;
BA_ "GenSigStartValue" SG_ 2147484949 CalLoadTrailer2Axle4_ISig_4 65535;
BA_ "GenSigCycleTime" SG_ 2147485064 WasherFluidLevel_ISig_4 100;
BA_ "GenSigCycleTimeActive" SG_ 2147485064 WasherFluidLevel_ISig_4 100;
BA_ "GenSigStartValue" SG_ 2147485064 WasherFluidLevel_ISig_4 7;
BA_ "GenSigMaxLatency" SG_ 2147485064 WasherFluidLevel_ISig_4 1110;
BA_ "Platform_VMCU1_Sig" SG_ 2147485064 WasherFluidLevel_ISig_4 1;
BA_ "SeToolAncestorID_SIGNAL" SG_ 2147485064 WasherFluidLevel_ISig_4 "x0000001D04104D03";
BA_ "SeToolItemID_SIGNAL" SG_ 2147485064 WasherFluidLevel_ISig_4 "x0000001D0435D527";
BA_ "SeToolName_SIGNAL" SG_ 2147485064 WasherFluidLevel_ISig_4 "WasherFluidLevel";
BA_ "SeToolVersion_SIGNAL" SG_ 2147485064 WasherFluidLevel_ISig_4 "3";
BA_ "GenSigSendType" SG_ 2147485064 FuelVolume_UB_ISig_4 7;
BA_ "Platform_VMCU1_Sig" SG_ 2147485064 FuelVolume_UB_ISig_4 1;
BA_ "GenSigSendType" SG_ 2147485064 ManTransmiOilTemp_UB_ISig_4 7;
BA_ "Platform_VMCU1_Sig" SG_ 2147485064 ManTransmiOilTemp_UB_ISig_4 1;
BA_ "GenSigCycleTime" SG_ 2147485064 FuelVolume_ISig_4 100;
BA_ "GenSigCycleTimeActive" SG_ 2147485064 FuelVolume_ISig_4 100;
BA_ "GenSigStartValue" SG_ 2147485064 FuelVolume_ISig_4 2047;
BA_ "NeedsUpdateBit" SG_ 2147485064 FuelVolume_ISig_4 1;
BA_ "Platform_VMCU1_Sig" SG_ 2147485064 FuelVolume_ISig_4 1;
BA_ "GenSigCycleTime" SG_ 2147485064 KFactor 100;
BA_ "GenSigCycleTimeActive" SG_ 2147485064 KFactor 100;
BA_ "GenSigStartValue" SG_ 2147485064 KFactor 65535;
BA_ "GenSigMaxLatency" SG_ 2147485064 KFactor 511;
BA_ "Platform_VMCU1_Sig" SG_ 2147485064 KFactor 1;
BA_ "SeToolAncestorID_SIGNAL" SG_ 2147485064 KFactor "x0000001D0416ED52";
BA_ "SeToolItemID_SIGNAL" SG_ 2147485064 KFactor "x0000001D041B55DB";
BA_ "SeToolName_SIGNAL" SG_ 2147485064 KFactor "K-Factor";
BA_ "SeToolVersion_SIGNAL" SG_ 2147485064 KFactor "2";
BA_ "GenSigCycleTime" SG_ 2147485064 ManTransmiOilTemp_ISig_4 100;
BA_ "GenSigCycleTimeActive" SG_ 2147485064 ManTransmiOilTemp_ISig_4 100;
BA_ "GenSigStartValue" SG_ 2147485064 ManTransmiOilTemp_ISig_4 65535;
BA_ "NeedsUpdateBit" SG_ 2147485064 ManTransmiOilTemp_ISig_4 1;
BA_ "Platform_VMCU1_Sig" SG_ 2147485064 ManTransmiOilTemp_ISig_4 1;
BA_ "GenSigCycleTime" SG_ 2147485064 EngSpeedGreenAreaMode_ISig_4 100;
BA_ "GenSigCycleTimeActive" SG_ 2147485064 EngSpeedGreenAreaMode_ISig_4 100;
BA_ "GenSigStartValue" SG_ 2147485064 EngSpeedGreenAreaMode_ISig_4 7;
BA_ "Platform_VMCU1_Sig" SG_ 2147485064 EngSpeedGreenAreaMode_ISig_4 1;
BA_ "GenSigCycleTime" SG_ 2147484698 CabRoofSignLightFeedback_stat 100;
BA_ "GenSigCycleTimeActive" SG_ 2147484698 CabRoofSignLightFeedback_stat 100;
BA_ "GenSigStartValue" SG_ 2147484698 CabRoofSignLightFeedback_stat 3;
BA_ "Platform_VMCU1_Sig" SG_ 2147484698 CabRoofSignLightFeedback_stat 1;
BA_ "SeToolAncestorID_SIGNAL" SG_ 2147484698 CabRoofSignLightFeedback_stat "x0000001D041B0A30";
BA_ "SeToolItemID_SIGNAL" SG_ 2147484698 CabRoofSignLightFeedback_stat "x0000001D041B0A30";
BA_ "SeToolName_SIGNAL" SG_ 2147484698 CabRoofSignLightFeedback_stat "CabRoofSignLightFeedback_Status";
BA_ "SeToolVersion_SIGNAL" SG_ 2147484698 CabRoofSignLightFeedback_stat "1";
BA_ "GenSigCycleTime" SG_ 2147484698 TemporaryRSLStatus 100;
BA_ "GenSigCycleTimeActive" SG_ 2147484698 TemporaryRSLStatus 100;
BA_ "GenSigStartValue" SG_ 2147484698 TemporaryRSLStatus 3;
BA_ "Platform_VMCU1_Sig" SG_ 2147484698 TemporaryRSLStatus 1;
BA_ "GenSigCycleTime" SG_ 2147484698 CabExtraSideWrknLightFdbk_stat_I 100;
BA_ "GenSigCycleTimeActive" SG_ 2147484698 CabExtraSideWrknLightFdbk_stat_I 100;
BA_ "GenSigStartValue" SG_ 2147484698 CabExtraSideWrknLightFdbk_stat_I 3;
BA_ "GenSigMaxLatency" SG_ 2147484698 CabExtraSideWrknLightFdbk_stat_I 112;
BA_ "Platform_VMCU1_Sig" SG_ 2147484698 CabExtraSideWrknLightFdbk_stat_I 1;
BA_ "SeToolAncestorID_SIGNAL" SG_ 2147484698 CabExtraSideWrknLightFdbk_stat_I "x0000001D041B0A4B";
BA_ "SeToolItemID_SIGNAL" SG_ 2147484698 CabExtraSideWrknLightFdbk_stat_I "x0000001D041B0A4B";
BA_ "SeToolName_SIGNAL" SG_ 2147484698 CabExtraSideWrknLightFdbk_stat_I "CabExtraSideWorkingFeedback_Status";
BA_ "SeToolVersion_SIGNAL" SG_ 2147484698 CabExtraSideWrknLightFdbk_stat_I "1";
BA_ "SystemSignalLongSymbol" SG_ 2147484698 CabExtraSideWrknLightFdbk_stat_I "CabExtraSideWrknLightFdbk_stat_ISig_4";
BA_ "GenSigCycleTime" SG_ 2147484698 CabWrknLightChassisFdbk_stat_ISi 100;
BA_ "GenSigCycleTimeActive" SG_ 2147484698 CabWrknLightChassisFdbk_stat_ISi 100;
BA_ "GenSigStartValue" SG_ 2147484698 CabWrknLightChassisFdbk_stat_ISi 3;
BA_ "GenSigMaxLatency" SG_ 2147484698 CabWrknLightChassisFdbk_stat_ISi 112;
BA_ "Platform_VMCU1_Sig" SG_ 2147484698 CabWrknLightChassisFdbk_stat_ISi 1;
BA_ "SeToolAncestorID_SIGNAL" SG_ 2147484698 CabWrknLightChassisFdbk_stat_ISi "x0000001D041B0A49";
BA_ "SeToolItemID_SIGNAL" SG_ 2147484698 CabWrknLightChassisFdbk_stat_ISi "x0000001D041B0A49";
BA_ "SeToolName_SIGNAL" SG_ 2147484698 CabWrknLightChassisFdbk_stat_ISi "CabWorkingLightChassisFeedback_Status";
BA_ "SeToolVersion_SIGNAL" SG_ 2147484698 CabWrknLightChassisFdbk_stat_ISi "1";
BA_ "SystemSignalLongSymbol" SG_ 2147484698 CabWrknLightChassisFdbk_stat_ISi "CabWrknLightChassisFdbk_stat_ISig_4";
BA_ "GenSigCycleTime" SG_ 2147484698 CabTrailerBodyLgthnFdbk_stat 100;
BA_ "GenSigCycleTimeActive" SG_ 2147484698 CabTrailerBodyLgthnFdbk_stat 100;
BA_ "GenSigStartValue" SG_ 2147484698 CabTrailerBodyLgthnFdbk_stat 3;
BA_ "GenSigMaxLatency" SG_ 2147484698 CabTrailerBodyLgthnFdbk_stat 112;
BA_ "Platform_VMCU1_Sig" SG_ 2147484698 CabTrailerBodyLgthnFdbk_stat 1;
BA_ "SeToolAncestorID_SIGNAL" SG_ 2147484698 CabTrailerBodyLgthnFdbk_stat "x0000001D04206B2D";
BA_ "SeToolItemID_SIGNAL" SG_ 2147484698 CabTrailerBodyLgthnFdbk_stat "x0000001D04206B2D";
BA_ "SeToolName_SIGNAL" SG_ 2147484698 CabTrailerBodyLgthnFdbk_stat "CabTrailerBodyLightingFeedback_Status";
BA_ "SeToolVersion_SIGNAL" SG_ 2147484698 CabTrailerBodyLgthnFdbk_stat "1";
BA_ "GenSigCycleTime" SG_ 2147484698 DiffLockInterWhlStatusSplitBox_I 100;
BA_ "GenSigCycleTimeActive" SG_ 2147484698 DiffLockInterWhlStatusSplitBox_I 100;
BA_ "GenSigStartValue" SG_ 2147484698 DiffLockInterWhlStatusSplitBox_I 3;
BA_ "Platform_VMCU1_Sig" SG_ 2147484698 DiffLockInterWhlStatusSplitBox_I 1;
BA_ "SystemSignalLongSymbol" SG_ 2147484698 DiffLockInterWhlStatusSplitBox_I "DiffLockInterWhlStatusSplitBox_ISig_4";
BA_ "GenSigCycleTime" SG_ 2147484698 BodyOrCabWorkingLightFdbk_stat_I 100;
BA_ "GenSigCycleTimeActive" SG_ 2147484698 BodyOrCabWorkingLightFdbk_stat_I 100;
BA_ "GenSigStartValue" SG_ 2147484698 BodyOrCabWorkingLightFdbk_stat_I 3;
BA_ "GenSigMaxLatency" SG_ 2147484698 BodyOrCabWorkingLightFdbk_stat_I 112;
BA_ "Platform_VMCU1_Sig" SG_ 2147484698 BodyOrCabWorkingLightFdbk_stat_I 1;
BA_ "SeToolAncestorID_SIGNAL" SG_ 2147484698 BodyOrCabWorkingLightFdbk_stat_I "x0000001D041B0A46";
BA_ "SeToolItemID_SIGNAL" SG_ 2147484698 BodyOrCabWorkingLightFdbk_stat_I "x0000001D041B0A46";
BA_ "SeToolName_SIGNAL" SG_ 2147484698 BodyOrCabWorkingLightFdbk_stat_I "CabBody/CabWorkingLightFeedback_Status";
BA_ "SeToolVersion_SIGNAL" SG_ 2147484698 BodyOrCabWorkingLightFdbk_stat_I "1";
BA_ "SystemSignalLongSymbol" SG_ 2147484698 BodyOrCabWorkingLightFdbk_stat_I "BodyOrCabWorkingLightFdbk_stat_ISig_4";
BA_ "GenSigCycleTime" SG_ 2147484698 WheelBasedVehicleSpeedLowRes_ISi 100;
BA_ "GenSigCycleTimeActive" SG_ 2147484698 WheelBasedVehicleSpeedLowRes_ISi 100;
BA_ "GenSigStartValue" SG_ 2147484698 WheelBasedVehicleSpeedLowRes_ISi 255;
BA_ "GenSigMaxLatency" SG_ 2147484698 WheelBasedVehicleSpeedLowRes_ISi 112;
BA_ "Platform_VMCU1_Sig" SG_ 2147484698 WheelBasedVehicleSpeedLowRes_ISi 1;
BA_ "SeToolAncestorID_SIGNAL" SG_ 2147484698 WheelBasedVehicleSpeedLowRes_ISi "x0000001D041F9CE4";
BA_ "SeToolItemID_SIGNAL" SG_ 2147484698 WheelBasedVehicleSpeedLowRes_ISi "x0000001D041F9CE4";
BA_ "SeToolName_SIGNAL" SG_ 2147484698 WheelBasedVehicleSpeedLowRes_ISi "Wheel-BasedVehicleSpeedLowRes";
BA_ "SeToolVersion_SIGNAL" SG_ 2147484698 WheelBasedVehicleSpeedLowRes_ISi "1";
BA_ "SystemSignalLongSymbol" SG_ 2147484698 WheelBasedVehicleSpeedLowRes_ISi "WheelBasedVehicleSpeedLowRes_ISig_4";
BA_ "GenSigCycleTime" SG_ 2147484698 AirDryerCoolingFanSpeed_rqst 100;
BA_ "GenSigCycleTimeActive" SG_ 2147484698 AirDryerCoolingFanSpeed_rqst 100;
BA_ "GenSigStartValue" SG_ 2147484698 AirDryerCoolingFanSpeed_rqst 65535;
BA_ "GenSigMaxLatency" SG_ 2147484698 AirDryerCoolingFanSpeed_rqst 112;
BA_ "NeedsUpdateBit" SG_ 2147484698 AirDryerCoolingFanSpeed_rqst 1;
BA_ "Platform_VMCU1_Sig" SG_ 2147484698 AirDryerCoolingFanSpeed_rqst 1;
BA_ "SeToolAncestorID_SIGNAL" SG_ 2147484698 AirDryerCoolingFanSpeed_rqst "x0000001D0425B656";
BA_ "SeToolItemID_SIGNAL" SG_ 2147484698 AirDryerCoolingFanSpeed_rqst "x0000001D043C814A";
BA_ "SeToolName_SIGNAL" SG_ 2147484698 AirDryerCoolingFanSpeed_rqst "AirDryerCoolingFanSpeed_rqst";
BA_ "SeToolVersion_SIGNAL" SG_ 2147484698 AirDryerCoolingFanSpeed_rqst "2";
BA_ "GenSigCycleTime" SG_ 2147484698 CabFrontSpotFeedback_Status 100;
BA_ "GenSigCycleTimeActive" SG_ 2147484698 CabFrontSpotFeedback_Status 100;
BA_ "GenSigStartValue" SG_ 2147484698 CabFrontSpotFeedback_Status 3;
BA_ "GenSigMaxLatency" SG_ 2147484698 CabFrontSpotFeedback_Status 112;
BA_ "Platform_VMCU1_Sig" SG_ 2147484698 CabFrontSpotFeedback_Status 1;
BA_ "SeToolAncestorID_SIGNAL" SG_ 2147484698 CabFrontSpotFeedback_Status "x0000001D041B0A34";
BA_ "SeToolItemID_SIGNAL" SG_ 2147484698 CabFrontSpotFeedback_Status "x0000001D041B0A34";
BA_ "SeToolName_SIGNAL" SG_ 2147484698 CabFrontSpotFeedback_Status "CabFrontSpotFeedback_Status";
BA_ "SeToolVersion_SIGNAL" SG_ 2147484698 CabFrontSpotFeedback_Status "1";
BA_ "GenSigCycleTime" SG_ 2147484698 CabTiltEnableStatus 100;
BA_ "GenSigCycleTimeActive" SG_ 2147484698 CabTiltEnableStatus 100;
BA_ "GenSigStartValue" SG_ 2147484698 CabTiltEnableStatus 3;
BA_ "GenSigMaxLatency" SG_ 2147484698 CabTiltEnableStatus 112;
BA_ "Platform_VMCU1_Sig" SG_ 2147484698 CabTiltEnableStatus 1;
BA_ "SeToolAncestorID_SIGNAL" SG_ 2147484698 CabTiltEnableStatus "x0000001D04173E71";
BA_ "SeToolItemID_SIGNAL" SG_ 2147484698 CabTiltEnableStatus "x0000001D0419EA6D";
BA_ "SeToolName_SIGNAL" SG_ 2147484698 CabTiltEnableStatus "CabTiltEnableStatus";
BA_ "SeToolVersion_SIGNAL" SG_ 2147484698 CabTiltEnableStatus "2";
BA_ "GenSigCycleTime" SG_ 2147484698 TransmReverseDirectionSw_stat_IS 100;
BA_ "GenSigCycleTimeActive" SG_ 2147484698 TransmReverseDirectionSw_stat_IS 100;
BA_ "GenSigStartValue" SG_ 2147484698 TransmReverseDirectionSw_stat_IS 3;
BA_ "Platform_VMCU1_Sig" SG_ 2147484698 TransmReverseDirectionSw_stat_IS 1;
BA_ "SystemSignalLongSymbol" SG_ 2147484698 TransmReverseDirectionSw_stat_IS "TransmReverseDirectionSw_stat_ISig_4";
BA_ "GenSigCycleTime" SG_ 2147484698 CabRoofSpotFeedback_Status 100;
BA_ "GenSigCycleTimeActive" SG_ 2147484698 CabRoofSpotFeedback_Status 100;
BA_ "GenSigStartValue" SG_ 2147484698 CabRoofSpotFeedback_Status 3;
BA_ "GenSigMaxLatency" SG_ 2147484698 CabRoofSpotFeedback_Status 112;
BA_ "Platform_VMCU1_Sig" SG_ 2147484698 CabRoofSpotFeedback_Status 1;
BA_ "SeToolAncestorID_SIGNAL" SG_ 2147484698 CabRoofSpotFeedback_Status "x0000001D041B0A36";
BA_ "SeToolItemID_SIGNAL" SG_ 2147484698 CabRoofSpotFeedback_Status "x0000001D041B0A36";
BA_ "SeToolName_SIGNAL" SG_ 2147484698 CabRoofSpotFeedback_Status "CabRoofSpotFeedback_Status";
BA_ "SeToolVersion_SIGNAL" SG_ 2147484698 CabRoofSpotFeedback_Status "1";
BA_ "GenSigCycleTime" SG_ 2147484698 CabBeaconLightFeedback_Status_IS 100;
BA_ "GenSigCycleTimeActive" SG_ 2147484698 CabBeaconLightFeedback_Status_IS 100;
BA_ "GenSigStartValue" SG_ 2147484698 CabBeaconLightFeedback_Status_IS 3;
BA_ "GenSigMaxLatency" SG_ 2147484698 CabBeaconLightFeedback_Status_IS 112;
BA_ "Platform_VMCU1_Sig" SG_ 2147484698 CabBeaconLightFeedback_Status_IS 1;
BA_ "SeToolAncestorID_SIGNAL" SG_ 2147484698 CabBeaconLightFeedback_Status_IS "x0000001D041B0A09";
BA_ "SeToolItemID_SIGNAL" SG_ 2147484698 CabBeaconLightFeedback_Status_IS "x0000001D041B0A09";
BA_ "SeToolName_SIGNAL" SG_ 2147484698 CabBeaconLightFeedback_Status_IS "CabBeaconLightFeedback_Status";
BA_ "SeToolVersion_SIGNAL" SG_ 2147484698 CabBeaconLightFeedback_Status_IS "1";
BA_ "SystemSignalLongSymbol" SG_ 2147484698 CabBeaconLightFeedback_Status_IS "CabBeaconLightFeedback_Status_ISig_4";
BA_ "GenSigCycleTime" SG_ 2147484698 ExtraAxleSteeringFunctionStat_IS 100;
BA_ "GenSigCycleTimeActive" SG_ 2147484698 ExtraAxleSteeringFunctionStat_IS 100;
BA_ "GenSigStartValue" SG_ 2147484698 ExtraAxleSteeringFunctionStat_IS 7;
BA_ "Platform_VMCU1_Sig" SG_ 2147484698 ExtraAxleSteeringFunctionStat_IS 1;
BA_ "SystemSignalLongSymbol" SG_ 2147484698 ExtraAxleSteeringFunctionStat_IS "ExtraAxleSteeringFunctionStat_ISig_4";
BA_ "GenSigSendType" SG_ 2147484698 AirDryerCoolingFanSpeed_rqst_UB 7;
BA_ "GenSigCycleTime" SG_ 2147484698 AirDryerCoolingFanSpeed_rqst_UB 100;
BA_ "GenSigCycleTimeActive" SG_ 2147484698 AirDryerCoolingFanSpeed_rqst_UB 100;
BA_ "Platform_VMCU1_Sig" SG_ 2147484698 AirDryerCoolingFanSpeed_rqst_UB 1;
BA_ "GenSigCycleTime" SG_ 2147484698 CabTiltLockStatus_ISig_4 100;
BA_ "GenSigCycleTimeActive" SG_ 2147484698 CabTiltLockStatus_ISig_4 100;
BA_ "GenSigStartValue" SG_ 2147484698 CabTiltLockStatus_ISig_4 3;
BA_ "GenSigMaxLatency" SG_ 2147484698 CabTiltLockStatus_ISig_4 112;
BA_ "Platform_VMCU1_Sig" SG_ 2147484698 CabTiltLockStatus_ISig_4 1;
BA_ "SeToolAncestorID_SIGNAL" SG_ 2147484698 CabTiltLockStatus_ISig_4 "x0000001D04173E82";
BA_ "SeToolItemID_SIGNAL" SG_ 2147484698 CabTiltLockStatus_ISig_4 "x0000001D041D94E8";
BA_ "SeToolName_SIGNAL" SG_ 2147484698 CabTiltLockStatus_ISig_4 "CabTiltLockStatus";
BA_ "SeToolVersion_SIGNAL" SG_ 2147484698 CabTiltLockStatus_ISig_4 "2";
BA_ "GenSigCycleTime" SG_ 2147484698 PositionLightRearLamp_stat_ISig_ 100;
BA_ "GenSigCycleTimeActive" SG_ 2147484698 PositionLightRearLamp_stat_ISig_ 100;
BA_ "GenSigStartValue" SG_ 2147484698 PositionLightRearLamp_stat_ISig_ 7;
BA_ "Platform_VMCU1_Sig" SG_ 2147484698 PositionLightRearLamp_stat_ISig_ 1;
BA_ "SystemSignalLongSymbol" SG_ 2147484698 PositionLightRearLamp_stat_ISig_ "PositionLightRearLamp_stat_ISig_4";
BA_REL_ "GenSigFirstTimeoutTime" BU_SG_REL_ BBM SG_ 2147484474 StartupProhibitStatus_ISig_4 3000;
BA_REL_ "GenSigTimeoutTime" BU_SG_REL_ BBM SG_ 2147484474 StartupProhibitStatus_ISig_4 300;
BA_REL_ "GenSigFirstTimeoutTime" BU_SG_REL_ IC3 SG_ 2147484474 StartupProhibitStatus_ISig_4 3000;
BA_REL_ "GenSigTimeoutTime" BU_SG_REL_ IC3 SG_ 2147484474 StartupProhibitStatus_ISig_4 300;
BA_REL_ "GenSigFirstTimeoutTime" BU_SG_REL_ IC3 SG_ 2147484474 RampLevelStatus_ISig_4 3000;
BA_REL_ "GenSigTimeoutTime" BU_SG_REL_ IC3 SG_ 2147484474 RampLevelStatus_ISig_4 300;
BA_REL_ "GenSigFirstTimeoutTime" BU_SG_REL_ CIOM SG_ 2147484474 RampLevelStatus_ISig_4 3000;
BA_REL_ "GenSigTimeoutTime" BU_SG_REL_ CIOM SG_ 2147484474 RampLevelStatus_ISig_4 300;
BA_REL_ "GenSigFirstTimeoutTime" BU_SG_REL_ BBM SG_ 2147484474 KneelingInformation_ISig_4 3000;
BA_REL_ "GenSigTimeoutTime" BU_SG_REL_ BBM SG_ 2147484474 KneelingInformation_ISig_4 300;
BA_REL_ "GenSigFirstTimeoutTime" BU_SG_REL_ IC3 SG_ 2147484474 KneelingInformation_ISig_4 3000;
BA_REL_ "GenSigTimeoutTime" BU_SG_REL_ IC3 SG_ 2147484474 KneelingInformation_ISig_4 300;
BA_REL_ "GenSigFirstTimeoutTime" BU_SG_REL_ CIOM SG_ 2147484474 KneelingInformation_ISig_4 3000;
BA_REL_ "GenSigTimeoutTime" BU_SG_REL_ CIOM SG_ 2147484474 KneelingInformation_ISig_4 300;
BA_REL_ "GenSigFirstTimeoutTime" BU_SG_REL_ TECU SG_ 2147484474 FrontAxleInBumperRange_ISig_4 3000;
BA_REL_ "GenSigTimeoutTime" BU_SG_REL_ TECU SG_ 2147484474 FrontAxleInBumperRange_ISig_4 500;
BA_REL_ "GenSigFirstTimeoutTime" BU_SG_REL_ IC3 SG_ 2147484474 FerryFunctionStatus_ISig_4 3000;
BA_REL_ "GenSigTimeoutTime" BU_SG_REL_ IC3 SG_ 2147484474 FerryFunctionStatus_ISig_4 300;
BA_REL_ "GenSigFirstTimeoutTime" BU_SG_REL_ CIOM SG_ 2147484474 FerryFunctionStatus_ISig_4 3000;
BA_REL_ "GenSigTimeoutTime" BU_SG_REL_ CIOM SG_ 2147484474 FerryFunctionStatus_ISig_4 300;
BA_REL_ "GenSigFirstTimeoutTime" BU_SG_REL_ TECU SG_ 2147484474 EngPtoConsumesTorque 3000;
BA_REL_ "GenSigTimeoutTime" BU_SG_REL_ TECU SG_ 2147484474 EngPtoConsumesTorque 500;
BA_REL_ "GenSigFirstTimeoutTime" BU_SG_REL_ BBM SG_ 2147484474 LiftingControlModeRearAxle_ISig_ 3000;
BA_REL_ "GenSigTimeoutTime" BU_SG_REL_ BBM SG_ 2147484474 LiftingControlModeRearAxle_ISig_ 300;
BA_REL_ "GenSigFirstTimeoutTime" BU_SG_REL_ BBM SG_ 2147484474 KneelingStatusHMI_ISig_4 3000;
BA_REL_ "GenSigTimeoutTime" BU_SG_REL_ BBM SG_ 2147484474 KneelingStatusHMI_ISig_4 300;
BA_REL_ "GenSigFirstTimeoutTime" BU_SG_REL_ CIOM SG_ 2147484474 KneelingStatusHMI_ISig_4 3000;
BA_REL_ "GenSigTimeoutTime" BU_SG_REL_ CIOM SG_ 2147484474 KneelingStatusHMI_ISig_4 300;
BA_REL_ "GenSigFirstTimeoutTime" BU_SG_REL_ BBM SG_ 2147484474 SWEngineStop_rqst_ISig_4 3000;
BA_REL_ "GenSigTimeoutTime" BU_SG_REL_ BBM SG_ 2147484474 SWEngineStop_rqst_ISig_4 300;
BA_REL_ "GenSigFirstTimeoutTime" BU_SG_REL_ CIOM SG_ 2147484474 FrontEndPositionStatus_ISig_4 3000;
BA_REL_ "GenSigTimeoutTime" BU_SG_REL_ CIOM SG_ 2147484474 FrontEndPositionStatus_ISig_4 300;
BA_REL_ "GenSigFirstTimeoutTime" BU_SG_REL_ BBM SG_ 2147484474 LiftingControlModeFrontAxle_ISig 3000;
BA_REL_ "GenSigTimeoutTime" BU_SG_REL_ BBM SG_ 2147484474 LiftingControlModeFrontAxle_ISig 300;
BA_REL_ "GenSigFirstTimeoutTime" BU_SG_REL_ IC3 SG_ 2147484474 UnevenLoadWarning_ISig_4 3000;
BA_REL_ "GenSigTimeoutTime" BU_SG_REL_ IC3 SG_ 2147484474 UnevenLoadWarning_ISig_4 300;
BA_REL_ "GenSigFirstTimeoutTime" BU_SG_REL_ IC3 SG_ 2147484474 RampHeightOutsideTargetRange_ISi 3000;
BA_REL_ "GenSigTimeoutTime" BU_SG_REL_ IC3 SG_ 2147484474 RampHeightOutsideTargetRange_ISi 300;
BA_REL_ "GenSigFirstTimeoutTime" BU_SG_REL_ CIOM SG_ 2147484474 RampHeightOutsideTargetRange_ISi 3000;
BA_REL_ "GenSigTimeoutTime" BU_SG_REL_ CIOM SG_ 2147484474 RampHeightOutsideTargetRange_ISi 300;
BA_REL_ "GenSigFirstTimeoutTime" BU_SG_REL_ IC3 SG_ 2147484474 DriveLevelPosUserInteraction_ISi 3000;
BA_REL_ "GenSigTimeoutTime" BU_SG_REL_ IC3 SG_ 2147484474 DriveLevelPosUserInteraction_ISi 300;
BA_REL_ "GenSigFirstTimeoutTime" BU_SG_REL_ TECU SG_ 2147484474 RearEndPositionStatus_ISig_4 3000;
BA_REL_ "GenSigTimeoutTime" BU_SG_REL_ TECU SG_ 2147484474 RearEndPositionStatus_ISig_4 500;
BA_REL_ "GenSigFirstTimeoutTime" BU_SG_REL_ CIOM SG_ 2147484474 RearEndPositionStatus_ISig_4 3000;
BA_REL_ "GenSigTimeoutTime" BU_SG_REL_ CIOM SG_ 2147484474 RearEndPositionStatus_ISig_4 300;
BA_REL_ "GenSigFirstTimeoutTime" BU_SG_REL_ IC3 SG_ 2147484474 ProhibitControlStatus_ISig_4 3000;
BA_REL_ "GenSigTimeoutTime" BU_SG_REL_ IC3 SG_ 2147484474 ProhibitControlStatus_ISig_4 300;
BA_REL_ "GenSigFirstTimeoutTime" BU_SG_REL_ BBM SG_ 2147484474 ProhibitControlStatus_ISig_4 3000;
BA_REL_ "GenSigTimeoutTime" BU_SG_REL_ BBM SG_ 2147484474 ProhibitControlStatus_ISig_4 300;
BA_REL_ "GenSigFirstTimeoutTime" BU_SG_REL_ CIOM SG_ 2147484474 ChangeKneelACK_ISig_4 3000;
BA_REL_ "GenSigTimeoutTime" BU_SG_REL_ CIOM SG_ 2147484474 ChangeKneelACK_ISig_4 300;
BA_REL_ "GenSigFirstTimeoutTime" BU_SG_REL_ IC3 SG_ 2147484474 ParkBrakeApplicationMode2 3000;
BA_REL_ "GenSigTimeoutTime" BU_SG_REL_ IC3 SG_ 2147484474 ParkBrakeApplicationMode2 300;
BA_REL_ "GenSigFirstTimeoutTime" BU_SG_REL_ CIOM SG_ 2147484474 RollEndPositionStatus_ISig_4 3000;
BA_REL_ "GenSigTimeoutTime" BU_SG_REL_ CIOM SG_ 2147484474 RollEndPositionStatus_ISig_4 300;
BA_REL_ "GenSigFirstTimeoutTime" BU_SG_REL_ IC3 SG_ 2147484474 ParkBrakeReleaseMode2_ISig_4 3000;
BA_REL_ "GenSigTimeoutTime" BU_SG_REL_ IC3 SG_ 2147484474 ParkBrakeReleaseMode2_ISig_4 300;
BA_REL_ "GenSigFirstTimeoutTime" BU_SG_REL_ CIOM SG_ 2147484474 ECSStandbyAllowed_ISig_4 3000;
BA_REL_ "GenSigTimeoutTime" BU_SG_REL_ CIOM SG_ 2147484474 ECSStandbyAllowed_ISig_4 300;
BA_REL_ "GenSigFirstTimeoutTime" BU_SG_REL_ TECU SG_ 2147484474 RearAxleInBumperRange_ISig_4 3000;
BA_REL_ "GenSigTimeoutTime" BU_SG_REL_ TECU SG_ 2147484474 RearAxleInBumperRange_ISig_4 500;
BA_REL_ "GenSigFirstTimeoutTime" BU_SG_REL_ BBM SG_ 2147484677 RelativeLevelRearAxleRight_ISig_ 3000;
BA_REL_ "GenSigTimeoutTime" BU_SG_REL_ BBM SG_ 2147484677 RelativeLevelRearAxleRight_ISig_ 600;
BA_REL_ "GenSigFirstTimeoutTime" BU_SG_REL_ BBM SG_ 2147484677 RelativeLevelFrontAxleRight_ISig 3000;
BA_REL_ "GenSigTimeoutTime" BU_SG_REL_ BBM SG_ 2147484677 RelativeLevelFrontAxleRight_ISig 600;
BA_REL_ "GenSigFirstTimeoutTime" BU_SG_REL_ BBM SG_ 2147484677 RelativeLevelFrontAxleLeft_ISig_ 3000;
BA_REL_ "GenSigTimeoutTime" BU_SG_REL_ BBM SG_ 2147484677 RelativeLevelFrontAxleLeft_ISig_ 600;
BA_REL_ "GenSigFirstTimeoutTime" BU_SG_REL_ BBM SG_ 2147484677 RelativeLevelRearAxleLeft_ISig_4 3000;
BA_REL_ "GenSigTimeoutTime" BU_SG_REL_ BBM SG_ 2147484677 RelativeLevelRearAxleLeft_ISig_4 600;
BA_REL_ "GenSigFirstTimeoutTime" BU_SG_REL_ IC3 SG_ 2147485244 SavedUnit20_TrailerName 60000;
BA_REL_ "GenSigTimeoutTime" BU_SG_REL_ IC3 SG_ 2147485244 SavedUnit20_TrailerName 60000;
BA_REL_ "GenSigFirstTimeoutTime" BU_SG_REL_ IC3 SG_ 2147485244 SavedUnit20_TrailerPosition 60000;
BA_REL_ "GenSigTimeoutTime" BU_SG_REL_ IC3 SG_ 2147485244 SavedUnit20_TrailerPosition 60000;
BA_REL_ "GenSigFirstTimeoutTime" BU_SG_REL_ IC3 SG_ 2147485242 SavedUnit19_TrailerName 60000;
BA_REL_ "GenSigTimeoutTime" BU_SG_REL_ IC3 SG_ 2147485242 SavedUnit19_TrailerName 60000;
BA_REL_ "GenSigFirstTimeoutTime" BU_SG_REL_ IC3 SG_ 2147485242 SavedUnit19_TrailerPosition 60000;
BA_REL_ "GenSigTimeoutTime" BU_SG_REL_ IC3 SG_ 2147485242 SavedUnit19_TrailerPosition 60000;
BA_REL_ "GenSigFirstTimeoutTime" BU_SG_REL_ IC3 SG_ 2147485240 SavedUnit18_TrailerPosition 60000;
BA_REL_ "GenSigTimeoutTime" BU_SG_REL_ IC3 SG_ 2147485240 SavedUnit18_TrailerPosition 60000;
BA_REL_ "GenSigFirstTimeoutTime" BU_SG_REL_ IC3 SG_ 2147485240 SavedUnit18_TrailerName 60000;
BA_REL_ "GenSigTimeoutTime" BU_SG_REL_ IC3 SG_ 2147485240 SavedUnit18_TrailerName 60000;
BA_REL_ "GenSigFirstTimeoutTime" BU_SG_REL_ IC3 SG_ 2147485238 SavedUnit17_TrailerPosition 60000;
BA_REL_ "GenSigTimeoutTime" BU_SG_REL_ IC3 SG_ 2147485238 SavedUnit17_TrailerPosition 60000;
BA_REL_ "GenSigFirstTimeoutTime" BU_SG_REL_ IC3 SG_ 2147485238 SavedUnit17_TrailerName 60000;
BA_REL_ "GenSigTimeoutTime" BU_SG_REL_ IC3 SG_ 2147485238 SavedUnit17_TrailerName 60000;
BA_REL_ "GenSigFirstTimeoutTime" BU_SG_REL_ IC3 SG_ 2147485236 SavedUnit16_TrailerName 60000;
BA_REL_ "GenSigTimeoutTime" BU_SG_REL_ IC3 SG_ 2147485236 SavedUnit16_TrailerName 60000;
BA_REL_ "GenSigFirstTimeoutTime" BU_SG_REL_ IC3 SG_ 2147485236 SavedUnit16_TrailerPosition 60000;
BA_REL_ "GenSigTimeoutTime" BU_SG_REL_ IC3 SG_ 2147485236 SavedUnit16_TrailerPosition 60000;
BA_REL_ "GenSigFirstTimeoutTime" BU_SG_REL_ IC3 SG_ 2147485234 SavedUnit15_TrailerName 60000;
BA_REL_ "GenSigTimeoutTime" BU_SG_REL_ IC3 SG_ 2147485234 SavedUnit15_TrailerName 60000;
BA_REL_ "GenSigFirstTimeoutTime" BU_SG_REL_ IC3 SG_ 2147485234 SavedUnit15_TrailerPosition 60000;
BA_REL_ "GenSigTimeoutTime" BU_SG_REL_ IC3 SG_ 2147485234 SavedUnit15_TrailerPosition 60000;
BA_REL_ "GenSigFirstTimeoutTime" BU_SG_REL_ IC3 SG_ 2147485232 SavedUnit14_TrailerPosition 60000;
BA_REL_ "GenSigTimeoutTime" BU_SG_REL_ IC3 SG_ 2147485232 SavedUnit14_TrailerPosition 60000;
BA_REL_ "GenSigFirstTimeoutTime" BU_SG_REL_ IC3 SG_ 2147485232 SavedUnit14_TrailerName 60000;
BA_REL_ "GenSigTimeoutTime" BU_SG_REL_ IC3 SG_ 2147485232 SavedUnit14_TrailerName 60000;
BA_REL_ "GenSigFirstTimeoutTime" BU_SG_REL_ IC3 SG_ 2147485224 SavedUnit13_TrailerPosition 60000;
BA_REL_ "GenSigTimeoutTime" BU_SG_REL_ IC3 SG_ 2147485224 SavedUnit13_TrailerPosition 60000;
BA_REL_ "GenSigFirstTimeoutTime" BU_SG_REL_ IC3 SG_ 2147485224 SavedUnit13_TrailerName 60000;
BA_REL_ "GenSigTimeoutTime" BU_SG_REL_ IC3 SG_ 2147485224 SavedUnit13_TrailerName 60000;
BA_REL_ "GenSigFirstTimeoutTime" BU_SG_REL_ IC3 SG_ 2147485222 SavedUnit12_TrailerName 60000;
BA_REL_ "GenSigTimeoutTime" BU_SG_REL_ IC3 SG_ 2147485222 SavedUnit12_TrailerName 60000;
BA_REL_ "GenSigFirstTimeoutTime" BU_SG_REL_ IC3 SG_ 2147485222 SavedUnit12_TrailerPosition 60000;
BA_REL_ "GenSigTimeoutTime" BU_SG_REL_ IC3 SG_ 2147485222 SavedUnit12_TrailerPosition 60000;
BA_REL_ "GenSigFirstTimeoutTime" BU_SG_REL_ IC3 SG_ 2147485220 SavedUnit11_TrailerPosition 60000;
BA_REL_ "GenSigTimeoutTime" BU_SG_REL_ IC3 SG_ 2147485220 SavedUnit11_TrailerPosition 60000;
BA_REL_ "GenSigFirstTimeoutTime" BU_SG_REL_ IC3 SG_ 2147485220 SavedUnit11_TrailerName 60000;
BA_REL_ "GenSigTimeoutTime" BU_SG_REL_ IC3 SG_ 2147485220 SavedUnit11_TrailerName 60000;
BA_REL_ "GenSigFirstTimeoutTime" BU_SG_REL_ IC3 SG_ 2147485218 SavedUnit10_TrailerName 60000;
BA_REL_ "GenSigTimeoutTime" BU_SG_REL_ IC3 SG_ 2147485218 SavedUnit10_TrailerName 60000;
BA_REL_ "GenSigFirstTimeoutTime" BU_SG_REL_ IC3 SG_ 2147485218 SavedUnit10_TrailerPosition 60000;
BA_REL_ "GenSigTimeoutTime" BU_SG_REL_ IC3 SG_ 2147485218 SavedUnit10_TrailerPosition 60000;
BA_REL_ "GenSigFirstTimeoutTime" BU_SG_REL_ IC3 SG_ 2147485216 SavedUnit9_TrailerName 60000;
BA_REL_ "GenSigTimeoutTime" BU_SG_REL_ IC3 SG_ 2147485216 SavedUnit9_TrailerName 60000;
BA_REL_ "GenSigFirstTimeoutTime" BU_SG_REL_ IC3 SG_ 2147485216 SavedUnit9_TrailerPosition 60000;
BA_REL_ "GenSigTimeoutTime" BU_SG_REL_ IC3 SG_ 2147485216 SavedUnit9_TrailerPosition 60000;
BA_REL_ "GenSigFirstTimeoutTime" BU_SG_REL_ IC3 SG_ 2147485214 SavedUnit8_TrailerName 60000;
BA_REL_ "GenSigTimeoutTime" BU_SG_REL_ IC3 SG_ 2147485214 SavedUnit8_TrailerName 60000;
BA_REL_ "GenSigFirstTimeoutTime" BU_SG_REL_ IC3 SG_ 2147485214 SavedUnit8_TrailerPosition 60000;
BA_REL_ "GenSigTimeoutTime" BU_SG_REL_ IC3 SG_ 2147485214 SavedUnit8_TrailerPosition 60000;
BA_REL_ "GenSigFirstTimeoutTime" BU_SG_REL_ IC3 SG_ 2147485212 SavedUnit7_TrailerPosition 60000;
BA_REL_ "GenSigTimeoutTime" BU_SG_REL_ IC3 SG_ 2147485212 SavedUnit7_TrailerPosition 60000;
BA_REL_ "GenSigFirstTimeoutTime" BU_SG_REL_ IC3 SG_ 2147485212 SavedUnit7_TrailerName 60000;
BA_REL_ "GenSigTimeoutTime" BU_SG_REL_ IC3 SG_ 2147485212 SavedUnit7_TrailerName 60000;
BA_REL_ "GenSigFirstTimeoutTime" BU_SG_REL_ IC3 SG_ 2147485210 SavedUnit6_TrailerPosition 60000;
BA_REL_ "GenSigTimeoutTime" BU_SG_REL_ IC3 SG_ 2147485210 SavedUnit6_TrailerPosition 60000;
BA_REL_ "GenSigFirstTimeoutTime" BU_SG_REL_ IC3 SG_ 2147485210 SavedUnit6_TrailerName 60000;
BA_REL_ "GenSigTimeoutTime" BU_SG_REL_ IC3 SG_ 2147485210 SavedUnit6_TrailerName 60000;
BA_REL_ "GenSigFirstTimeoutTime" BU_SG_REL_ IC3 SG_ 2147485208 SavedUnit5_TrailerName 60000;
BA_REL_ "GenSigTimeoutTime" BU_SG_REL_ IC3 SG_ 2147485208 SavedUnit5_TrailerName 60000;
BA_REL_ "GenSigFirstTimeoutTime" BU_SG_REL_ IC3 SG_ 2147485208 SavedUnit5_TrailerPosition 60000;
BA_REL_ "GenSigTimeoutTime" BU_SG_REL_ IC3 SG_ 2147485208 SavedUnit5_TrailerPosition 60000;
BA_REL_ "GenSigFirstTimeoutTime" BU_SG_REL_ IC3 SG_ 2147485206 SavedUnit4_TrailerPosition 60000;
BA_REL_ "GenSigTimeoutTime" BU_SG_REL_ IC3 SG_ 2147485206 SavedUnit4_TrailerPosition 60000;
BA_REL_ "GenSigFirstTimeoutTime" BU_SG_REL_ IC3 SG_ 2147485206 SavedUnit4_TrailerName 60000;
BA_REL_ "GenSigTimeoutTime" BU_SG_REL_ IC3 SG_ 2147485206 SavedUnit4_TrailerName 60000;
BA_REL_ "GenSigFirstTimeoutTime" BU_SG_REL_ IC3 SG_ 2147485204 SavedUnit3_TrailerPosition 60000;
BA_REL_ "GenSigTimeoutTime" BU_SG_REL_ IC3 SG_ 2147485204 SavedUnit3_TrailerPosition 60000;
BA_REL_ "GenSigFirstTimeoutTime" BU_SG_REL_ IC3 SG_ 2147485204 SavedUnit3_TrailerName 60000;
BA_REL_ "GenSigTimeoutTime" BU_SG_REL_ IC3 SG_ 2147485204 SavedUnit3_TrailerName 60000;
BA_REL_ "GenSigFirstTimeoutTime" BU_SG_REL_ IC3 SG_ 2147485202 SavedUnit2_TrailerName 60000;
BA_REL_ "GenSigTimeoutTime" BU_SG_REL_ IC3 SG_ 2147485202 SavedUnit2_TrailerName 60000;
BA_REL_ "GenSigFirstTimeoutTime" BU_SG_REL_ IC3 SG_ 2147485202 SavedUnit2_TrailerPosition 60000;
BA_REL_ "GenSigTimeoutTime" BU_SG_REL_ IC3 SG_ 2147485202 SavedUnit2_TrailerPosition 60000;
BA_REL_ "GenSigFirstTimeoutTime" BU_SG_REL_ IC3 SG_ 2147485200 SavedUnit1_TrailerPosition 60000;
BA_REL_ "GenSigTimeoutTime" BU_SG_REL_ IC3 SG_ 2147485200 SavedUnit1_TrailerPosition 60000;
BA_REL_ "GenSigFirstTimeoutTime" BU_SG_REL_ IC3 SG_ 2147485200 SavedUnit1_TrailerName 60000;
BA_REL_ "GenSigTimeoutTime" BU_SG_REL_ IC3 SG_ 2147485200 SavedUnit1_TrailerName 60000;
BA_REL_ "GenSigFirstTimeoutTime" BU_SG_REL_ TECU SG_ 2147484941 RSLAssistStatus 6000;
BA_REL_ "GenSigTimeoutTime" BU_SG_REL_ TECU SG_ 2147484941 RSLAssistStatus 1500;
BA_REL_ "GenSigFirstTimeoutTime" BU_SG_REL_ IC3 SG_ 2147484919 DayOfWeek_stat_ISig_4 4800;
BA_REL_ "GenSigTimeoutTime" BU_SG_REL_ IC3 SG_ 2147484919 DayOfWeek_stat_ISig_4 1200;
BA_REL_ "GenSigFirstTimeoutTime" BU_SG_REL_ CIOM SG_ 2147484919 DayOfWeek_stat_ISig_4 4800;
BA_REL_ "GenSigTimeoutTime" BU_SG_REL_ CIOM SG_ 2147484919 DayOfWeek_stat_ISig_4 1200;
BA_REL_ "GenSigFirstTimeoutTime" BU_SG_REL_ IC3 SG_ 2147484919 MinutesLocal_ISig_4 4800;
BA_REL_ "GenSigTimeoutTime" BU_SG_REL_ IC3 SG_ 2147484919 MinutesLocal_ISig_4 1200;
BA_REL_ "GenSigFirstTimeoutTime" BU_SG_REL_ CIOM SG_ 2147484919 MinutesLocal_ISig_4 4800;
BA_REL_ "GenSigTimeoutTime" BU_SG_REL_ CIOM SG_ 2147484919 MinutesLocal_ISig_4 1200;
BA_REL_ "GenSigFirstTimeoutTime" BU_SG_REL_ IC3 SG_ 2147484919 DayLocal_ISig_4 4800;
BA_REL_ "GenSigTimeoutTime" BU_SG_REL_ IC3 SG_ 2147484919 DayLocal_ISig_4 1200;
BA_REL_ "GenSigFirstTimeoutTime" BU_SG_REL_ CIOM SG_ 2147484919 DayLocal_ISig_4 4800;
BA_REL_ "GenSigTimeoutTime" BU_SG_REL_ CIOM SG_ 2147484919 DayLocal_ISig_4 1200;
BA_REL_ "GenSigFirstTimeoutTime" BU_SG_REL_ IC3 SG_ 2147484919 MonthLocal_ISig_4 4800;
BA_REL_ "GenSigTimeoutTime" BU_SG_REL_ IC3 SG_ 2147484919 MonthLocal_ISig_4 1200;
BA_REL_ "GenSigFirstTimeoutTime" BU_SG_REL_ CIOM SG_ 2147484919 MonthLocal_ISig_4 4800;
BA_REL_ "GenSigTimeoutTime" BU_SG_REL_ CIOM SG_ 2147484919 MonthLocal_ISig_4 1200;
BA_REL_ "GenSigFirstTimeoutTime" BU_SG_REL_ IC3 SG_ 2147484919 SecondsLocal_ISig_4 4800;
BA_REL_ "GenSigTimeoutTime" BU_SG_REL_ IC3 SG_ 2147484919 SecondsLocal_ISig_4 1200;
BA_REL_ "GenSigFirstTimeoutTime" BU_SG_REL_ CIOM SG_ 2147484919 SecondsLocal_ISig_4 4800;
BA_REL_ "GenSigTimeoutTime" BU_SG_REL_ CIOM SG_ 2147484919 SecondsLocal_ISig_4 1200;
BA_REL_ "GenSigFirstTimeoutTime" BU_SG_REL_ IC3 SG_ 2147484919 SelectedDaylightSaving_stat 4800;
BA_REL_ "GenSigTimeoutTime" BU_SG_REL_ IC3 SG_ 2147484919 SelectedDaylightSaving_stat 1200;
BA_REL_ "GenSigFirstTimeoutTime" BU_SG_REL_ CIOM SG_ 2147484919 YearLocal_ISig_4 4800;
BA_REL_ "GenSigTimeoutTime" BU_SG_REL_ CIOM SG_ 2147484919 YearLocal_ISig_4 1200;
BA_REL_ "GenSigFirstTimeoutTime" BU_SG_REL_ IC3 SG_ 2147484919 YearLocal_ISig_4 4800;
BA_REL_ "GenSigTimeoutTime" BU_SG_REL_ IC3 SG_ 2147484919 YearLocal_ISig_4 1200;
BA_REL_ "GenSigFirstTimeoutTime" BU_SG_REL_ IC3 SG_ 2147484919 HoursLocal_ISig_4 4800;
BA_REL_ "GenSigTimeoutTime" BU_SG_REL_ IC3 SG_ 2147484919 HoursLocal_ISig_4 1200;
BA_REL_ "GenSigFirstTimeoutTime" BU_SG_REL_ CIOM SG_ 2147484919 HoursLocal_ISig_4 4800;
BA_REL_ "GenSigTimeoutTime" BU_SG_REL_ CIOM SG_ 2147484919 HoursLocal_ISig_4 1200;
BA_REL_ "GenSigFirstTimeoutTime" BU_SG_REL_ TECU SG_ 2147484039 RequestedUpshiftDownshiftSteps 3000;
BA_REL_ "GenSigTimeoutTime" BU_SG_REL_ TECU SG_ 2147484039 RequestedUpshiftDownshiftSteps 120;
BA_REL_ "GenSigFirstTimeoutTime" BU_SG_REL_ TECU SG_ 2147484039 GearLeverPosition_ISig_4 3000;
BA_REL_ "GenSigTimeoutTime" BU_SG_REL_ TECU SG_ 2147484039 GearLeverPosition_ISig_4 500;
BA_REL_ "GenSigFirstTimeoutTime" BU_SG_REL_ BBM SG_ 2147484039 GearLeverPosition_ISig_4 3000;
BA_REL_ "GenSigTimeoutTime" BU_SG_REL_ BBM SG_ 2147484039 GearLeverPosition_ISig_4 500;
BA_REL_ "GenSigFirstTimeoutTime" BU_SG_REL_ IC3 SG_ 2147484039 GearLeverPosition_ISig_4 3000;
BA_REL_ "GenSigTimeoutTime" BU_SG_REL_ IC3 SG_ 2147484039 GearLeverPosition_ISig_4 500;
BA_REL_ "GenSigFirstTimeoutTime" BU_SG_REL_ TECU SG_ 2147484039 DownShiftRequest 3000;
BA_REL_ "GenSigTimeoutTime" BU_SG_REL_ TECU SG_ 2147484039 DownShiftRequest 120;
BA_REL_ "GenSigFirstTimeoutTime" BU_SG_REL_ TECU SG_ 2147484039 UpShiftRequest 3000;
BA_REL_ "GenSigTimeoutTime" BU_SG_REL_ TECU SG_ 2147484039 UpShiftRequest 120;
BA_REL_ "GenSigFirstTimeoutTime" BU_SG_REL_ TECU SG_ 2147484039 LimpHomeSwitch_stat 3000;
BA_REL_ "GenSigTimeoutTime" BU_SG_REL_ TECU SG_ 2147484039 LimpHomeSwitch_stat 120;
BA_REL_ "GenSigFirstTimeoutTime" BU_SG_REL_ TECU SG_ 2147484039 RequestForHighestGearRatio 3000;
BA_REL_ "GenSigTimeoutTime" BU_SG_REL_ TECU SG_ 2147484039 RequestForHighestGearRatio 120;
BA_REL_ "GenSigFirstTimeoutTime" BU_SG_REL_ TECU SG_ 2147484039 EconomyPowerSwitch_stat 3000;
BA_REL_ "GenSigTimeoutTime" BU_SG_REL_ TECU SG_ 2147484039 EconomyPowerSwitch_stat 120;
BA_REL_ "GenSigFirstTimeoutTime" BU_SG_REL_ IC3 SG_ 2147484975 FuelLostInWrongGear 24000;
BA_REL_ "GenSigTimeoutTime" BU_SG_REL_ IC3 SG_ 2147484975 FuelLostInWrongGear 6000;
BA_REL_ "GenSigFirstTimeoutTime" BU_SG_REL_ IC3 SG_ 2147484975 FuelSavedInCoasting 24000;
BA_REL_ "GenSigTimeoutTime" BU_SG_REL_ IC3 SG_ 2147484975 FuelSavedInCoasting 6000;
BA_REL_ "GenSigFirstTimeoutTime" BU_SG_REL_ CIOM SG_ 2147484701 AlarmClockAlarms_stat_Mode_ISig_ 3600;
BA_REL_ "GenSigTimeoutTime" BU_SG_REL_ CIOM SG_ 2147484701 AlarmClockAlarms_stat_Mode_ISig_ 900;
BA_REL_ "GenSigFirstTimeoutTime" BU_SG_REL_ IC3 SG_ 2147484701 AlarmClockAlarms_stat_Mode_ISig_ 3600;
BA_REL_ "GenSigTimeoutTime" BU_SG_REL_ IC3 SG_ 2147484701 AlarmClockAlarms_stat_Mode_ISig_ 900;
BA_REL_ "GenSigFirstTimeoutTime" BU_SG_REL_ IC3 SG_ 2147484701 AlarmClockAlarms_stat_Type_ISig_ 3600;
BA_REL_ "GenSigTimeoutTime" BU_SG_REL_ IC3 SG_ 2147484701 AlarmClockAlarms_stat_Type_ISig_ 900;
BA_REL_ "GenSigFirstTimeoutTime" BU_SG_REL_ CIOM SG_ 2147484701 AlarmClockAlarms_stat_Type_ISig_ 3600;
BA_REL_ "GenSigTimeoutTime" BU_SG_REL_ CIOM SG_ 2147484701 AlarmClockAlarms_stat_Type_ISig_ 900;
BA_REL_ "GenSigFirstTimeoutTime" BU_SG_REL_ IC3 SG_ 2147484701 AlarmClockAlarms_stat_DaySet_ISi 3600;
BA_REL_ "GenSigTimeoutTime" BU_SG_REL_ IC3 SG_ 2147484701 AlarmClockAlarms_stat_DaySet_ISi 900;
BA_REL_ "GenSigFirstTimeoutTime" BU_SG_REL_ CIOM SG_ 2147484701 AlarmClockAlarms_stat_DaySet_ISi 3600;
BA_REL_ "GenSigTimeoutTime" BU_SG_REL_ CIOM SG_ 2147484701 AlarmClockAlarms_stat_DaySet_ISi 900;
BA_REL_ "GenSigFirstTimeoutTime" BU_SG_REL_ IC3 SG_ 2147484701 AlarmClockAlarms_stat_ID_ISig_4 3600;
BA_REL_ "GenSigTimeoutTime" BU_SG_REL_ IC3 SG_ 2147484701 AlarmClockAlarms_stat_ID_ISig_4 900;
BA_REL_ "GenSigFirstTimeoutTime" BU_SG_REL_ CIOM SG_ 2147484701 AlarmClockAlarms_stat_ID_ISig_4 3600;
BA_REL_ "GenSigTimeoutTime" BU_SG_REL_ CIOM SG_ 2147484701 AlarmClockAlarms_stat_ID_ISig_4 900;
BA_REL_ "GenSigFirstTimeoutTime" BU_SG_REL_ IC3 SG_ 2147484701 AlmClkCurAlarm_stat_SetMin 3600;
BA_REL_ "GenSigTimeoutTime" BU_SG_REL_ IC3 SG_ 2147484701 AlmClkCurAlarm_stat_SetMin 900;
BA_REL_ "GenSigFirstTimeoutTime" BU_SG_REL_ CIOM SG_ 2147484701 AlmClkCurAlarm_stat_SetMin 3600;
BA_REL_ "GenSigTimeoutTime" BU_SG_REL_ CIOM SG_ 2147484701 AlmClkCurAlarm_stat_SetMin 900;
BA_REL_ "GenSigFirstTimeoutTime" BU_SG_REL_ IC3 SG_ 2147484701 AlarmClockAlarms_stat_Stat_ISig_ 3600;
BA_REL_ "GenSigTimeoutTime" BU_SG_REL_ IC3 SG_ 2147484701 AlarmClockAlarms_stat_Stat_ISig_ 900;
BA_REL_ "GenSigFirstTimeoutTime" BU_SG_REL_ CIOM SG_ 2147484701 AlarmClockAlarms_stat_Stat_ISig_ 3600;
BA_REL_ "GenSigTimeoutTime" BU_SG_REL_ CIOM SG_ 2147484701 AlarmClockAlarms_stat_Stat_ISig_ 900;
BA_REL_ "GenSigFirstTimeoutTime" BU_SG_REL_ CIOM SG_ 2147484701 AlmClkCurAlarm_stat_Stat 3600;
BA_REL_ "GenSigTimeoutTime" BU_SG_REL_ CIOM SG_ 2147484701 AlmClkCurAlarm_stat_Stat 900;
BA_REL_ "GenSigFirstTimeoutTime" BU_SG_REL_ IC3 SG_ 2147484701 AlmClkCurAlarm_stat_Stat 3600;
BA_REL_ "GenSigTimeoutTime" BU_SG_REL_ IC3 SG_ 2147484701 AlmClkCurAlarm_stat_Stat 900;
BA_REL_ "GenSigFirstTimeoutTime" BU_SG_REL_ IC3 SG_ 2147484701 AlmClkCurAlarm_stat_ID 3600;
BA_REL_ "GenSigTimeoutTime" BU_SG_REL_ IC3 SG_ 2147484701 AlmClkCurAlarm_stat_ID 900;
BA_REL_ "GenSigFirstTimeoutTime" BU_SG_REL_ CIOM SG_ 2147484701 AlmClkCurAlarm_stat_ID 3600;
BA_REL_ "GenSigTimeoutTime" BU_SG_REL_ CIOM SG_ 2147484701 AlmClkCurAlarm_stat_ID 900;
BA_REL_ "GenSigFirstTimeoutTime" BU_SG_REL_ IC3 SG_ 2147484701 AlarmClockAlarms_stat_SetMin_ISi 3600;
BA_REL_ "GenSigTimeoutTime" BU_SG_REL_ IC3 SG_ 2147484701 AlarmClockAlarms_stat_SetMin_ISi 900;
BA_REL_ "GenSigFirstTimeoutTime" BU_SG_REL_ CIOM SG_ 2147484701 AlarmClockAlarms_stat_SetMin_ISi 3600;
BA_REL_ "GenSigTimeoutTime" BU_SG_REL_ CIOM SG_ 2147484701 AlarmClockAlarms_stat_SetMin_ISi 900;
BA_REL_ "GenSigFirstTimeoutTime" BU_SG_REL_ IC3 SG_ 2147484701 AlmClkCurAlarm_stat_Type 3600;
BA_REL_ "GenSigTimeoutTime" BU_SG_REL_ IC3 SG_ 2147484701 AlmClkCurAlarm_stat_Type 900;
BA_REL_ "GenSigFirstTimeoutTime" BU_SG_REL_ CIOM SG_ 2147484701 AlmClkCurAlarm_stat_Type 3600;
BA_REL_ "GenSigTimeoutTime" BU_SG_REL_ CIOM SG_ 2147484701 AlmClkCurAlarm_stat_Type 900;
BA_REL_ "GenSigFirstTimeoutTime" BU_SG_REL_ CIOM SG_ 2147484701 AlarmClockAlarms_stat_SetHr_ISig 3600;
BA_REL_ "GenSigTimeoutTime" BU_SG_REL_ CIOM SG_ 2147484701 AlarmClockAlarms_stat_SetHr_ISig 900;
BA_REL_ "GenSigFirstTimeoutTime" BU_SG_REL_ IC3 SG_ 2147484701 AlarmClockAlarms_stat_SetHr_ISig 3600;
BA_REL_ "GenSigTimeoutTime" BU_SG_REL_ IC3 SG_ 2147484701 AlarmClockAlarms_stat_SetHr_ISig 900;
BA_REL_ "GenSigFirstTimeoutTime" BU_SG_REL_ IC3 SG_ 2147484701 AlmClkCurAlarm_stat_SetHr 3600;
BA_REL_ "GenSigTimeoutTime" BU_SG_REL_ IC3 SG_ 2147484701 AlmClkCurAlarm_stat_SetHr 900;
BA_REL_ "GenSigFirstTimeoutTime" BU_SG_REL_ CIOM SG_ 2147484701 AlmClkCurAlarm_stat_SetHr 3600;
BA_REL_ "GenSigTimeoutTime" BU_SG_REL_ CIOM SG_ 2147484701 AlmClkCurAlarm_stat_SetHr 900;
BA_REL_ "GenSigFirstTimeoutTime" BU_SG_REL_ CIOM SG_ 2147484743 ParkHeaterTimerReleased_stat_ISi 3000;
BA_REL_ "GenSigTimeoutTime" BU_SG_REL_ CIOM SG_ 2147484743 ParkHeaterTimerReleased_stat_ISi 600;
BA_REL_ "GenSigFirstTimeoutTime" BU_SG_REL_ CIOM SG_ 2147484743 PHTimerRqstAck_Hours_ISig_4 3000;
BA_REL_ "GenSigTimeoutTime" BU_SG_REL_ CIOM SG_ 2147484743 PHTimerRqstAck_Hours_ISig_4 600;
BA_REL_ "GenSigFirstTimeoutTime" BU_SG_REL_ CIOM SG_ 2147484743 PHTimerRqstAck_CurrentOp_ISig_4 3000;
BA_REL_ "GenSigTimeoutTime" BU_SG_REL_ CIOM SG_ 2147484743 PHTimerRqstAck_CurrentOp_ISig_4 600;
BA_REL_ "GenSigFirstTimeoutTime" BU_SG_REL_ CIOM SG_ 2147484743 PHTimerRqstAck_DayOfWeekRq_ISig_ 3000;
BA_REL_ "GenSigTimeoutTime" BU_SG_REL_ CIOM SG_ 2147484743 PHTimerRqstAck_DayOfWeekRq_ISig_ 600;
BA_REL_ "GenSigFirstTimeoutTime" BU_SG_REL_ CIOM SG_ 2147484743 PHTimerRqstAck_Minutes_ISig_4 3000;
BA_REL_ "GenSigTimeoutTime" BU_SG_REL_ CIOM SG_ 2147484743 PHTimerRqstAck_Minutes_ISig_4 600;
BA_REL_ "GenSigFirstTimeoutTime" BU_SG_REL_ CIOM SG_ 2147484743 AlarmClockNotification_Stat_ISig 3000;
BA_REL_ "GenSigTimeoutTime" BU_SG_REL_ CIOM SG_ 2147484743 AlarmClockNotification_Stat_ISig 600;
BA_REL_ "GenSigFirstTimeoutTime" BU_SG_REL_ IC3 SG_ 2147484743 AlarmClockNotification_Stat_ISig 3000;
BA_REL_ "GenSigTimeoutTime" BU_SG_REL_ IC3 SG_ 2147484743 AlarmClockNotification_Stat_ISig 600;
BA_REL_ "GenSigFirstTimeoutTime" BU_SG_REL_ IC3 SG_ 2147484743 AlarmClockNotification_Type_ISig 3000;
BA_REL_ "GenSigTimeoutTime" BU_SG_REL_ IC3 SG_ 2147484743 AlarmClockNotification_Type_ISig 600;
BA_REL_ "GenSigFirstTimeoutTime" BU_SG_REL_ CIOM SG_ 2147484743 AlarmClockNotification_Type_ISig 3000;
BA_REL_ "GenSigTimeoutTime" BU_SG_REL_ CIOM SG_ 2147484743 AlarmClockNotification_Type_ISig 600;
BA_REL_ "GenSigFirstTimeoutTime" BU_SG_REL_ IC3 SG_ 2147484743 AlarmClockNotification_ID_ISig_4 3000;
BA_REL_ "GenSigTimeoutTime" BU_SG_REL_ IC3 SG_ 2147484743 AlarmClockNotification_ID_ISig_4 600;
BA_REL_ "GenSigFirstTimeoutTime" BU_SG_REL_ CIOM SG_ 2147484743 AlarmClockNotification_ID_ISig_4 3000;
BA_REL_ "GenSigTimeoutTime" BU_SG_REL_ CIOM SG_ 2147484743 AlarmClockNotification_ID_ISig_4 600;
BA_REL_ "GenSigFirstTimeoutTime" BU_SG_REL_ IC3 SG_ 2147484921 HighResolutionTripDistance2 6000;
BA_REL_ "GenSigTimeoutTime" BU_SG_REL_ IC3 SG_ 2147484921 HighResolutionTripDistance2 1500;
BA_REL_ "GenSigFirstTimeoutTime" BU_SG_REL_ BBM SG_ 2147484921 HighResolutionTripDistance1_ISig 6000;
BA_REL_ "GenSigTimeoutTime" BU_SG_REL_ BBM SG_ 2147484921 HighResolutionTripDistance1_ISig 1500;
BA_REL_ "GenSigFirstTimeoutTime" BU_SG_REL_ IC3 SG_ 2147484921 HighResolutionTripDistance1_ISig 6000;
BA_REL_ "GenSigTimeoutTime" BU_SG_REL_ IC3 SG_ 2147484921 HighResolutionTripDistance1_ISig 1500;
BA_REL_ "GenSigFirstTimeoutTime" BU_SG_REL_ IC3 SG_ 2147484964 LoadIndCalWarning_Movement 24000;
BA_REL_ "GenSigTimeoutTime" BU_SG_REL_ IC3 SG_ 2147484964 LoadIndCalWarning_Movement 6000;
BA_REL_ "GenSigFirstTimeoutTime" BU_SG_REL_ IC3 SG_ 2147484964 LoadIndCalWarning_LiftedAxle 24000;
BA_REL_ "GenSigTimeoutTime" BU_SG_REL_ IC3 SG_ 2147484964 LoadIndCalWarning_LiftedAxle 6000;
BA_REL_ "GenSigFirstTimeoutTime" BU_SG_REL_ IC3 SG_ 2147484964 LoadIndCalWarning_LowSupplyPress 24000;
BA_REL_ "GenSigTimeoutTime" BU_SG_REL_ IC3 SG_ 2147484964 LoadIndCalWarning_LowSupplyPress 6000;
BA_REL_ "GenSigFirstTimeoutTime" BU_SG_REL_ IC3 SG_ 2147484964 LoadIndCalWarning_PBrakeApplied 24000;
BA_REL_ "GenSigTimeoutTime" BU_SG_REL_ IC3 SG_ 2147484964 LoadIndCalWarning_PBrakeApplied 6000;
BA_REL_ "GenSigFirstTimeoutTime" BU_SG_REL_ IC3 SG_ 2147484964 LoadIndCalWarning_SBrakesApplied 24000;
BA_REL_ "GenSigTimeoutTime" BU_SG_REL_ IC3 SG_ 2147484964 LoadIndCalWarning_SBrakesApplied 6000;
BA_REL_ "GenSigFirstTimeoutTime" BU_SG_REL_ IC3 SG_ 2147484964 LoadIndCalWarning_HighInclin 24000;
BA_REL_ "GenSigTimeoutTime" BU_SG_REL_ IC3 SG_ 2147484964 LoadIndCalWarning_HighInclin 6000;
BA_REL_ "GenSigFirstTimeoutTime" BU_SG_REL_ IC3 SG_ 2147484964 LoadTrailer3_ISig_4 24000;
BA_REL_ "GenSigTimeoutTime" BU_SG_REL_ IC3 SG_ 2147484964 LoadTrailer3_ISig_4 6000;
BA_REL_ "GenSigFirstTimeoutTime" BU_SG_REL_ BBM SG_ 2147484964 LoadTrailer3_ISig_4 24000;
BA_REL_ "GenSigTimeoutTime" BU_SG_REL_ BBM SG_ 2147484964 LoadTrailer3_ISig_4 6000;
BA_REL_ "GenSigFirstTimeoutTime" BU_SG_REL_ CIOM SG_ 2147484964 LoadTrailer3_ISig_4 24000;
BA_REL_ "GenSigTimeoutTime" BU_SG_REL_ CIOM SG_ 2147484964 LoadTrailer3_ISig_4 6000;
BA_REL_ "GenSigFirstTimeoutTime" BU_SG_REL_ BBM SG_ 2147484964 LoadVehCombCargoTot 24000;
BA_REL_ "GenSigTimeoutTime" BU_SG_REL_ BBM SG_ 2147484964 LoadVehCombCargoTot 6000;
BA_REL_ "GenSigFirstTimeoutTime" BU_SG_REL_ IC3 SG_ 2147484964 LoadIndCalWarning_GearNotNeutral 24000;
BA_REL_ "GenSigTimeoutTime" BU_SG_REL_ IC3 SG_ 2147484964 LoadIndCalWarning_GearNotNeutral 6000;
BA_REL_ "GenSigFirstTimeoutTime" BU_SG_REL_ IC3 SG_ 2147484964 LoadIndCalWarning_HighLoadDelta 24000;
BA_REL_ "GenSigTimeoutTime" BU_SG_REL_ IC3 SG_ 2147484964 LoadIndCalWarning_HighLoadDelta 6000;
BA_REL_ "GenSigFirstTimeoutTime" BU_SG_REL_ IC3 SG_ 2147484963 LoadTrailer2Back 24000;
BA_REL_ "GenSigTimeoutTime" BU_SG_REL_ IC3 SG_ 2147484963 LoadTrailer2Back 6000;
BA_REL_ "GenSigFirstTimeoutTime" BU_SG_REL_ IC3 SG_ 2147484963 LoadTrailer3Front 24000;
BA_REL_ "GenSigTimeoutTime" BU_SG_REL_ IC3 SG_ 2147484963 LoadTrailer3Front 6000;
BA_REL_ "GenSigFirstTimeoutTime" BU_SG_REL_ IC3 SG_ 2147484963 LoadTrailer5Back 24000;
BA_REL_ "GenSigTimeoutTime" BU_SG_REL_ IC3 SG_ 2147484963 LoadTrailer5Back 6000;
BA_REL_ "GenSigFirstTimeoutTime" BU_SG_REL_ IC3 SG_ 2147484963 LoadTrailer4Front 24000;
BA_REL_ "GenSigTimeoutTime" BU_SG_REL_ IC3 SG_ 2147484963 LoadTrailer4Front 6000;
BA_REL_ "GenSigFirstTimeoutTime" BU_SG_REL_ IC3 SG_ 2147484962 LoadTrailer1Front 24000;
BA_REL_ "GenSigTimeoutTime" BU_SG_REL_ IC3 SG_ 2147484962 LoadTrailer1Front 6000;
BA_REL_ "GenSigFirstTimeoutTime" BU_SG_REL_ IC3 SG_ 2147484962 LoadTruck_ISig_4 24000;
BA_REL_ "GenSigTimeoutTime" BU_SG_REL_ IC3 SG_ 2147484962 LoadTruck_ISig_4 6000;
BA_REL_ "GenSigFirstTimeoutTime" BU_SG_REL_ CIOM SG_ 2147484962 LoadTruck_ISig_4 24000;
BA_REL_ "GenSigTimeoutTime" BU_SG_REL_ CIOM SG_ 2147484962 LoadTruck_ISig_4 6000;
BA_REL_ "GenSigFirstTimeoutTime" BU_SG_REL_ DACU SG_ 2147484962 LoadTruck_ISig_4 24000;
BA_REL_ "GenSigTimeoutTime" BU_SG_REL_ DACU SG_ 2147484962 LoadTruck_ISig_4 6000;
BA_REL_ "GenSigFirstTimeoutTime" BU_SG_REL_ BBM SG_ 2147484962 LoadTruck_ISig_4 24000;
BA_REL_ "GenSigTimeoutTime" BU_SG_REL_ BBM SG_ 2147484962 LoadTruck_ISig_4 6000;
BA_REL_ "GenSigFirstTimeoutTime" BU_SG_REL_ BBM SG_ 2147484962 LoadTrailer1_ISig_4 24000;
BA_REL_ "GenSigTimeoutTime" BU_SG_REL_ BBM SG_ 2147484962 LoadTrailer1_ISig_4 6000;
BA_REL_ "GenSigFirstTimeoutTime" BU_SG_REL_ IC3 SG_ 2147484962 LoadTrailer1_ISig_4 24000;
BA_REL_ "GenSigTimeoutTime" BU_SG_REL_ IC3 SG_ 2147484962 LoadTrailer1_ISig_4 6000;
BA_REL_ "GenSigFirstTimeoutTime" BU_SG_REL_ CIOM SG_ 2147484962 LoadTrailer1_ISig_4 24000;
BA_REL_ "GenSigTimeoutTime" BU_SG_REL_ CIOM SG_ 2147484962 LoadTrailer1_ISig_4 6000;
BA_REL_ "GenSigFirstTimeoutTime" BU_SG_REL_ IC3 SG_ 2147484962 LoadTrailer5Front 24000;
BA_REL_ "GenSigTimeoutTime" BU_SG_REL_ IC3 SG_ 2147484962 LoadTrailer5Front 6000;
BA_REL_ "GenSigFirstTimeoutTime" BU_SG_REL_ IC3 SG_ 2147484961 LoadTrailer4_ISig_4 24000;
BA_REL_ "GenSigTimeoutTime" BU_SG_REL_ IC3 SG_ 2147484961 LoadTrailer4_ISig_4 6000;
BA_REL_ "GenSigFirstTimeoutTime" BU_SG_REL_ BBM SG_ 2147484961 LoadTrailer4_ISig_4 24000;
BA_REL_ "GenSigTimeoutTime" BU_SG_REL_ BBM SG_ 2147484961 LoadTrailer4_ISig_4 6000;
BA_REL_ "GenSigFirstTimeoutTime" BU_SG_REL_ CIOM SG_ 2147484961 LoadTrailer4_ISig_4 24000;
BA_REL_ "GenSigTimeoutTime" BU_SG_REL_ CIOM SG_ 2147484961 LoadTrailer4_ISig_4 6000;
BA_REL_ "GenSigFirstTimeoutTime" BU_SG_REL_ IC3 SG_ 2147484961 LoadTrailer3Back 24000;
BA_REL_ "GenSigTimeoutTime" BU_SG_REL_ IC3 SG_ 2147484961 LoadTrailer3Back 6000;
BA_REL_ "GenSigFirstTimeoutTime" BU_SG_REL_ IC3 SG_ 2147484961 LoadTruckRear 24000;
BA_REL_ "GenSigTimeoutTime" BU_SG_REL_ IC3 SG_ 2147484961 LoadTruckRear 6000;
BA_REL_ "GenSigFirstTimeoutTime" BU_SG_REL_ BBM SG_ 2147484961 LoadTrailer2_ISig_4 24000;
BA_REL_ "GenSigTimeoutTime" BU_SG_REL_ BBM SG_ 2147484961 LoadTrailer2_ISig_4 6000;
BA_REL_ "GenSigFirstTimeoutTime" BU_SG_REL_ CIOM SG_ 2147484961 LoadTrailer2_ISig_4 24000;
BA_REL_ "GenSigTimeoutTime" BU_SG_REL_ CIOM SG_ 2147484961 LoadTrailer2_ISig_4 6000;
BA_REL_ "GenSigFirstTimeoutTime" BU_SG_REL_ IC3 SG_ 2147484961 LoadTrailer2_ISig_4 24000;
BA_REL_ "GenSigTimeoutTime" BU_SG_REL_ IC3 SG_ 2147484961 LoadTrailer2_ISig_4 6000;
BA_REL_ "GenSigFirstTimeoutTime" BU_SG_REL_ IC3 SG_ 2147484960 CalLoadTrailer2Axle3_ISig_4 24000;
BA_REL_ "GenSigTimeoutTime" BU_SG_REL_ IC3 SG_ 2147484960 CalLoadTrailer2Axle3_ISig_4 6000;
BA_REL_ "GenSigFirstTimeoutTime" BU_SG_REL_ CIOM SG_ 2147484960 CalLoadTrailer2Axle3_ISig_4 24000;
BA_REL_ "GenSigTimeoutTime" BU_SG_REL_ CIOM SG_ 2147484960 CalLoadTrailer2Axle3_ISig_4 6000;
BA_REL_ "GenSigFirstTimeoutTime" BU_SG_REL_ BBM SG_ 2147484960 CalLoadTrailer2Axle3_ISig_4 24000;
BA_REL_ "GenSigTimeoutTime" BU_SG_REL_ BBM SG_ 2147484960 CalLoadTrailer2Axle3_ISig_4 6000;
BA_REL_ "GenSigFirstTimeoutTime" BU_SG_REL_ IC3 SG_ 2147484960 CalLoadTrailer3Axle2_ISig_4 24000;
BA_REL_ "GenSigTimeoutTime" BU_SG_REL_ IC3 SG_ 2147484960 CalLoadTrailer3Axle2_ISig_4 6000;
BA_REL_ "GenSigFirstTimeoutTime" BU_SG_REL_ CIOM SG_ 2147484960 CalLoadTrailer3Axle2_ISig_4 24000;
BA_REL_ "GenSigTimeoutTime" BU_SG_REL_ CIOM SG_ 2147484960 CalLoadTrailer3Axle2_ISig_4 6000;
BA_REL_ "GenSigFirstTimeoutTime" BU_SG_REL_ IC3 SG_ 2147484960 CalLoadTrailer3Axle6_ISig_4 24000;
BA_REL_ "GenSigTimeoutTime" BU_SG_REL_ IC3 SG_ 2147484960 CalLoadTrailer3Axle6_ISig_4 6000;
BA_REL_ "GenSigFirstTimeoutTime" BU_SG_REL_ CIOM SG_ 2147484960 CalLoadTrailer3Axle6_ISig_4 24000;
BA_REL_ "GenSigTimeoutTime" BU_SG_REL_ CIOM SG_ 2147484960 CalLoadTrailer3Axle6_ISig_4 6000;
BA_REL_ "GenSigFirstTimeoutTime" BU_SG_REL_ BBM SG_ 2147484953 LoadVehCombination 24000;
BA_REL_ "GenSigTimeoutTime" BU_SG_REL_ BBM SG_ 2147484953 LoadVehCombination 6000;
BA_REL_ "GenSigFirstTimeoutTime" BU_SG_REL_ IC3 SG_ 2147484953 LoadVehCombination 24000;
BA_REL_ "GenSigTimeoutTime" BU_SG_REL_ IC3 SG_ 2147484953 LoadVehCombination 6000;
BA_REL_ "GenSigFirstTimeoutTime" BU_SG_REL_ IC3 SG_ 2147484953 LoadTruckFront 24000;
BA_REL_ "GenSigTimeoutTime" BU_SG_REL_ IC3 SG_ 2147484953 LoadTruckFront 6000;
BA_REL_ "GenSigFirstTimeoutTime" BU_SG_REL_ IC3 SG_ 2147484953 LoadVehCombCargoRel 24000;
BA_REL_ "GenSigTimeoutTime" BU_SG_REL_ IC3 SG_ 2147484953 LoadVehCombCargoRel 6000;
BA_REL_ "GenSigFirstTimeoutTime" BU_SG_REL_ IC3 SG_ 2147484953 LoadTrailer1Back 24000;
BA_REL_ "GenSigTimeoutTime" BU_SG_REL_ IC3 SG_ 2147484953 LoadTrailer1Back 6000;
BA_REL_ "GenSigFirstTimeoutTime" BU_SG_REL_ CIOM SG_ 2147484952 CalLoadTrailer3Axle4_ISig_4 24000;
BA_REL_ "GenSigTimeoutTime" BU_SG_REL_ CIOM SG_ 2147484952 CalLoadTrailer3Axle4_ISig_4 6000;
BA_REL_ "GenSigFirstTimeoutTime" BU_SG_REL_ IC3 SG_ 2147484952 CalLoadTrailer3Axle4_ISig_4 24000;
BA_REL_ "GenSigTimeoutTime" BU_SG_REL_ IC3 SG_ 2147484952 CalLoadTrailer3Axle4_ISig_4 6000;
BA_REL_ "GenSigFirstTimeoutTime" BU_SG_REL_ CIOM SG_ 2147484952 CalLoadTrailer2Axle2_ISig_4 24000;
BA_REL_ "GenSigTimeoutTime" BU_SG_REL_ CIOM SG_ 2147484952 CalLoadTrailer2Axle2_ISig_4 6000;
BA_REL_ "GenSigFirstTimeoutTime" BU_SG_REL_ IC3 SG_ 2147484952 CalLoadTrailer2Axle2_ISig_4 24000;
BA_REL_ "GenSigTimeoutTime" BU_SG_REL_ IC3 SG_ 2147484952 CalLoadTrailer2Axle2_ISig_4 6000;
BA_REL_ "GenSigFirstTimeoutTime" BU_SG_REL_ BBM SG_ 2147484952 CalLoadTrailer2Axle2_ISig_4 24000;
BA_REL_ "GenSigTimeoutTime" BU_SG_REL_ BBM SG_ 2147484952 CalLoadTrailer2Axle2_ISig_4 6000;
BA_REL_ "GenSigFirstTimeoutTime" BU_SG_REL_ CIOM SG_ 2147484952 CalLoadTrailer1Axle6_ISig_4 24000;
BA_REL_ "GenSigTimeoutTime" BU_SG_REL_ CIOM SG_ 2147484952 CalLoadTrailer1Axle6_ISig_4 6000;
BA_REL_ "GenSigFirstTimeoutTime" BU_SG_REL_ IC3 SG_ 2147484952 CalLoadTrailer1Axle6_ISig_4 24000;
BA_REL_ "GenSigTimeoutTime" BU_SG_REL_ IC3 SG_ 2147484952 CalLoadTrailer1Axle6_ISig_4 6000;
BA_REL_ "GenSigFirstTimeoutTime" BU_SG_REL_ CIOM SG_ 2147484952 CalLoadTrailer5Axle6_ISig_4 24000;
BA_REL_ "GenSigTimeoutTime" BU_SG_REL_ CIOM SG_ 2147484952 CalLoadTrailer5Axle6_ISig_4 6000;
BA_REL_ "GenSigFirstTimeoutTime" BU_SG_REL_ IC3 SG_ 2147484952 CalLoadTrailer5Axle6_ISig_4 24000;
BA_REL_ "GenSigTimeoutTime" BU_SG_REL_ IC3 SG_ 2147484952 CalLoadTrailer5Axle6_ISig_4 6000;
BA_REL_ "GenSigFirstTimeoutTime" BU_SG_REL_ IC3 SG_ 2147484951 CalLoadTrailer1Axle4_ISig_4 24000;
BA_REL_ "GenSigTimeoutTime" BU_SG_REL_ IC3 SG_ 2147484951 CalLoadTrailer1Axle4_ISig_4 6000;
BA_REL_ "GenSigFirstTimeoutTime" BU_SG_REL_ CIOM SG_ 2147484951 CalLoadTrailer1Axle4_ISig_4 24000;
BA_REL_ "GenSigTimeoutTime" BU_SG_REL_ CIOM SG_ 2147484951 CalLoadTrailer1Axle4_ISig_4 6000;
BA_REL_ "GenSigFirstTimeoutTime" BU_SG_REL_ BBM SG_ 2147484951 CalLoadTrailer1Axle4_ISig_4 24000;
BA_REL_ "GenSigTimeoutTime" BU_SG_REL_ BBM SG_ 2147484951 CalLoadTrailer1Axle4_ISig_4 6000;
BA_REL_ "GenSigFirstTimeoutTime" BU_SG_REL_ CIOM SG_ 2147484951 CalLoadTrailer4Axle2_ISig_4 24000;
BA_REL_ "GenSigTimeoutTime" BU_SG_REL_ CIOM SG_ 2147484951 CalLoadTrailer4Axle2_ISig_4 6000;
BA_REL_ "GenSigFirstTimeoutTime" BU_SG_REL_ IC3 SG_ 2147484951 CalLoadTrailer4Axle2_ISig_4 24000;
BA_REL_ "GenSigTimeoutTime" BU_SG_REL_ IC3 SG_ 2147484951 CalLoadTrailer4Axle2_ISig_4 6000;
BA_REL_ "GenSigFirstTimeoutTime" BU_SG_REL_ CIOM SG_ 2147484951 CalLoadTrailer2Axle1_ISig_4 24000;
BA_REL_ "GenSigTimeoutTime" BU_SG_REL_ CIOM SG_ 2147484951 CalLoadTrailer2Axle1_ISig_4 6000;
BA_REL_ "GenSigFirstTimeoutTime" BU_SG_REL_ BBM SG_ 2147484951 CalLoadTrailer2Axle1_ISig_4 24000;
BA_REL_ "GenSigTimeoutTime" BU_SG_REL_ BBM SG_ 2147484951 CalLoadTrailer2Axle1_ISig_4 6000;
BA_REL_ "GenSigFirstTimeoutTime" BU_SG_REL_ IC3 SG_ 2147484951 CalLoadTrailer2Axle1_ISig_4 24000;
BA_REL_ "GenSigTimeoutTime" BU_SG_REL_ IC3 SG_ 2147484951 CalLoadTrailer2Axle1_ISig_4 6000;
BA_REL_ "GenSigFirstTimeoutTime" BU_SG_REL_ CIOM SG_ 2147484951 CalLoadTrailer4Axle3_ISig_4 24000;
BA_REL_ "GenSigTimeoutTime" BU_SG_REL_ CIOM SG_ 2147484951 CalLoadTrailer4Axle3_ISig_4 6000;
BA_REL_ "GenSigFirstTimeoutTime" BU_SG_REL_ IC3 SG_ 2147484951 CalLoadTrailer4Axle3_ISig_4 24000;
BA_REL_ "GenSigTimeoutTime" BU_SG_REL_ IC3 SG_ 2147484951 CalLoadTrailer4Axle3_ISig_4 6000;
BA_REL_ "GenSigFirstTimeoutTime" BU_SG_REL_ BBM SG_ 2147484950 CalLoadTruckRearAxle2_ISig_4 24000;
BA_REL_ "GenSigTimeoutTime" BU_SG_REL_ BBM SG_ 2147484950 CalLoadTruckRearAxle2_ISig_4 6000;
BA_REL_ "GenSigFirstTimeoutTime" BU_SG_REL_ IC3 SG_ 2147484950 CalLoadTruckRearAxle2_ISig_4 24000;
BA_REL_ "GenSigTimeoutTime" BU_SG_REL_ IC3 SG_ 2147484950 CalLoadTruckRearAxle2_ISig_4 6000;
BA_REL_ "GenSigFirstTimeoutTime" BU_SG_REL_ CIOM SG_ 2147484950 CalLoadTruckRearAxle2_ISig_4 24000;
BA_REL_ "GenSigTimeoutTime" BU_SG_REL_ CIOM SG_ 2147484950 CalLoadTruckRearAxle2_ISig_4 6000;
BA_REL_ "GenSigFirstTimeoutTime" BU_SG_REL_ BBM SG_ 2147484950 CalLoadTruckRearAxle3_ISig_4 24000;
BA_REL_ "GenSigTimeoutTime" BU_SG_REL_ BBM SG_ 2147484950 CalLoadTruckRearAxle3_ISig_4 6000;
BA_REL_ "GenSigFirstTimeoutTime" BU_SG_REL_ CIOM SG_ 2147484950 CalLoadTruckRearAxle3_ISig_4 24000;
BA_REL_ "GenSigTimeoutTime" BU_SG_REL_ CIOM SG_ 2147484950 CalLoadTruckRearAxle3_ISig_4 6000;
BA_REL_ "GenSigFirstTimeoutTime" BU_SG_REL_ IC3 SG_ 2147484950 CalLoadTruckRearAxle3_ISig_4 24000;
BA_REL_ "GenSigTimeoutTime" BU_SG_REL_ IC3 SG_ 2147484950 CalLoadTruckRearAxle3_ISig_4 6000;
BA_REL_ "GenSigFirstTimeoutTime" BU_SG_REL_ IC3 SG_ 2147484950 CalLoadTrailer3Axle5_ISig_4 24000;
BA_REL_ "GenSigTimeoutTime" BU_SG_REL_ IC3 SG_ 2147484950 CalLoadTrailer3Axle5_ISig_4 6000;
BA_REL_ "GenSigFirstTimeoutTime" BU_SG_REL_ CIOM SG_ 2147484950 CalLoadTrailer3Axle5_ISig_4 24000;
BA_REL_ "GenSigTimeoutTime" BU_SG_REL_ CIOM SG_ 2147484950 CalLoadTrailer3Axle5_ISig_4 6000;
BA_REL_ "GenSigFirstTimeoutTime" BU_SG_REL_ IC3 SG_ 2147484950 CalLoadTrailer4Axle6_ISig_4 24000;
BA_REL_ "GenSigTimeoutTime" BU_SG_REL_ IC3 SG_ 2147484950 CalLoadTrailer4Axle6_ISig_4 6000;
BA_REL_ "GenSigFirstTimeoutTime" BU_SG_REL_ CIOM SG_ 2147484950 CalLoadTrailer4Axle6_ISig_4 24000;
BA_REL_ "GenSigTimeoutTime" BU_SG_REL_ CIOM SG_ 2147484950 CalLoadTrailer4Axle6_ISig_4 6000;
BA_REL_ "GenSigFirstTimeoutTime" BU_SG_REL_ CIOM SG_ 2147484949 CalLoadTrailer5Axle2_ISig_4 24000;
BA_REL_ "GenSigTimeoutTime" BU_SG_REL_ CIOM SG_ 2147484949 CalLoadTrailer5Axle2_ISig_4 6000;
BA_REL_ "GenSigFirstTimeoutTime" BU_SG_REL_ IC3 SG_ 2147484949 CalLoadTrailer5Axle2_ISig_4 24000;
BA_REL_ "GenSigTimeoutTime" BU_SG_REL_ IC3 SG_ 2147484949 CalLoadTrailer5Axle2_ISig_4 6000;
BA_REL_ "GenSigFirstTimeoutTime" BU_SG_REL_ IC3 SG_ 2147484949 CalLoadTrailer1Axle2_ISig_4 24000;
BA_REL_ "GenSigTimeoutTime" BU_SG_REL_ IC3 SG_ 2147484949 CalLoadTrailer1Axle2_ISig_4 6000;
BA_REL_ "GenSigFirstTimeoutTime" BU_SG_REL_ CIOM SG_ 2147484949 CalLoadTrailer1Axle2_ISig_4 24000;
BA_REL_ "GenSigTimeoutTime" BU_SG_REL_ CIOM SG_ 2147484949 CalLoadTrailer1Axle2_ISig_4 6000;
BA_REL_ "GenSigFirstTimeoutTime" BU_SG_REL_ BBM SG_ 2147484949 CalLoadTrailer1Axle2_ISig_4 24000;
BA_REL_ "GenSigTimeoutTime" BU_SG_REL_ BBM SG_ 2147484949 CalLoadTrailer1Axle2_ISig_4 6000;
BA_REL_ "GenSigFirstTimeoutTime" BU_SG_REL_ IC3 SG_ 2147484949 CalLoadTrailer1Axle5_ISig_4 24000;
BA_REL_ "GenSigTimeoutTime" BU_SG_REL_ IC3 SG_ 2147484949 CalLoadTrailer1Axle5_ISig_4 6000;
BA_REL_ "GenSigFirstTimeoutTime" BU_SG_REL_ CIOM SG_ 2147484949 CalLoadTrailer1Axle5_ISig_4 24000;
BA_REL_ "GenSigTimeoutTime" BU_SG_REL_ CIOM SG_ 2147484949 CalLoadTrailer1Axle5_ISig_4 6000;
BA_REL_ "GenSigFirstTimeoutTime" BU_SG_REL_ CIOM SG_ 2147484949 CalLoadTrailer2Axle4_ISig_4 24000;
BA_REL_ "GenSigTimeoutTime" BU_SG_REL_ CIOM SG_ 2147484949 CalLoadTrailer2Axle4_ISig_4 6000;
BA_REL_ "GenSigFirstTimeoutTime" BU_SG_REL_ BBM SG_ 2147484949 CalLoadTrailer2Axle4_ISig_4 24000;
BA_REL_ "GenSigTimeoutTime" BU_SG_REL_ BBM SG_ 2147484949 CalLoadTrailer2Axle4_ISig_4 6000;
BA_REL_ "GenSigFirstTimeoutTime" BU_SG_REL_ IC3 SG_ 2147484949 CalLoadTrailer2Axle4_ISig_4 24000;
BA_REL_ "GenSigTimeoutTime" BU_SG_REL_ IC3 SG_ 2147484949 CalLoadTrailer2Axle4_ISig_4 6000;
BA_REL_ "GenSigFirstTimeoutTime" BU_SG_REL_ IC3 SG_ 2147485064 WasherFluidLevel_ISig_4 12000;
BA_REL_ "GenSigTimeoutTime" BU_SG_REL_ IC3 SG_ 2147485064 WasherFluidLevel_ISig_4 3000;
BA_REL_ "GenSigFirstTimeoutTime" BU_SG_REL_ IC3 SG_ 2147485064 FuelVolume_ISig_4 12000;
BA_REL_ "GenSigTimeoutTime" BU_SG_REL_ IC3 SG_ 2147485064 FuelVolume_ISig_4 3000;
BA_REL_ "GenSigFirstTimeoutTime" BU_SG_REL_ EMS SG_ 2147485064 KFactor 12000;
BA_REL_ "GenSigTimeoutTime" BU_SG_REL_ EMS SG_ 2147485064 KFactor 3000;
BA_REL_ "GenSigFirstTimeoutTime" BU_SG_REL_ TECU SG_ 2147485064 KFactor 12000;
BA_REL_ "GenSigTimeoutTime" BU_SG_REL_ TECU SG_ 2147485064 KFactor 3000;
BA_REL_ "GenSigFirstTimeoutTime" BU_SG_REL_ BBM SG_ 2147485064 KFactor 12000;
BA_REL_ "GenSigTimeoutTime" BU_SG_REL_ BBM SG_ 2147485064 KFactor 3000;
BA_REL_ "GenSigFirstTimeoutTime" BU_SG_REL_ DACU SG_ 2147485064 KFactor 12000;
BA_REL_ "GenSigTimeoutTime" BU_SG_REL_ DACU SG_ 2147485064 KFactor 3000;
BA_REL_ "GenSigFirstTimeoutTime" BU_SG_REL_ IC3 SG_ 2147485064 ManTransmiOilTemp_ISig_4 12000;
BA_REL_ "GenSigTimeoutTime" BU_SG_REL_ IC3 SG_ 2147485064 ManTransmiOilTemp_ISig_4 3000;
BA_REL_ "GenSigFirstTimeoutTime" BU_SG_REL_ IC3 SG_ 2147485064 EngSpeedGreenAreaMode_ISig_4 12000;
BA_REL_ "GenSigTimeoutTime" BU_SG_REL_ IC3 SG_ 2147485064 EngSpeedGreenAreaMode_ISig_4 3000;
BA_REL_ "GenSigFirstTimeoutTime" BU_SG_REL_ CIOM SG_ 2147484698 CabRoofSignLightFeedback_stat 6000;
BA_REL_ "GenSigTimeoutTime" BU_SG_REL_ CIOM SG_ 2147484698 CabRoofSignLightFeedback_stat 6000;
BA_REL_ "GenSigFirstTimeoutTime" BU_SG_REL_ CIOM SG_ 2147484698 TemporaryRSLStatus 6000;
BA_REL_ "GenSigTimeoutTime" BU_SG_REL_ CIOM SG_ 2147484698 TemporaryRSLStatus 6000;
BA_REL_ "GenSigFirstTimeoutTime" BU_SG_REL_ CIOM SG_ 2147484698 CabExtraSideWrknLightFdbk_stat_I 6000;
BA_REL_ "GenSigTimeoutTime" BU_SG_REL_ CIOM SG_ 2147484698 CabExtraSideWrknLightFdbk_stat_I 6000;
BA_REL_ "GenSigFirstTimeoutTime" BU_SG_REL_ BBM SG_ 2147484698 CabExtraSideWrknLightFdbk_stat_I 3000;
BA_REL_ "GenSigTimeoutTime" BU_SG_REL_ BBM SG_ 2147484698 CabExtraSideWrknLightFdbk_stat_I 600;
BA_REL_ "GenSigFirstTimeoutTime" BU_SG_REL_ BBM SG_ 2147484698 CabWrknLightChassisFdbk_stat_ISi 3000;
BA_REL_ "GenSigTimeoutTime" BU_SG_REL_ BBM SG_ 2147484698 CabWrknLightChassisFdbk_stat_ISi 600;
BA_REL_ "GenSigFirstTimeoutTime" BU_SG_REL_ CIOM SG_ 2147484698 CabWrknLightChassisFdbk_stat_ISi 6000;
BA_REL_ "GenSigTimeoutTime" BU_SG_REL_ CIOM SG_ 2147484698 CabWrknLightChassisFdbk_stat_ISi 6000;
BA_REL_ "GenSigFirstTimeoutTime" BU_SG_REL_ CIOM SG_ 2147484698 CabTrailerBodyLgthnFdbk_stat 6000;
BA_REL_ "GenSigTimeoutTime" BU_SG_REL_ CIOM SG_ 2147484698 CabTrailerBodyLgthnFdbk_stat 6000;
BA_REL_ "GenSigFirstTimeoutTime" BU_SG_REL_ BBM SG_ 2147484698 DiffLockInterWhlStatusSplitBox_I 3000;
BA_REL_ "GenSigTimeoutTime" BU_SG_REL_ BBM SG_ 2147484698 DiffLockInterWhlStatusSplitBox_I 600;
BA_REL_ "GenSigFirstTimeoutTime" BU_SG_REL_ CIOM SG_ 2147484698 BodyOrCabWorkingLightFdbk_stat_I 6000;
BA_REL_ "GenSigTimeoutTime" BU_SG_REL_ CIOM SG_ 2147484698 BodyOrCabWorkingLightFdbk_stat_I 6000;
BA_REL_ "GenSigFirstTimeoutTime" BU_SG_REL_ BBM SG_ 2147484698 BodyOrCabWorkingLightFdbk_stat_I 3000;
BA_REL_ "GenSigTimeoutTime" BU_SG_REL_ BBM SG_ 2147484698 BodyOrCabWorkingLightFdbk_stat_I 600;
BA_REL_ "GenSigFirstTimeoutTime" BU_SG_REL_ CIOM SG_ 2147484698 WheelBasedVehicleSpeedLowRes_ISi 6000;
BA_REL_ "GenSigTimeoutTime" BU_SG_REL_ CIOM SG_ 2147484698 WheelBasedVehicleSpeedLowRes_ISi 6000;
BA_REL_ "GenSigFirstTimeoutTime" BU_SG_REL_ EMS SG_ 2147484698 AirDryerCoolingFanSpeed_rqst 6000;
BA_REL_ "GenSigTimeoutTime" BU_SG_REL_ EMS SG_ 2147484698 AirDryerCoolingFanSpeed_rqst 1500;
BA_REL_ "GenSigFirstTimeoutTime" BU_SG_REL_ CIOM SG_ 2147484698 CabFrontSpotFeedback_Status 6000;
BA_REL_ "GenSigTimeoutTime" BU_SG_REL_ CIOM SG_ 2147484698 CabFrontSpotFeedback_Status 6000;
BA_REL_ "GenSigFirstTimeoutTime" BU_SG_REL_ CIOM SG_ 2147484698 CabTiltEnableStatus 6000;
BA_REL_ "GenSigTimeoutTime" BU_SG_REL_ CIOM SG_ 2147484698 CabTiltEnableStatus 6000;
BA_REL_ "GenSigFirstTimeoutTime" BU_SG_REL_ BBM SG_ 2147484698 TransmReverseDirectionSw_stat_IS 3000;
BA_REL_ "GenSigTimeoutTime" BU_SG_REL_ BBM SG_ 2147484698 TransmReverseDirectionSw_stat_IS 600;
BA_REL_ "GenSigFirstTimeoutTime" BU_SG_REL_ CIOM SG_ 2147484698 CabRoofSpotFeedback_Status 6000;
BA_REL_ "GenSigTimeoutTime" BU_SG_REL_ CIOM SG_ 2147484698 CabRoofSpotFeedback_Status 6000;
BA_REL_ "GenSigFirstTimeoutTime" BU_SG_REL_ CIOM SG_ 2147484698 CabBeaconLightFeedback_Status_IS 6000;
BA_REL_ "GenSigTimeoutTime" BU_SG_REL_ CIOM SG_ 2147484698 CabBeaconLightFeedback_Status_IS 6000;
BA_REL_ "GenSigFirstTimeoutTime" BU_SG_REL_ BBM SG_ 2147484698 CabBeaconLightFeedback_Status_IS 3000;
BA_REL_ "GenSigTimeoutTime" BU_SG_REL_ BBM SG_ 2147484698 CabBeaconLightFeedback_Status_IS 600;
BA_REL_ "GenSigFirstTimeoutTime" BU_SG_REL_ CIOM SG_ 2147484698 ExtraAxleSteeringFunctionStat_IS 6000;
BA_REL_ "GenSigTimeoutTime" BU_SG_REL_ CIOM SG_ 2147484698 ExtraAxleSteeringFunctionStat_IS 6000;
BA_REL_ "GenSigFirstTimeoutTime" BU_SG_REL_ BBM SG_ 2147484698 CabTiltLockStatus_ISig_4 3000;
BA_REL_ "GenSigTimeoutTime" BU_SG_REL_ BBM SG_ 2147484698 CabTiltLockStatus_ISig_4 600;
BA_REL_ "GenSigFirstTimeoutTime" BU_SG_REL_ IC3 SG_ 2147484698 CabTiltLockStatus_ISig_4 3000;
BA_REL_ "GenSigTimeoutTime" BU_SG_REL_ IC3 SG_ 2147484698 CabTiltLockStatus_ISig_4 600;
BA_REL_ "GenSigFirstTimeoutTime" BU_SG_REL_ IC3 SG_ 2147484698 PositionLightRearLamp_stat_ISig_ 3000;
BA_REL_ "GenSigTimeoutTime" BU_SG_REL_ IC3 SG_ 2147484698 PositionLightRearLamp_stat_ISig_ 600;
VAL_ 2147484474 StartupProhibitStatus_ISig_4 3 "InactiveActive_NotAvailable" 2 "InactiveActive_Error" 1 "InactiveActive_Active" 0 "InactiveActive_Inactive" ;
VAL_ 2147484474 RampLevelStatus_ISig_4 15 "RampLevelStatus_NotAvaiable" 14 "RampLevelStatus_ErrorIndicator" 13 "RampLevelStatus_NotDefined_05" 12 "RampLevelStatus_NotDefined_04" 11 "RampLevelStatus_NotDefined_03" 10 "RampLevelStatus_NotDefined_02" 9 "RampLevelStatus_NotDefined_01" 8 "RampLevelStatus_NotDefined" 7 "RampLevelStatus_RampLevelM7" 6 "RampLevelStatus_RampLevelM6" 5 "RampLevelStatus_RampLevelM5" 4 "RampLevelStatus_RampLevelM4" 3 "RampLevelStatus_RampLevelM3" 2 "RampLevelStatus_RampLevelM2" 1 "RampLevelStatus_RampLevelM1" 0 "RampLevelStatus_Inactive" ;
VAL_ 2147484474 KneelingInformation_ISig_4 15 "KneelingInformation_NotAvailable" 14 "KneelingInformation_ErrorIndicator" 13 "KneelingInformation_NotDefined_08" 12 "KneelingInformation_NotDefined_07" 11 "KneelingInformation_NotDefined_06" 10 "KneelingInformation_NotDefined_05" 9 "KneelingInformation_NotDefined_04" 8 "KneelingInformation_NotDefined_03" 7 "KneelingInformation_NotDefined_02" 6 "KneelingInformation_NotDefined_01" 5 "KneelingInformation_NotDefined" 4 "KneelingInformation_KneelingAborted" 3 "KneelingInformation_LiftingActiveVehicleIsLiftedDueToRcvrReq" 2 "KneelingInformation_KneelLevelReachedVehicleIsAtFixeKneelLvl" 1 "KneelingInformation_LoweringActiveTheVehIsLoweredDueToKneelReq" 0 "KneelingInformation_NotActiveTheKneelingFunctionIsNotActive" ;
VAL_ 2147484474 FrontAxleInBumperRange_ISig_4 3 "AxleInBumperRange_NotAvailable" 2 "AxleInBumperRange_ErrorIndicator" 1 "AxleInBumperRange_ActualLevelWithinBumperRange" 0 "AxleInBumperRange_ActualLevelOutOfBumperRange" ;
VAL_ 2147484474 FerryFunctionStatus_ISig_4 7 "FerryFunctionStatus_NotAvailable" 6 "FerryFunctionStatus_Error" 5 "FerryFunctionStatus_Spare_03" 4 "FerryFunctionStatus_Spare_02" 3 "FerryFunctionStatus_Spare_01" 2 "FerryFunctionStatus_FerryFunctionActiveLeveNotlReached" 1 "FerryFunctionStatus_FerryFunctionActiveLevelReached" 0 "FerryFunctionStatus_FerryFunctionNotActive" ;
VAL_ 2147484474 EngPtoConsumesTorque 3 "PtoTorqueRequest_NotAvailable" 2 "PtoTorqueRequest_Error" 1 "PtoTorqueRequest_PtoIsRequestingHighTorque" 0 "PtoTorqueRequest_PtoIsNotRequestingHighTorque" ;
VAL_ 2147484474 LiftingControlModeRearAxle_ISig_ 3 "InactiveActive_NotAvailable" 2 "InactiveActive_Error" 1 "InactiveActive_Active" 0 "InactiveActive_Inactive" ;
VAL_ 2147484474 KneelingStatusHMI_ISig_4 3 "KneelingStatusHMI_NotAvailable" 2 "KneelingStatusHMI_Error" 1 "KneelingStatusHMI_Active" 0 "KneelingStatusHMI_Inactive" ;
VAL_ 2147484474 SWEngineStop_rqst_ISig_4 7 "SWEngineStop_rqst_NotAvailable" 6 "SWEngineStop_rqst_Error" 5 "SWEngineStop_rqst_Spare_04" 4 "SWEngineStop_rqst_Spare_03" 3 "SWEngineStop_rqst_Spare_02" 2 "SWEngineStop_rqst_Spare_01" 1 "SWEngineStop_rqst_EngineStopRequested" 0 "SWEngineStop_rqst_EngineStopNotRequested" ;
VAL_ 2147484474 FrontEndPositionStatus_ISig_4 7 "EndPositionStatus_NotAvailable" 6 "EndPositionStatus_Error" 5 "EndPositionStatus_Reserved_01" 4 "EndPositionStatus_Reserved" 3 "EndPositionStatus_LiftingAndLoweringNotAllowed" 2 "EndPositionStatus_MinEndLevelReached" 1 "EndPositionStatus_MaxEndLevelReached" 0 "EndPositionStatus_NoEndLevelReached" ;
VAL_ 2147484474 LiftingControlModeFrontAxle_ISig 3 "InactiveActive_NotAvailable" 2 "InactiveActive_Error" 1 "InactiveActive_Active" 0 "InactiveActive_Inactive" ;
VAL_ 2147484474 UnevenLoadWarning_ISig_4 3 "Warning_NotAvailable" 2 "Warning_Error" 1 "Warning_Warning" 0 "Warning_NoWarning" ;
VAL_ 2147484474 RampHeightOutsideTargetRange_ISi 7 "HeightOutsideTargetRange_NotAvailable" 6 "HeightOutsideTargetRange_Error" 5 "HeightOutsideTargetRange_NotDefined_02" 4 "HeightOutsideTargetRange_NotDefined_01" 3 "HeightOutsideTargetRange_NotDefined" 2 "HeightOutsideTargetRange_ToHigh" 1 "HeightOutsideTargetRange_ToLow" 0 "HeightOutsideTargetRange_Inactive" ;
VAL_ 2147484474 DriveLevelPosUserInteraction_ISi 7 "DriveLevelPosUserInteraction_NotAvailable" 6 "DriveLevelPosUserInteraction_Error" 5 "DriveLevelPosUserInteraction_Spare3" 4 "DriveLevelPosUserInteraction_Spare2" 3 "DriveLevelPosUserInteraction_Spare1" 2 "DriveLevelPosUserInteraction_WarningDriveLevelPosNotSelected" 1 "DriveLevelPosUserInteraction_DriveLevelPositionNotSelected" 0 "DriveLevelPosUserInteraction_DriveLevelPositionSelected" ;
VAL_ 2147484474 RearEndPositionStatus_ISig_4 7 "EndPositionStatus_NotAvailable" 6 "EndPositionStatus_Error" 5 "EndPositionStatus_Reserved_01" 4 "EndPositionStatus_Reserved" 3 "EndPositionStatus_LiftingAndLoweringNotAllowed" 2 "EndPositionStatus_MinEndLevelReached" 1 "EndPositionStatus_MaxEndLevelReached" 0 "EndPositionStatus_NoEndLevelReached" ;
VAL_ 2147484474 ProhibitControlStatus_ISig_4 3 "InactiveActive_NotAvailable" 2 "InactiveActive_Error" 1 "InactiveActive_Active" 0 "InactiveActive_Inactive" ;
VAL_ 2147484474 ChangeKneelACK_ISig_4 3 "ChangeKneelACK_NotAvailable" 2 "ChangeKneelACK_Error" 1 "ChangeKneelACK_ChangeAcknowledged" 0 "ChangeKneelACK_NoAction" ;
VAL_ 2147484474 ParkBrakeApplicationMode2 15 "ParkBrakeApplicationMode2_NotAvailable" 14 "ParkBrakeApplicationMode2_Error" 13 "ParkBrakeApplicationMode2_Reserved5" 12 "ParkBrakeApplicationMode2_Reserved4" 11 "ParkBrakeApplicationMode2_Reserved3" 10 "ParkBrakeApplicationMode2_Reserved2" 9 "ParkBrakeApplicationMode2_Reserved1" 8 "ParkBrakeApplicationMode2_AutomaticcallyDoorOpen" 7 "ParkBrakeApplicationMode2_ParkBrakeBlending" 6 "ParkBrakeApplicationMode2_AutomaticallyHillHolder" 5 "ParkBrakeApplicationMode2_AutomaticInBackup" 4 "ParkBrakeApplicationMode2_ExternalDemand" 3 "ParkBrakeApplicationMode2_AutomaticallyKeyOff" 2 "ParkBrakeApplicationMode2_ManuallyAtStandstill" 1 "ParkBrakeApplicationMode2_ManuallyInDriving" 0 "ParkBrakeApplicationMode2_Idle" ;
VAL_ 2147484474 RollEndPositionStatus_ISig_4 7 "RollEndPositionStatus_NotAvailable" 6 "RollEndPositionStatus_Error" 5 "RollEndPositionStatus_Reserved_01" 4 "RollEndPositionStatus_Reserved" 3 "RollEndPositionStatus_NoRollingAllowed" 2 "RollEndPositionStatus_CounterClockwiseEndLevelReached" 1 "RollEndPositionStatus_ClockwiseEndLevelReached" 0 "RollEndPositionStatus_NoEndLevelReached" ;
VAL_ 2147484474 ParkBrakeReleaseMode2_ISig_4 15 "ParkBrakeReleaseMode2_NotAvailable" 14 "ParkBrakeReleaseMode2_Error" 13 "ParkBrakeReleaseMode2_Reserved7" 12 "ParkBrakeReleaseMode2_Reserved6" 11 "ParkBrakeReleaseMode2_Reserved5" 10 "ParkBrakeReleaseMode2_Reserved4" 9 "ParkBrakeReleaseMode2_Reserved3" 8 "ParkBrakeReleaseMode2_Reserved2" 7 "ParkBrakeReleaseMode2_Reserved1" 6 "ParkBrakeReleaseMode2_AutomaticallyinHillHolder" 5 "ParkBrakeReleaseMode2_AutomaticInBackup" 4 "ParkBrakeReleaseMode2_ExternalDemand" 3 "ParkBrakeReleaseMode2_AutomaticallyAccelPedal" 2 "ParkBrakeReleaseMode2_ManuallyAtStandstill" 1 "ParkBrakeReleaseMode2_ManuallyInDriving" 0 "ParkBrakeReleaseMode2_Idle" ;
VAL_ 2147484474 ECSStandbyAllowed_ISig_4 3 "FalseTrue_NotAvaiable" 2 "FalseTrue_Error" 1 "FalseTrue_True" 0 "FalseTrue_False" ;
VAL_ 2147484474 RearAxleInBumperRange_ISig_4 3 "AxleInBumperRange_NotAvailable" 2 "AxleInBumperRange_ErrorIndicator" 1 "AxleInBumperRange_ActualLevelWithinBumperRange" 0 "AxleInBumperRange_ActualLevelOutOfBumperRange" ;
VAL_ 2147485244 SavedUnit20_TrailerPosition 7 "TrailerPosition_NotAvailable" 6 "TrailerPosition_Error" 5 "TrailerPosition_Trailer5" 4 "TrailerPosition_Trailer4" 3 "TrailerPosition_Trailer3" 2 "TrailerPosition_Trailer2" 1 "TrailerPosition_Trailer1" 0 "TrailerPosition_NotConnected" ;
VAL_ 2147485242 SavedUnit19_TrailerPosition 7 "TrailerPosition_NotAvailable" 6 "TrailerPosition_Error" 5 "TrailerPosition_Trailer5" 4 "TrailerPosition_Trailer4" 3 "TrailerPosition_Trailer3" 2 "TrailerPosition_Trailer2" 1 "TrailerPosition_Trailer1" 0 "TrailerPosition_NotConnected" ;
VAL_ 2147485240 SavedUnit18_TrailerPosition 7 "TrailerPosition_NotAvailable" 6 "TrailerPosition_Error" 5 "TrailerPosition_Trailer5" 4 "TrailerPosition_Trailer4" 3 "TrailerPosition_Trailer3" 2 "TrailerPosition_Trailer2" 1 "TrailerPosition_Trailer1" 0 "TrailerPosition_NotConnected" ;
VAL_ 2147485238 SavedUnit17_TrailerPosition 7 "TrailerPosition_NotAvailable" 6 "TrailerPosition_Error" 5 "TrailerPosition_Trailer5" 4 "TrailerPosition_Trailer4" 3 "TrailerPosition_Trailer3" 2 "TrailerPosition_Trailer2" 1 "TrailerPosition_Trailer1" 0 "TrailerPosition_NotConnected" ;
VAL_ 2147485236 SavedUnit16_TrailerPosition 7 "TrailerPosition_NotAvailable" 6 "TrailerPosition_Error" 5 "TrailerPosition_Trailer5" 4 "TrailerPosition_Trailer4" 3 "TrailerPosition_Trailer3" 2 "TrailerPosition_Trailer2" 1 "TrailerPosition_Trailer1" 0 "TrailerPosition_NotConnected" ;
VAL_ 2147485234 SavedUnit15_TrailerPosition 7 "TrailerPosition_NotAvailable" 6 "TrailerPosition_Error" 5 "TrailerPosition_Trailer5" 4 "TrailerPosition_Trailer4" 3 "TrailerPosition_Trailer3" 2 "TrailerPosition_Trailer2" 1 "TrailerPosition_Trailer1" 0 "TrailerPosition_NotConnected" ;
VAL_ 2147485232 SavedUnit14_TrailerPosition 7 "TrailerPosition_NotAvailable" 6 "TrailerPosition_Error" 5 "TrailerPosition_Trailer5" 4 "TrailerPosition_Trailer4" 3 "TrailerPosition_Trailer3" 2 "TrailerPosition_Trailer2" 1 "TrailerPosition_Trailer1" 0 "TrailerPosition_NotConnected" ;
VAL_ 2147485224 SavedUnit13_TrailerPosition 7 "TrailerPosition_NotAvailable" 6 "TrailerPosition_Error" 5 "TrailerPosition_Trailer5" 4 "TrailerPosition_Trailer4" 3 "TrailerPosition_Trailer3" 2 "TrailerPosition_Trailer2" 1 "TrailerPosition_Trailer1" 0 "TrailerPosition_NotConnected" ;
VAL_ 2147485222 SavedUnit12_TrailerPosition 7 "TrailerPosition_NotAvailable" 6 "TrailerPosition_Error" 5 "TrailerPosition_Trailer5" 4 "TrailerPosition_Trailer4" 3 "TrailerPosition_Trailer3" 2 "TrailerPosition_Trailer2" 1 "TrailerPosition_Trailer1" 0 "TrailerPosition_NotConnected" ;
VAL_ 2147485220 SavedUnit11_TrailerPosition 7 "TrailerPosition_NotAvailable" 6 "TrailerPosition_Error" 5 "TrailerPosition_Trailer5" 4 "TrailerPosition_Trailer4" 3 "TrailerPosition_Trailer3" 2 "TrailerPosition_Trailer2" 1 "TrailerPosition_Trailer1" 0 "TrailerPosition_NotConnected" ;
VAL_ 2147485218 SavedUnit10_TrailerPosition 7 "TrailerPosition_NotAvailable" 6 "TrailerPosition_Error" 5 "TrailerPosition_Trailer5" 4 "TrailerPosition_Trailer4" 3 "TrailerPosition_Trailer3" 2 "TrailerPosition_Trailer2" 1 "TrailerPosition_Trailer1" 0 "TrailerPosition_NotConnected" ;
VAL_ 2147485216 SavedUnit9_TrailerPosition 7 "TrailerPosition_NotAvailable" 6 "TrailerPosition_Error" 5 "TrailerPosition_Trailer5" 4 "TrailerPosition_Trailer4" 3 "TrailerPosition_Trailer3" 2 "TrailerPosition_Trailer2" 1 "TrailerPosition_Trailer1" 0 "TrailerPosition_NotConnected" ;
VAL_ 2147485214 SavedUnit8_TrailerPosition 7 "TrailerPosition_NotAvailable" 6 "TrailerPosition_Error" 5 "TrailerPosition_Trailer5" 4 "TrailerPosition_Trailer4" 3 "TrailerPosition_Trailer3" 2 "TrailerPosition_Trailer2" 1 "TrailerPosition_Trailer1" 0 "TrailerPosition_NotConnected" ;
VAL_ 2147485212 SavedUnit7_TrailerPosition 7 "TrailerPosition_NotAvailable" 6 "TrailerPosition_Error" 5 "TrailerPosition_Trailer5" 4 "TrailerPosition_Trailer4" 3 "TrailerPosition_Trailer3" 2 "TrailerPosition_Trailer2" 1 "TrailerPosition_Trailer1" 0 "TrailerPosition_NotConnected" ;
VAL_ 2147485210 SavedUnit6_TrailerPosition 7 "TrailerPosition_NotAvailable" 6 "TrailerPosition_Error" 5 "TrailerPosition_Trailer5" 4 "TrailerPosition_Trailer4" 3 "TrailerPosition_Trailer3" 2 "TrailerPosition_Trailer2" 1 "TrailerPosition_Trailer1" 0 "TrailerPosition_NotConnected" ;
VAL_ 2147485208 SavedUnit5_TrailerPosition 7 "TrailerPosition_NotAvailable" 6 "TrailerPosition_Error" 5 "TrailerPosition_Trailer5" 4 "TrailerPosition_Trailer4" 3 "TrailerPosition_Trailer3" 2 "TrailerPosition_Trailer2" 1 "TrailerPosition_Trailer1" 0 "TrailerPosition_NotConnected" ;
VAL_ 2147485206 SavedUnit4_TrailerPosition 7 "TrailerPosition_NotAvailable" 6 "TrailerPosition_Error" 5 "TrailerPosition_Trailer5" 4 "TrailerPosition_Trailer4" 3 "TrailerPosition_Trailer3" 2 "TrailerPosition_Trailer2" 1 "TrailerPosition_Trailer1" 0 "TrailerPosition_NotConnected" ;
VAL_ 2147485204 SavedUnit3_TrailerPosition 7 "TrailerPosition_NotAvailable" 6 "TrailerPosition_Error" 5 "TrailerPosition_Trailer5" 4 "TrailerPosition_Trailer4" 3 "TrailerPosition_Trailer3" 2 "TrailerPosition_Trailer2" 1 "TrailerPosition_Trailer1" 0 "TrailerPosition_NotConnected" ;
VAL_ 2147485202 SavedUnit2_TrailerPosition 7 "TrailerPosition_NotAvailable" 6 "TrailerPosition_Error" 5 "TrailerPosition_Trailer5" 4 "TrailerPosition_Trailer4" 3 "TrailerPosition_Trailer3" 2 "TrailerPosition_Trailer2" 1 "TrailerPosition_Trailer1" 0 "TrailerPosition_NotConnected" ;
VAL_ 2147485200 SavedUnit1_TrailerPosition 7 "TrailerPosition_NotAvailable" 6 "TrailerPosition_Error" 5 "TrailerPosition_Trailer5" 4 "TrailerPosition_Trailer4" 3 "TrailerPosition_Trailer3" 2 "TrailerPosition_Trailer2" 1 "TrailerPosition_Trailer1" 0 "TrailerPosition_NotConnected" ;
VAL_ 2147485089 RenameTrailerAutoRqst_Request 3 "InactiveActive_NotAvailable" 2 "InactiveActive_Error" 1 "InactiveActive_Active" 0 "InactiveActive_Inactive" ;
VAL_ 2147485089 RenameTrailerAutoRqst_Position 7 "TrailerPosition_NotAvailable" 6 "TrailerPosition_Error" 5 "TrailerPosition_Trailer5" 4 "TrailerPosition_Trailer4" 3 "TrailerPosition_Trailer3" 2 "TrailerPosition_Trailer2" 1 "TrailerPosition_Trailer1" 0 "TrailerPosition_NotConnected" ;
VAL_ 2147484941 RSLAssistStatus 7 "RSLAssistStatus_NotAvailable" 6 "RSLAssistStatus_Error" 5 "RSLAssistStatus_Spare2" 4 "RSLAssistStatus_Spare1" 3 "RSLAssistStatus_PreActive" 2 "RSLAssistStatus_Active" 1 "RSLAssistStatus_Enable" 0 "RSLAssistStatus_Disable" ;
VAL_ 2147484919 DayOfWeek_stat_ISig_4 15 "DayOfWeek_NotAvailable" 14 "DayOfWeek_Error" 13 "DayOfWeek_Spare_7" 12 "DayOfWeek_Spare_6" 11 "DayOfWeek_Spare_5" 10 "DayOfWeek_Spare_4" 9 "DayOfWeek_Spare_3" 8 "DayOfWeek_Spare_2" 7 "DayOfWeek_Spare_1" 6 "DayOfWeek_Sunday" 5 "DayOfWeek_Saturday" 4 "DayOfWeek_Friday" 3 "DayOfWeek_Thursday" 2 "DayOfWeek_Wednesday" 1 "DayOfWeek_Tuesday" 0 "DayOfWeek_Monday" ;
VAL_ 2147484919 SelectedDaylightSaving_stat 3 "DaylightSaving_NotAvailable" 2 "DaylightSaving_Error" 1 "DaylightSaving_DaylightSaving" 0 "DaylightSaving_Standard" ;
VAL_ 2147484039 RequestedUpshiftDownshiftSteps 7 "RequestedUpshiftDownshiftSteps_NotAvailable" 6 "RequestedUpshiftDownshiftSteps_Error" 5 "RequestedUpshiftDownshiftSteps_NotDefined_01" 4 "RequestedUpshiftDownshiftSteps_NotDefined" 3 "RequestedUpshiftDownshiftSteps_ThreeSteps" 2 "RequestedUpshiftDownshiftSteps_TwoSteps" 1 "RequestedUpshiftDownshiftSteps_OneStep" 0 "RequestedUpshiftDownshiftSteps_NoRequest" ;
VAL_ 2147484039 GearLeverPosition_ISig_4 15 "GearLeverPosition_NotAvailable" 14 "GearLeverPosition_Error" 13 "GearLeverPosition_SpareValue_06" 12 "GearLeverPosition_SpareValue_05" 11 "GearLeverPosition_SpareValue_04" 10 "GearLeverPosition_SpareValue_03" 9 "GearLeverPosition_SpareValue_02" 8 "GearLeverPosition_SpareValue_01" 7 "GearLeverPosition_SpareValue" 6 "GearLeverPosition_SEG6" 5 "GearLeverPosition_LowGear" 4 "GearLeverPosition_Manual" 3 "GearLeverPosition_Automatic" 2 "GearLeverPosition_Neutral" 1 "GearLeverPosition_Reverse" 0 "GearLeverPosition_GearFoldedAway" ;
VAL_ 2147484039 DownShiftRequest 3 "DownShiftRequest_NotAvailable" 2 "DownShiftRequest_Error" 1 "DownShiftRequest_RequestToDownshiftOneGear" 0 "DownShiftRequest_NoRequest" ;
VAL_ 2147484039 UpShiftRequest 3 "UpShiftRequest_NotAvailable" 2 "UpShiftRequest_Error" 1 "UpShiftRequest_RequestToDoUpshiftOneStep" 0 "UpShiftRequest_NoRequest" ;
VAL_ 2147484039 LimpHomeSwitch_stat 3 "OffOn_NotAvailable" 2 "OffOn_Error" 1 "OffOn_On" 0 "OffOn_Off" ;
VAL_ 2147484039 RequestForHighestGearRatio 3 "Request_NotAvailable" 2 "Request_Error" 1 "Request_RequestActive" 0 "Request_NotRequested" ;
VAL_ 2147484039 EconomyPowerSwitch_stat 3 "OffOn_NotAvailable" 2 "OffOn_Error" 1 "OffOn_On" 0 "OffOn_Off" ;
VAL_ 2147484969 CalDataLoadP5_VehicleID 7 "VehicleID_NotAvailable" 6 "VehicleID_Error" 5 "VehicleID_Trailer5" 4 "VehicleID_Trailer4" 3 "VehicleID_Trailer3" 2 "VehicleID_Trailer2" 1 "VehicleID_Trailer1" 0 "VehicleID_Truck" ;
VAL_ 2147484969 CalDataLoadP5_AxleID 15 "AxleIdEnum_NotAvailable" 14 "AxleIdEnum_Error" 13 "AxleIdEnum_Reserved4" 12 "AxleIdEnum_Reserved3" 11 "AxleIdEnum_Reserved2" 10 "AxleIdEnum_Reserved1" 9 "AxleIdEnum_AxleID10" 8 "AxleIdEnum_AxleID9" 7 "AxleIdEnum_AxleID8" 6 "AxleIdEnum_AxleID7" 5 "AxleIdEnum_AxleID6" 4 "AxleIdEnum_AxleID5" 3 "AxleIdEnum_AxleID4" 2 "AxleIdEnum_AxleID3" 1 "AxleIdEnum_AxleID2" 0 "AxleIdEnum_AxleID1" ;
VAL_ 2147484968 CalDataLoadP4_AxleID 15 "AxleIdEnum_NotAvailable" 14 "AxleIdEnum_Error" 13 "AxleIdEnum_Reserved4" 12 "AxleIdEnum_Reserved3" 11 "AxleIdEnum_Reserved2" 10 "AxleIdEnum_Reserved1" 9 "AxleIdEnum_AxleID10" 8 "AxleIdEnum_AxleID9" 7 "AxleIdEnum_AxleID8" 6 "AxleIdEnum_AxleID7" 5 "AxleIdEnum_AxleID6" 4 "AxleIdEnum_AxleID5" 3 "AxleIdEnum_AxleID4" 2 "AxleIdEnum_AxleID3" 1 "AxleIdEnum_AxleID2" 0 "AxleIdEnum_AxleID1" ;
VAL_ 2147484968 CalDataLoadP4_VehicleID 7 "VehicleID_NotAvailable" 6 "VehicleID_Error" 5 "VehicleID_Trailer5" 4 "VehicleID_Trailer4" 3 "VehicleID_Trailer3" 2 "VehicleID_Trailer2" 1 "VehicleID_Trailer1" 0 "VehicleID_Truck" ;
VAL_ 2147484967 CalDataLoadP3_VehicleID 7 "VehicleID_NotAvailable" 6 "VehicleID_Error" 5 "VehicleID_Trailer5" 4 "VehicleID_Trailer4" 3 "VehicleID_Trailer3" 2 "VehicleID_Trailer2" 1 "VehicleID_Trailer1" 0 "VehicleID_Truck" ;
VAL_ 2147484967 CalDataLoadP3_AxleID 15 "AxleIdEnum_NotAvailable" 14 "AxleIdEnum_Error" 13 "AxleIdEnum_Reserved4" 12 "AxleIdEnum_Reserved3" 11 "AxleIdEnum_Reserved2" 10 "AxleIdEnum_Reserved1" 9 "AxleIdEnum_AxleID10" 8 "AxleIdEnum_AxleID9" 7 "AxleIdEnum_AxleID8" 6 "AxleIdEnum_AxleID7" 5 "AxleIdEnum_AxleID6" 4 "AxleIdEnum_AxleID5" 3 "AxleIdEnum_AxleID4" 2 "AxleIdEnum_AxleID3" 1 "AxleIdEnum_AxleID2" 0 "AxleIdEnum_AxleID1" ;
VAL_ 2147484966 CalDataLoadP2_AxleID 15 "AxleIdEnum_NotAvailable" 14 "AxleIdEnum_Error" 13 "AxleIdEnum_Reserved4" 12 "AxleIdEnum_Reserved3" 11 "AxleIdEnum_Reserved2" 10 "AxleIdEnum_Reserved1" 9 "AxleIdEnum_AxleID10" 8 "AxleIdEnum_AxleID9" 7 "AxleIdEnum_AxleID8" 6 "AxleIdEnum_AxleID7" 5 "AxleIdEnum_AxleID6" 4 "AxleIdEnum_AxleID5" 3 "AxleIdEnum_AxleID4" 2 "AxleIdEnum_AxleID3" 1 "AxleIdEnum_AxleID2" 0 "AxleIdEnum_AxleID1" ;
VAL_ 2147484966 CalDataLoadP2_VehicleID 7 "VehicleID_NotAvailable" 6 "VehicleID_Error" 5 "VehicleID_Trailer5" 4 "VehicleID_Trailer4" 3 "VehicleID_Trailer3" 2 "VehicleID_Trailer2" 1 "VehicleID_Trailer1" 0 "VehicleID_Truck" ;
VAL_ 2147484965 CalDataLoadP1_AxleID 15 "AxleIdEnum_NotAvailable" 14 "AxleIdEnum_Error" 13 "AxleIdEnum_Reserved4" 12 "AxleIdEnum_Reserved3" 11 "AxleIdEnum_Reserved2" 10 "AxleIdEnum_Reserved1" 9 "AxleIdEnum_AxleID10" 8 "AxleIdEnum_AxleID9" 7 "AxleIdEnum_AxleID8" 6 "AxleIdEnum_AxleID7" 5 "AxleIdEnum_AxleID6" 4 "AxleIdEnum_AxleID5" 3 "AxleIdEnum_AxleID4" 2 "AxleIdEnum_AxleID3" 1 "AxleIdEnum_AxleID2" 0 "AxleIdEnum_AxleID1" ;
VAL_ 2147484965 CalDataLoadP1_VehicleID 7 "VehicleID_NotAvailable" 6 "VehicleID_Error" 5 "VehicleID_Trailer5" 4 "VehicleID_Trailer4" 3 "VehicleID_Trailer3" 2 "VehicleID_Trailer2" 1 "VehicleID_Trailer1" 0 "VehicleID_Truck" ;
VAL_ 2147484701 AlarmClockAlarms_stat_Mode_ISig_ 3 "AlarmClkMode_Spare" 2 "AlarmClkMode_Timer" 1 "AlarmClkMode_Recurrent" 0 "AlarmClkMode_OneTime" ;
VAL_ 2147484701 AlarmClockAlarms_stat_Type_ISig_ 7 "AlarmClkType_NotAvailable" 6 "AlarmClkType_Error" 5 "AlarmClkType_Reserved_02" 4 "AlarmClkType_Reserved_01" 3 "AlarmClkType_Reserved" 2 "AlarmClkType_Radio" 1 "AlarmClkType_Buzzer" 0 "AlarmClkType_NoAudibleNotification" ;
VAL_ 2147484701 AlarmClockAlarms_stat_ID_ISig_4 127 "AlarmClkID_NotAvailable" 126 "AlarmClkID_Error" 10 "AlarmClkID_Alarm10" 9 "AlarmClkID_Alarm9" 8 "AlarmClkID_Alarm8" 7 "AlarmClkID_Alarm7" 6 "AlarmClkID_Alarm6" 5 "AlarmClkID_Alarm5" 4 "AlarmClkID_Alarm4" 3 "AlarmClkID_Alarm3" 2 "AlarmClkID_Alarm2" 1 "AlarmClkID_Alarm1" 0 "AlarmClkID_NotUsed" ;
VAL_ 2147484701 AlarmClockAlarms_stat_Stat_ISig_ 3 "AlarmClkStat2_Snoozed" 2 "AlarmClkStat2_Ringing" 1 "AlarmClkStat2_Active" 0 "AlarmClkStat2_Inactive" ;
VAL_ 2147484701 AlmClkCurAlarm_stat_Stat 3 "AlarmClkStat_Spare" 2 "AlarmClkStat_NoUsed" 1 "AlarmClkStat_Active" 0 "AlarmClkStat_Inactive" ;
VAL_ 2147484701 AlmClkCurAlarm_stat_ID 127 "AlarmClkID_NotAvailable" 126 "AlarmClkID_Error" 10 "AlarmClkID_Alarm10" 9 "AlarmClkID_Alarm9" 8 "AlarmClkID_Alarm8" 7 "AlarmClkID_Alarm7" 6 "AlarmClkID_Alarm6" 5 "AlarmClkID_Alarm5" 4 "AlarmClkID_Alarm4" 3 "AlarmClkID_Alarm3" 2 "AlarmClkID_Alarm2" 1 "AlarmClkID_Alarm1" 0 "AlarmClkID_NotUsed" ;
VAL_ 2147484701 AlmClkCurAlarm_stat_Type 7 "AlarmClkType_NotAvailable" 6 "AlarmClkType_Error" 5 "AlarmClkType_Reserved_02" 4 "AlarmClkType_Reserved_01" 3 "AlarmClkType_Reserved" 2 "AlarmClkType_Radio" 1 "AlarmClkType_Buzzer" 0 "AlarmClkType_NoAudibleNotification" ;
VAL_ 2147484743 ParkHeaterTimerReleased_stat_ISi 3 "DisableEnable_NotAvailable" 2 "DisableEnable_Error" 1 "DisableEnable_Enable" 0 "DisableEnable_Disable" ;
VAL_ 2147484743 PHTimerRqstAck_CurrentOp_ISig_4 3 "CurrentOp_NotAvailable" 2 "CurrentOp_Disabled" 1 "CurrentOp_TemporaryStopped" 0 "CurrentOp_Running" ;
VAL_ 2147484743 PHTimerRqstAck_DayOfWeekRq_ISig_ 15 "DayOfWeekRq_NotAvailable" 14 "DayOfWeekRq_Error" 13 "DayOfWeekRq_Spare_7" 12 "DayOfWeekRq_Spare_6" 11 "DayOfWeekRq_Spare_5" 10 "DayOfWeekRq_Spare_4" 9 "DayOfWeekRq_Spare_3" 8 "DayOfWeekRq_Spare_2" 7 "DayOfWeekRq_NoDay" 6 "DayOfWeekRq_Sunday" 5 "DayOfWeekRq_Saturday" 4 "DayOfWeekRq_Friday" 3 "DayOfWeekRq_Thursday" 2 "DayOfWeekRq_Wednesday" 1 "DayOfWeekRq_Tuesday" 0 "DayOfWeekRq_Monday" ;
VAL_ 2147484743 AlarmClockNotification_Stat_ISig 3 "AlarmClkStat_Spare" 2 "AlarmClkStat_NoUsed" 1 "AlarmClkStat_Active" 0 "AlarmClkStat_Inactive" ;
VAL_ 2147484743 AlarmClockNotification_Type_ISig 7 "AlarmClkType_NotAvailable" 6 "AlarmClkType_Error" 5 "AlarmClkType_Reserved_02" 4 "AlarmClkType_Reserved_01" 3 "AlarmClkType_Reserved" 2 "AlarmClkType_Radio" 1 "AlarmClkType_Buzzer" 0 "AlarmClkType_NoAudibleNotification" ;
VAL_ 2147484743 AlarmClockNotification_ID_ISig_4 127 "AlarmClkID_NotAvailable" 126 "AlarmClkID_Error" 10 "AlarmClkID_Alarm10" 9 "AlarmClkID_Alarm9" 8 "AlarmClkID_Alarm8" 7 "AlarmClkID_Alarm7" 6 "AlarmClkID_Alarm6" 5 "AlarmClkID_Alarm5" 4 "AlarmClkID_Alarm4" 3 "AlarmClkID_Alarm3" 2 "AlarmClkID_Alarm2" 1 "AlarmClkID_Alarm1" 0 "AlarmClkID_NotUsed" ;
VAL_ 2147484964 LoadIndCalWarning_Movement 3 "InactiveActive_NotAvailable" 2 "InactiveActive_Error" 1 "InactiveActive_Active" 0 "InactiveActive_Inactive" ;
VAL_ 2147484964 LoadIndCalWarning_LiftedAxle 3 "InactiveActive_NotAvailable" 2 "InactiveActive_Error" 1 "InactiveActive_Active" 0 "InactiveActive_Inactive" ;
VAL_ 2147484964 LoadIndCalWarning_LowSupplyPress 3 "InactiveActive_NotAvailable" 2 "InactiveActive_Error" 1 "InactiveActive_Active" 0 "InactiveActive_Inactive" ;
VAL_ 2147484964 LoadIndCalWarning_PBrakeApplied 3 "InactiveActive_NotAvailable" 2 "InactiveActive_Error" 1 "InactiveActive_Active" 0 "InactiveActive_Inactive" ;
VAL_ 2147484964 LoadIndCalWarning_SBrakesApplied 3 "InactiveActive_NotAvailable" 2 "InactiveActive_Error" 1 "InactiveActive_Active" 0 "InactiveActive_Inactive" ;
VAL_ 2147484964 LoadIndCalWarning_HighInclin 3 "InactiveActive_NotAvailable" 2 "InactiveActive_Error" 1 "InactiveActive_Active" 0 "InactiveActive_Inactive" ;
VAL_ 2147484964 LoadIndCalWarning_GearNotNeutral 3 "InactiveActive_NotAvailable" 2 "InactiveActive_Error" 1 "InactiveActive_Active" 0 "InactiveActive_Inactive" ;
VAL_ 2147484964 LoadIndCalWarning_HighLoadDelta 3 "InactiveActive_NotAvailable" 2 "InactiveActive_Error" 1 "InactiveActive_Active" 0 "InactiveActive_Inactive" ;
VAL_ 2147485064 WasherFluidLevel_ISig_4 7 "WasherFluidLevel_NotAvailable" 6 "WasherFluidLevel_ErrorIndicator" 5 "WasherFluidLevel_Spare_02" 4 "WasherFluidLevel_Spare_01" 3 "WasherFluidLevel_Spare" 2 "WasherFluidLevel_Level2" 1 "WasherFluidLevel_Level1" 0 "WasherFluidLevel_Level0" ;
VAL_ 2147485064 EngSpeedGreenAreaMode_ISig_4 7 "EngSpeedGreenAreaMode_NotAvailable" 6 "EngSpeedGreenAreaMode_Error" 5 "EngSpeedGreenAreaMode_Spare3" 4 "EngSpeedGreenAreaMode_Spare2" 3 "EngSpeedGreenAreaMode_Spare1" 2 "EngSpeedGreenAreaMode_Above" 1 "EngSpeedGreenAreaMode_Within" 0 "EngSpeedGreenAreaMode_Below" ;
VAL_ 2147484698 CabRoofSignLightFeedback_stat 3 "OffOn_NotAvailable" 2 "OffOn_Error" 1 "OffOn_On" 0 "OffOn_Off" ;
VAL_ 2147484698 TemporaryRSLStatus 3 "InactiveActive_NotAvailable" 2 "InactiveActive_Error" 1 "InactiveActive_Active" 0 "InactiveActive_Inactive" ;
VAL_ 2147484698 CabExtraSideWrknLightFdbk_stat_I 3 "OffOn_NotAvailable" 2 "OffOn_Error" 1 "OffOn_On" 0 "OffOn_Off" ;
VAL_ 2147484698 CabWrknLightChassisFdbk_stat_ISi 3 "OffOn_NotAvailable" 2 "OffOn_Error" 1 "OffOn_On" 0 "OffOn_Off" ;
VAL_ 2147484698 CabTrailerBodyLgthnFdbk_stat 3 "OffOn_NotAvailable" 2 "OffOn_Error" 1 "OffOn_On" 0 "OffOn_Off" ;
VAL_ 2147484698 DiffLockInterWhlStatusSplitBox_I 3 "DisengageEngage_NotAvailable" 2 "DisengageEngage_Error" 1 "DisengageEngage_Engage" 0 "DisengageEngage_Disengage" ;
VAL_ 2147484698 BodyOrCabWorkingLightFdbk_stat_I 3 "OffOn_NotAvailable" 2 "OffOn_Error" 1 "OffOn_On" 0 "OffOn_Off" ;
VAL_ 2147484698 CabFrontSpotFeedback_Status 3 "OffOn_NotAvailable" 2 "OffOn_Error" 1 "OffOn_On" 0 "OffOn_Off" ;
VAL_ 2147484698 CabTiltEnableStatus 3 "DisableEnable_NotAvailable" 2 "DisableEnable_Error" 1 "DisableEnable_Enable" 0 "DisableEnable_Disable" ;
VAL_ 2147484698 TransmReverseDirectionSw_stat_IS 3 "OffOn_NotAvailable" 2 "OffOn_Error" 1 "OffOn_On" 0 "OffOn_Off" ;
VAL_ 2147484698 CabRoofSpotFeedback_Status 3 "OffOn_NotAvailable" 2 "OffOn_Error" 1 "OffOn_On" 0 "OffOn_Off" ;
VAL_ 2147484698 CabBeaconLightFeedback_Status_IS 3 "OffOn_NotAvailable" 2 "OffOn_Error" 1 "OffOn_On" 0 "OffOn_Off" ;
VAL_ 2147484698 ExtraAxleSteeringFunctionStat_IS 7 "RearAxleSteeringFunctionStatus_NotAvailable" 6 "RearAxleSteeringFunctionStatus_Error" 5 "RearAxleSteeringFunctionStatus_SpareValue_01" 4 "RearAxleSteeringFunctionStatus_SpareValue" 3 "RearAxleSteeringFunctionStatus_ActiveFailureMode" 2 "RearAxleSteeringFunctionStatus_PassiveFailureMode" 1 "RearAxleSteeringFunctionStatus_Active" 0 "RearAxleSteeringFunctionStatus_NotActive" ;
VAL_ 2147484698 CabTiltLockStatus_ISig_4 3 "UnlockedLocked_NotAvailable" 2 "UnlockedLocked_Error" 1 "UnlockedLocked_Locked" 0 "UnlockedLocked_Unlocked" ;
VAL_ 2147484698 PositionLightRearLamp_stat_ISig_ 7 "LampCheckLeftRight_stat_NotAvailable" 6 "LampCheckLeftRight_stat_Error" 5 "LampCheckLeftRight_stat_Spare" 4 "LampCheckLeftRight_stat_TestedLeftAndRightLampNOK" 3 "LampCheckLeftRight_stat_TestedRightLampNOK" 2 "LampCheckLeftRight_stat_TestedLeftLampNOK" 1 "LampCheckLeftRight_stat_TestedLampOK" 0 "LampCheckLeftRight_stat_NotTested" ;
SIG_GROUP_ 2147485244 SavedUnit20_sg 1 : SavedUnit20_TrailerName SavedUnit20_TrailerPosition;
SIG_GROUP_ 2147485242 SavedUnit19_sg 1 : SavedUnit19_TrailerName SavedUnit19_TrailerPosition;
SIG_GROUP_ 2147485240 SavedUnit18_sg 1 : SavedUnit18_TrailerPosition SavedUnit18_TrailerName;
SIG_GROUP_ 2147485238 SavedUnit17_sg 1 : SavedUnit17_TrailerPosition SavedUnit17_TrailerName;
SIG_GROUP_ 2147485236 SavedUnit16_sg 1 : SavedUnit16_TrailerName SavedUnit16_TrailerPosition;
SIG_GROUP_ 2147485234 SavedUnit15_sg 1 : SavedUnit15_TrailerName SavedUnit15_TrailerPosition;
SIG_GROUP_ 2147485232 SavedUnit14_sg 1 : SavedUnit14_TrailerPosition SavedUnit14_TrailerName;
SIG_GROUP_ 2147485224 SavedUnit13_sg 1 : SavedUnit13_TrailerPosition SavedUnit13_TrailerName;
SIG_GROUP_ 2147485222 SavedUnit12_sg 1 : SavedUnit12_TrailerName SavedUnit12_TrailerPosition;
SIG_GROUP_ 2147485220 SavedUnit11_sg 1 : SavedUnit11_TrailerPosition SavedUnit11_TrailerName;
SIG_GROUP_ 2147485218 SavedUnit10_sg 1 : SavedUnit10_TrailerName SavedUnit10_TrailerPosition;
SIG_GROUP_ 2147485216 SavedUnit9_sg 1 : SavedUnit9_TrailerName SavedUnit9_TrailerPosition;
SIG_GROUP_ 2147485214 SavedUnit8_sg 1 : SavedUnit8_TrailerName SavedUnit8_TrailerPosition;
SIG_GROUP_ 2147485212 SavedUnit7_sg 1 : SavedUnit7_TrailerPosition SavedUnit7_TrailerName;
SIG_GROUP_ 2147485210 SavedUnit6_sg 1 : SavedUnit6_TrailerPosition SavedUnit6_TrailerName;
SIG_GROUP_ 2147485208 SavedUnit5_sg 1 : SavedUnit5_TrailerName SavedUnit5_TrailerPosition;
SIG_GROUP_ 2147485206 SavedUnit4_sg 1 : SavedUnit4_TrailerPosition SavedUnit4_TrailerName;
SIG_GROUP_ 2147485204 SavedUnit3_sg 1 : SavedUnit3_TrailerPosition SavedUnit3_TrailerName;
SIG_GROUP_ 2147485202 SavedUnit2_sg 1 : SavedUnit2_TrailerName SavedUnit2_TrailerPosition;
SIG_GROUP_ 2147485200 SavedUnit1_sg 1 : SavedUnit1_TrailerPosition SavedUnit1_TrailerName;
SIG_GROUP_ 2147485089 RenameTrailerAutoRqst_sg 1 : RenameTrailerAutoRqst_TrailerVIN RenameTrailerAutoRqst_Request RenameTrailerAutoRqst_Position;
SIG_GROUP_ 2147484969 CalDataLoadP5_sg 1 : CalDataLoadP5_ScaleLoad CalDataLoadP5_UncalLoad CalDataLoadP5_YearUTC CalDataLoadP5_VehicleID CalDataLoadP5_AxleID CalDataLoadP5_DayUTC CalDataLoadP5_HoursUTC CalDataLoadP5_MinutesUTC CalDataLoadP5_QF CalDataLoadP5_MonthUTC;
SIG_GROUP_ 2147484968 CalDataLoadP4_sg 1 : CalDataLoadP4_DayUTC CalDataLoadP4_ScaleLoad CalDataLoadP4_YearUTC CalDataLoadP4_AxleID CalDataLoadP4_UncalLoad CalDataLoadP4_VehicleID CalDataLoadP4_MinutesUTC CalDataLoadP4_HoursUTC CalDataLoadP4_MonthUTC CalDataLoadP4_QF;
SIG_GROUP_ 2147484967 CalDataLoadP3_sg 1 : CalDataLoadP3_HoursUTC CalDataLoadP3_YearUTC CalDataLoadP3_MonthUTC CalDataLoadP3_DayUTC CalDataLoadP3_MinutesUTC CalDataLoadP3_QF CalDataLoadP3_VehicleID CalDataLoadP3_UncalLoad CalDataLoadP3_AxleID CalDataLoadP3_ScaleLoad;
SIG_GROUP_ 2147484966 CalDataLoadP2_sg 1 : CalDataLoadP2_MinutesUTC CalDataLoadP2_AxleID CalDataLoadP2_YearUTC CalDataLoadP2_UncalLoad CalDataLoadP2_DayUTC CalDataLoadP2_MonthUTC CalDataLoadP2_VehicleID CalDataLoadP2_QF CalDataLoadP2_HoursUTC CalDataLoadP2_ScaleLoad;
SIG_GROUP_ 2147484965 CalDataLoadP1_sg 1 : CalDataLoadP1_ScaleLoad CalDataLoadP1_YearUTC CalDataLoadP1_AxleID CalDataLoadP1_MonthUTC CalDataLoadP1_HoursUTC CalDataLoadP1_VehicleID CalDataLoadP1_UncalLoad CalDataLoadP1_QF CalDataLoadP1_DayUTC CalDataLoadP1_MinutesUTC;
SIG_GROUP_ 2147484701 AlmClkCurAlarm_stat_sg 1 : AlmClkCurAlarm_stat_SetMin AlmClkCurAlarm_stat_Stat AlmClkCurAlarm_stat_ID AlmClkCurAlarm_stat_Type AlmClkCurAlarm_stat_SetHr;
SIG_GROUP_ 2147484701 AlarmClockAlarms_stat_sg_ISig_4 1 : AlarmClockAlarms_stat_Mode_ISig_ AlarmClockAlarms_stat_Type_ISig_ AlarmClockAlarms_stat_DaySet_ISi AlarmClockAlarms_stat_ID_ISig_4 AlarmClockAlarms_stat_Stat_ISig_ AlarmClockAlarms_stat_SetMin_ISi AlarmClockAlarms_stat_SetHr_ISig;
SIG_GROUP_ 2147484743 AlarmClockNotification_sg_ISig_4 1 : AlarmClockNotification_Stat_ISig AlarmClockNotification_Type_ISig AlarmClockNotification_ID_ISig_4;
SIG_GROUP_ 2147484743 PHTimerRqstAck_sg_ISig_4 1 : PHTimerRqstAck_Hours_ISig_4 PHTimerRqstAck_CurrentOp_ISig_4 PHTimerRqstAck_DayOfWeekRq_ISig_ PHTimerRqstAck_Minutes_ISig_4;
SIG_GROUP_ 2147484964 LoadIndCalWarning_sg 1 : LoadIndCalWarning_Movement LoadIndCalWarning_LiftedAxle LoadIndCalWarning_LowSupplyPress LoadIndCalWarning_PBrakeApplied LoadIndCalWarning_SBrakesApplied LoadIndCalWarning_HighInclin LoadIndCalWarning_GearNotNeutral LoadIndCalWarning_HighLoadDelta;
